VERSION ""

NS_ :

BS_:

BU_: CLU_MM H_U_MM HS_M CGW

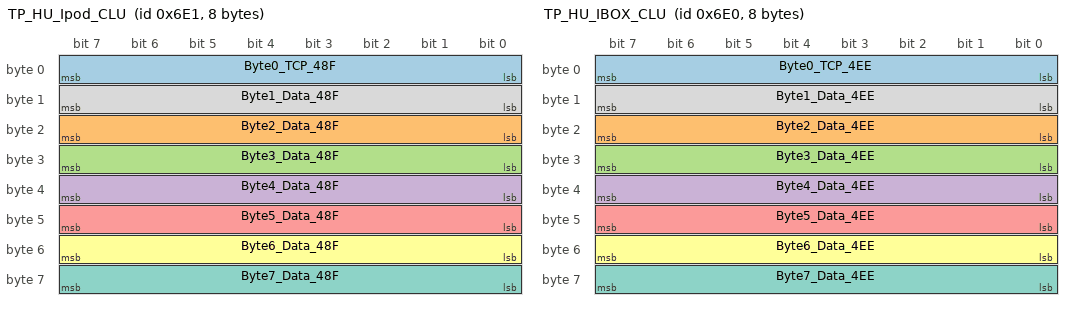
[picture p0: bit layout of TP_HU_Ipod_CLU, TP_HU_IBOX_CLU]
BO_ 1761 TP_HU_Ipod_CLU: 8 H_U_MM
 SG_ Byte0_TCP_48F : 0|8@1+ (1,0) [0|0] ""  CLU_MM
 SG_ Byte2_Data_48F : 16|8@1+ (1,0) [0|0] ""  CLU_MM
 SG_ Byte3_Data_48F : 24|8@1+ (1,0) [0|0] ""  CLU_MM
 SG_ Byte4_Data_48F : 32|8@1+ (1,0) [0|0] ""  CLU_MM
 SG_ Byte5_Data_48F : 40|8@1+ (1,0) [0|0] ""  CLU_MM
 SG_ Byte6_Data_48F : 48|8@1+ (1,0) [0|0] ""  CLU_MM
 SG_ Byte7_Data_48F : 56|8@1+ (1,0) [0|0] ""  CLU_MM
 SG_ Byte1_Data_48F : 8|8@1+ (1,0) [0|0] ""  CLU_MM

BO_ 1760 TP_HU_IBOX_CLU: 8 H_U_MM
 SG_ Byte0_TCP_4EE : 0|8@1+ (1,0) [0|0] ""  CLU_MM
 SG_ Byte2_Data_4EE : 16|8@1+ (1,0) [0|0] ""  CLU_MM
 SG_ Byte3_Data_4EE : 24|8@1+ (1,0) [0|0] ""  CLU_MM
 SG_ Byte4_Data_4EE : 32|8@1+ (1,0) [0|0] ""  CLU_MM
 SG_ Byte5_Data_4EE : 40|8@1+ (1,0) [0|0] ""  CLU_MM
 SG_ Byte6_Data_4EE : 48|8@1+ (1,0) [0|0] ""  CLU_MM
 SG_ Byte7_Data_4EE : 56|8@1+ (1,0) [0|0] ""  CLU_MM
 SG_ Byte1_Data_4EE : 8|8@1+ (1,0) [0|0] ""  CLU_MM

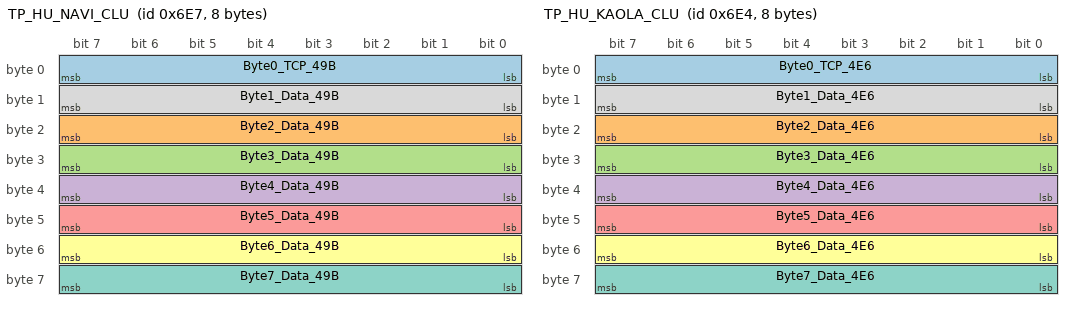
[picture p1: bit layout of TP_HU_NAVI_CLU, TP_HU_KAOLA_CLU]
BO_ 1767 TP_HU_NAVI_CLU: 8 H_U_MM
 SG_ Byte0_TCP_49B : 0|8@1+ (1,0) [0|0] ""  CLU_MM
 SG_ Byte2_Data_49B : 16|8@1+ (1,0) [0|0] ""  CLU_MM
 SG_ Byte3_Data_49B : 24|8@1+ (1,0) [0|0] ""  CLU_MM
 SG_ Byte4_Data_49B : 32|8@1+ (1,0) [0|0] ""  CLU_MM
 SG_ Byte5_Data_49B : 40|8@1+ (1,0) [0|0] ""  CLU_MM
 SG_ Byte6_Data_49B : 48|8@1+ (1,0) [0|0] ""  CLU_MM
 SG_ Byte7_Data_49B : 56|8@1+ (1,0) [0|0] ""  CLU_MM
 SG_ Byte1_Data_49B : 8|8@1+ (1,0) [0|0] ""  CLU_MM

BO_ 1764 TP_HU_KAOLA_CLU: 8 H_U_MM
 SG_ Byte0_TCP_4E6 : 0|8@1+ (1,0) [0|0] ""  CLU_MM
 SG_ Byte2_Data_4E6 : 16|8@1+ (1,0) [0|0] ""  CLU_MM
 SG_ Byte3_Data_4E6 : 24|8@1+ (1,0) [0|0] ""  CLU_MM
 SG_ Byte4_Data_4E6 : 32|8@1+ (1,0) [0|0] ""  CLU_MM
 SG_ Byte5_Data_4E6 : 40|8@1+ (1,0) [0|0] ""  CLU_MM
 SG_ Byte6_Data_4E6 : 48|8@1+ (1,0) [0|0] ""  CLU_MM
 SG_ Byte7_Data_4E6 : 56|8@1+ (1,0) [0|0] ""  CLU_MM
 SG_ Byte1_Data_4E6 : 8|8@1+ (1,0) [0|0] ""  CLU_MM

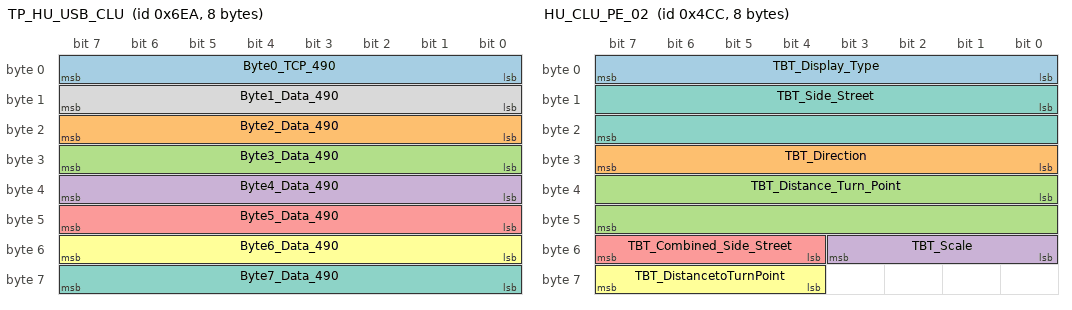
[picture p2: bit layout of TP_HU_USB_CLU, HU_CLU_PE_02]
BO_ 1770 TP_HU_USB_CLU: 8 H_U_MM
 SG_ Byte0_TCP_490 : 0|8@1+ (1,0) [0|0] ""  CLU_MM
 SG_ Byte2_Data_490 : 16|8@1+ (1,0) [0|0] ""  CLU_MM
 SG_ Byte3_Data_490 : 24|8@1+ (1,0) [0|0] ""  CLU_MM
 SG_ Byte4_Data_490 : 32|8@1+ (1,0) [0|0] ""  CLU_MM
 SG_ Byte5_Data_490 : 40|8@1+ (1,0) [0|0] ""  CLU_MM
 SG_ Byte6_Data_490 : 48|8@1+ (1,0) [0|0] ""  CLU_MM
 SG_ Byte7_Data_490 : 56|8@1+ (1,0) [0|0] ""  CLU_MM
 SG_ Byte1_Data_490 : 8|8@1+ (1,0) [0|0] ""  CLU_MM

BO_ 1228 HU_CLU_PE_02: 8 H_U_MM
 SG_ TBT_Display_Type : 0|8@1+ (1,0) [0|0] ""  CLU_MM
 SG_ TBT_Direction : 24|8@1+ (7.5,0) [0|352.5] "Degree"  CLU_MM
 SG_ TBT_Distance_Turn_Point : 32|16@1+ (1,0) [0|0] "m"  CLU_MM
 SG_ TBT_Scale : 48|4@1+ (1,0) [0|0] ""  CLU_MM
 SG_ TBT_Combined_Side_Street : 52|4@1+ (1,0) [0|0] ""  CLU_MM
 SG_ TBT_DistancetoTurnPoint : 60|4@1+ (1,0) [0|0] "times"  CLU_MM
 SG_ TBT_Side_Street : 8|16@1+ (1,0) [0|0] ""  CLU_MM

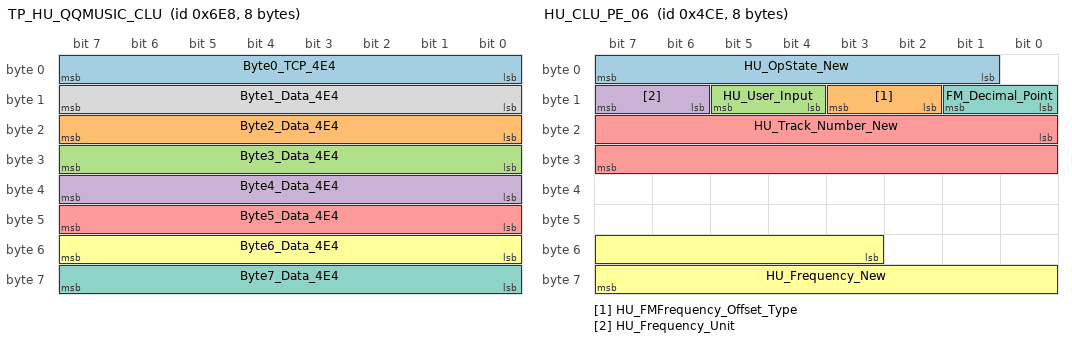
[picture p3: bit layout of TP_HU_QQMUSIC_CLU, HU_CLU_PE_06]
BO_ 1768 TP_HU_QQMUSIC_CLU: 8 H_U_MM
 SG_ Byte0_TCP_4E4 : 0|8@1+ (1,0) [0|0] ""  CLU_MM
 SG_ Byte2_Data_4E4 : 16|8@1+ (1,0) [0|0] ""  CLU_MM
 SG_ Byte3_Data_4E4 : 24|8@1+ (1,0) [0|0] ""  CLU_MM
 SG_ Byte4_Data_4E4 : 32|8@1+ (1,0) [0|0] ""  CLU_MM
 SG_ Byte5_Data_4E4 : 40|8@1+ (1,0) [0|0] ""  CLU_MM
 SG_ Byte6_Data_4E4 : 48|8@1+ (1,0) [0|0] ""  CLU_MM
 SG_ Byte7_Data_4E4 : 56|8@1+ (1,0) [0|0] ""  CLU_MM
 SG_ Byte1_Data_4E4 : 8|8@1+ (1,0) [0|0] ""  CLU_MM

BO_ 1230 HU_CLU_PE_06: 8 H_U_MM
 SG_ HU_OpState_New : 1|7@1+ (1,0) [0|0] ""  CLU_MM
 SG_ HU_FMFrequency_Offset_Type : 10|2@1+ (1,0) [0|0] ""  CLU_MM
 SG_ HU_User_Input : 12|2@1+ (1,0) [0|0] ""  CLU_MM
 SG_ HU_Frequency_Unit : 14|2@1+ (1,0) [0|0] ""  CLU_MM
 SG_ HU_Track_Number_New : 16|16@1+ (1,0) [0|0] ""  CLU_MM
 SG_ HU_Frequency_New : 51|13@1+ (1,0) [0|0] ""  CLU_MM,CGW
 SG_ FM_Decimal_Point : 8|2@1+ (1,0) [0|0] ""  CLU_MM

BO_ 1239 HU_Car_PE_01: 8 H_U_MM
 SG_ HU_VehiclePwr : 4|4@1+ (1,0) [0|0] ""  CLU_MM

BO_ 1246 HU_NAVI_V2_POS_PE: 8 H_U_MM
 SG_ POS_V2_Offset : 0|13@1+ (1,0) [0|0] "m"  CLU_MM,CGW
 SG_ POS_V2_CyclicCounter : 19|2@1+ (1,0) [0|0] ""  CLU_MM,CGW
 SG_ POS_V2_RangeAvgSpeed : 21|9@1+ (1,0) [0|0] "km/h"  CLU_MM,CGW

BO_ 1240 HU_GW_PE_01: 8 H_U_MM
 SG_ CF_AVN_ProfileIDRValue : 40|4@1+ (1,0) [0|0] ""  CLU_MM,CGW
 SG_ HU_AliveStatus : 6|2@1+ (1,0) [0|0] ""  CLU_MM,CGW

BO_ 810 HU_BLE_PE_00: 8 H_U_MM
 SG_ C_BLEOption : 0|2@1+ (1,0) [0|0] ""  CLU_MM,CGW
 SG_ C_BLE_ProfileIDRValue : 12|4@1+ (1,0) [0|0] ""  CLU_MM,CGW
 SG_ C_BLEIDOut : 16|2@1+ (1,0) [0|0] ""  CLU_MM,CGW
 SG_ C_BLEKeyreminder : 22|3@1+ (1,0) [0|0] ""  CLU_MM,CGW

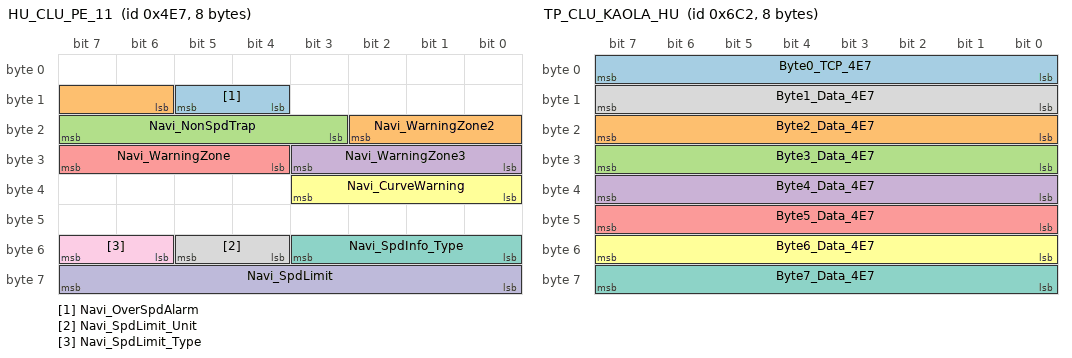
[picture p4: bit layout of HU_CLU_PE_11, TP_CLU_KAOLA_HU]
BO_ 1255 HU_CLU_PE_11: 8 H_U_MM
 SG_ Navi_OverSpdAlarm : 12|2@1+ (1,0) [0|0] ""  CLU_MM
 SG_ Navi_WarningZone2 : 14|5@1+ (1,0) [0|0] ""  CLU_MM
 SG_ Navi_NonSpdTrap : 19|5@1+ (1,0) [0|0] ""  CLU_MM
 SG_ Navi_WarningZone3 : 24|4@1+ (1,0) [0|0] ""  CLU_MM
 SG_ Navi_WarningZone : 28|4@1+ (1,0) [0|0] ""  CLU_MM
 SG_ Navi_CurveWarning : 32|4@1+ (1,0) [0|0] ""  CLU_MM
 SG_ Navi_SpdInfo_Type : 48|4@1+ (1,0) [0|0] ""  CLU_MM
 SG_ Navi_SpdLimit_Unit : 52|2@1+ (1,0) [0|0] ""  CLU_MM
 SG_ Navi_SpdLimit_Type : 54|2@1+ (1,0) [0|0] ""  CLU_MM
 SG_ Navi_SpdLimit : 56|8@1+ (1,0) [1|254] ""  CLU_MM

BO_ 1730 TP_CLU_KAOLA_HU: 8 CLU_MM
 SG_ Byte0_TCP_4E7 : 0|8@1+ (1,0) [0|0] ""  H_U_MM
 SG_ Byte2_Data_4E7 : 16|8@1+ (1,0) [0|0] ""  H_U_MM
 SG_ Byte3_Data_4E7 : 24|8@1+ (1,0) [0|0] ""  H_U_MM
 SG_ Byte4_Data_4E7 : 32|8@1+ (1,0) [0|0] ""  H_U_MM
 SG_ Byte5_Data_4E7 : 40|8@1+ (1,0) [0|0] ""  H_U_MM
 SG_ Byte6_Data_4E7 : 48|8@1+ (1,0) [0|0] ""  H_U_MM
 SG_ Byte7_Data_4E7 : 56|8@1+ (1,0) [0|0] ""  H_U_MM
 SG_ Byte1_Data_4E7 : 8|8@1+ (1,0) [0|0] ""  H_U_MM

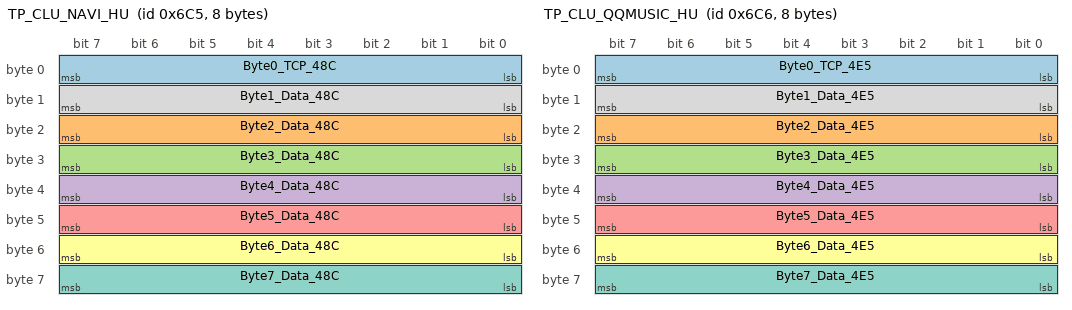
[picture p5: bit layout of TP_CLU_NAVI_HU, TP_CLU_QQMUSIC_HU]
BO_ 1733 TP_CLU_NAVI_HU: 8 CLU_MM
 SG_ Byte0_TCP_48C : 0|8@1+ (1,0) [0|0] ""  H_U_MM
 SG_ Byte2_Data_48C : 16|8@1+ (1,0) [0|0] ""  H_U_MM
 SG_ Byte3_Data_48C : 24|8@1+ (1,0) [0|0] ""  H_U_MM
 SG_ Byte4_Data_48C : 32|8@1+ (1,0) [0|0] ""  H_U_MM
 SG_ Byte5_Data_48C : 40|8@1+ (1,0) [0|0] ""  H_U_MM
 SG_ Byte6_Data_48C : 48|8@1+ (1,0) [0|0] ""  H_U_MM
 SG_ Byte7_Data_48C : 56|8@1+ (1,0) [0|0] ""  H_U_MM
 SG_ Byte1_Data_48C : 8|8@1+ (1,0) [0|0] ""  H_U_MM

BO_ 1734 TP_CLU_QQMUSIC_HU: 8 CLU_MM
 SG_ Byte0_TCP_4E5 : 0|8@1+ (1,0) [0|0] ""  H_U_MM
 SG_ Byte2_Data_4E5 : 16|8@1+ (1,0) [0|0] ""  H_U_MM
 SG_ Byte3_Data_4E5 : 24|8@1+ (1,0) [0|0] ""  H_U_MM
 SG_ Byte4_Data_4E5 : 32|8@1+ (1,0) [0|0] ""  H_U_MM
 SG_ Byte5_Data_4E5 : 40|8@1+ (1,0) [0|0] ""  H_U_MM
 SG_ Byte6_Data_4E5 : 48|8@1+ (1,0) [0|0] ""  H_U_MM
 SG_ Byte7_Data_4E5 : 56|8@1+ (1,0) [0|0] ""  H_U_MM
 SG_ Byte1_Data_4E5 : 8|8@1+ (1,0) [0|0] ""  H_U_MM

BO_ 1600 HU_CLU_PE_07: 8 H_U_MM
 SG_ NV_Display_TG : 24|2@1+ (1,0) [0|0] ""  CLU_MM
 SG_ TBT_BarGraph100Level : 56|8@1+ (1,0) [0|100] "%"  CLU_MM

BO_ 1601 HU_CLU_PE_10: 8 H_U_MM
 SG_ Navi_WarnDist_OverDec : 0|16@1+ (1,0) [0|0] ""  CLU_MM
 SG_ Navi_WarnDist_Scale : 16|4@1+ (1,0) [0|0] ""  CLU_MM
 SG_ Navi_WarnDist_UnderDec : 20|4@1+ (1,0) [0|0] ""  CLU_MM

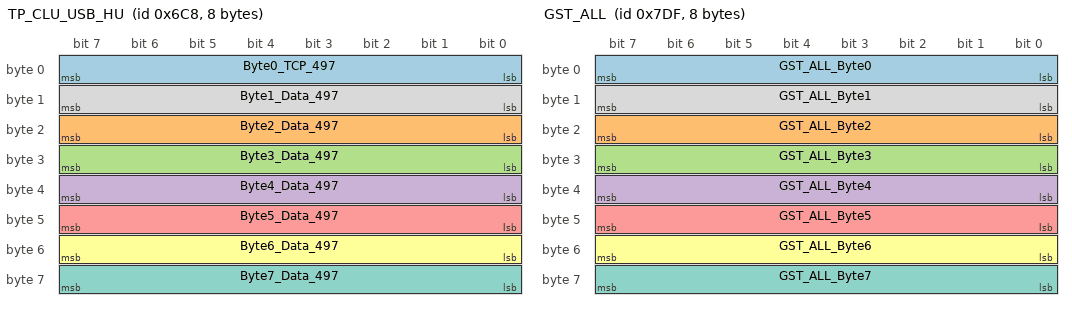
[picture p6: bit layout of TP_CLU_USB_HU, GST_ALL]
BO_ 1736 TP_CLU_USB_HU: 8 CLU_MM
 SG_ Byte0_TCP_497 : 0|8@1+ (1,0) [0|0] ""  H_U_MM
 SG_ Byte2_Data_497 : 16|8@1+ (1,0) [0|0] ""  H_U_MM
 SG_ Byte3_Data_497 : 24|8@1+ (1,0) [0|0] ""  H_U_MM
 SG_ Byte4_Data_497 : 32|8@1+ (1,0) [0|0] ""  H_U_MM
 SG_ Byte5_Data_497 : 40|8@1+ (1,0) [0|0] ""  H_U_MM
 SG_ Byte6_Data_497 : 48|8@1+ (1,0) [0|0] ""  H_U_MM
 SG_ Byte7_Data_497 : 56|8@1+ (1,0) [0|0] ""  H_U_MM
 SG_ Byte1_Data_497 : 8|8@1+ (1,0) [0|0] ""  H_U_MM

BO_ 2015 GST_ALL: 8 CGW
 SG_ GST_ALL_Byte0 : 0|8@1+ (1,0) [0|0] ""  H_U_MM,CLU_MM,HS_M
 SG_ GST_ALL_Byte2 : 16|8@1+ (1,0) [0|0] ""  H_U_MM,CLU_MM,HS_M
 SG_ GST_ALL_Byte3 : 24|8@1+ (1,0) [0|0] ""  H_U_MM,CLU_MM,HS_M
 SG_ GST_ALL_Byte4 : 32|8@1+ (1,0) [0|0] ""  H_U_MM,CLU_MM,HS_M
 SG_ GST_ALL_Byte5 : 40|8@1+ (1,0) [0|0] ""  H_U_MM,CLU_MM,HS_M
 SG_ GST_ALL_Byte6 : 48|8@1+ (1,0) [0|0] ""  H_U_MM,CLU_MM,HS_M
 SG_ GST_ALL_Byte7 : 56|8@1+ (1,0) [0|0] ""  H_U_MM,CLU_MM,HS_M
 SG_ GST_ALL_Byte1 : 8|8@1+ (1,0) [0|0] ""  H_U_MM,CLU_MM,HS_M

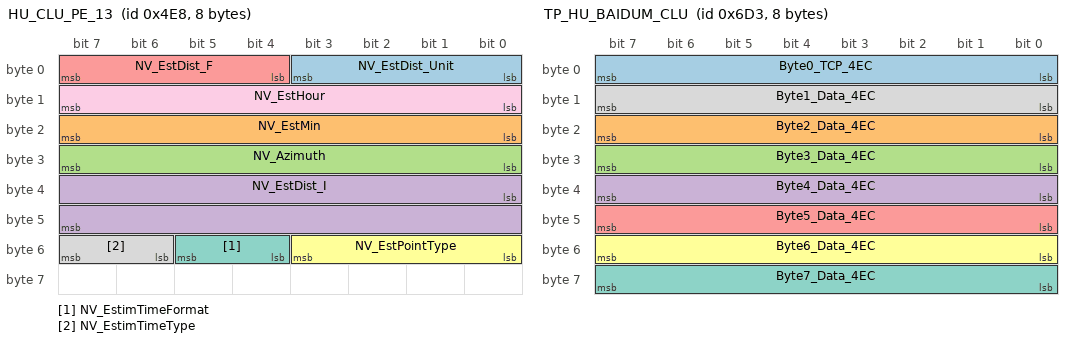
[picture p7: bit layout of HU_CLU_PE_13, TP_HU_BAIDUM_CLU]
BO_ 1256 HU_CLU_PE_13: 8 H_U_MM
 SG_ NV_EstDist_Unit : 0|4@1+ (1,0) [0|0] ""  CLU_MM
 SG_ NV_EstMin : 16|8@1+ (1,0) [0|0] ""  CLU_MM
 SG_ NV_Azimuth : 24|8@1+ (7.5,0) [0|352.5] "Degree"  CLU_MM
 SG_ NV_EstDist_I : 32|16@1+ (1,0) [0|0] ""  CLU_MM
 SG_ NV_EstDist_F : 4|4@1+ (1,0) [0|0] ""  CLU_MM
 SG_ NV_EstPointType : 48|4@1+ (1,0) [0|0] ""  CLU_MM
 SG_ NV_EstimTimeFormat : 52|2@1+ (1,0) [0|0] ""  CLU_MM
 SG_ NV_EstimTimeType : 54|2@1+ (1,0) [0|0] ""  CLU_MM
 SG_ NV_EstHour : 8|8@1+ (1,0) [0|0] ""  CLU_MM

BO_ 1747 TP_HU_BAIDUM_CLU: 8 H_U_MM
 SG_ Byte0_TCP_4EC : 0|8@1+ (1,0) [0|0] ""  CLU_MM
 SG_ Byte2_Data_4EC : 16|8@1+ (1,0) [0|0] ""  CLU_MM
 SG_ Byte3_Data_4EC : 24|8@1+ (1,0) [0|0] ""  CLU_MM
 SG_ Byte4_Data_4EC : 32|8@1+ (1,0) [0|0] ""  CLU_MM
 SG_ Byte5_Data_4EC : 40|8@1+ (1,0) [0|0] ""  CLU_MM
 SG_ Byte6_Data_4EC : 48|8@1+ (1,0) [0|0] ""  CLU_MM
 SG_ Byte7_Data_4EC : 56|8@1+ (1,0) [0|0] ""  CLU_MM
 SG_ Byte1_Data_4EC : 8|8@1+ (1,0) [0|0] ""  CLU_MM

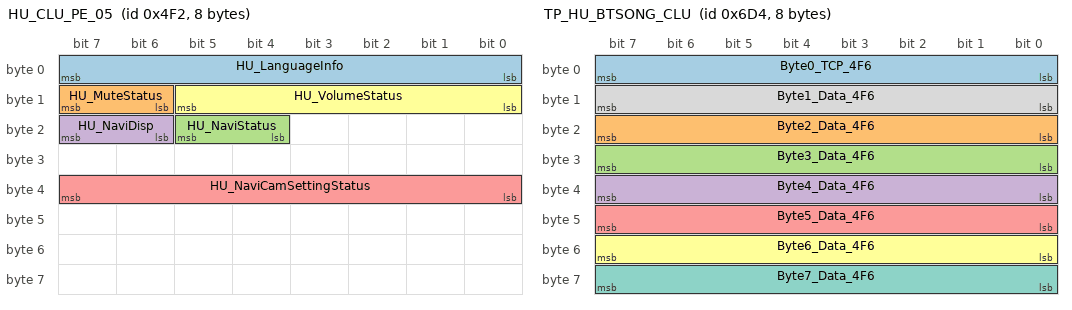
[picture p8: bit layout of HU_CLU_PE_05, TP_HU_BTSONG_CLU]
BO_ 1266 HU_CLU_PE_05: 8 H_U_MM
 SG_ HU_LanguageInfo : 0|8@1+ (1,0) [0|0] ""  CLU_MM
 SG_ HU_MuteStatus : 14|2@1+ (1,0) [0|0] ""  CLU_MM
 SG_ HU_NaviStatus : 20|2@1+ (1,0) [0|0] ""  CLU_MM,CGW
 SG_ HU_NaviDisp : 22|2@1+ (1,0) [0|0] ""  CLU_MM
 SG_ HU_NaviCamSettingStatus : 32|8@1+ (1,0) [0|0] ""  CLU_MM,CGW
 SG_ HU_VolumeStatus : 8|6@1+ (1,0) [0|0] ""  CLU_MM

BO_ 1748 TP_HU_BTSONG_CLU: 8 H_U_MM
 SG_ Byte0_TCP_4F6 : 0|8@1+ (1,0) [0|0] ""  CLU_MM
 SG_ Byte2_Data_4F6 : 16|8@1+ (1,0) [0|0] ""  CLU_MM
 SG_ Byte3_Data_4F6 : 24|8@1+ (1,0) [0|0] ""  CLU_MM
 SG_ Byte4_Data_4F6 : 32|8@1+ (1,0) [0|0] ""  CLU_MM
 SG_ Byte5_Data_4F6 : 40|8@1+ (1,0) [0|0] ""  CLU_MM
 SG_ Byte6_Data_4F6 : 48|8@1+ (1,0) [0|0] ""  CLU_MM
 SG_ Byte7_Data_4F6 : 56|8@1+ (1,0) [0|0] ""  CLU_MM
 SG_ Byte1_Data_4F6 : 8|8@1+ (1,0) [0|0] ""  CLU_MM

BO_ 1267 HU_DATC_PE_00: 8 H_U_MM
 SG_ HU_PhoneActivity : 36|2@1+ (1,0) [0|0] ""  CLU_MM,CGW
 SG_ HU_VRActivity : 38|2@1+ (1,0) [0|0] ""  CLU_MM,CGW

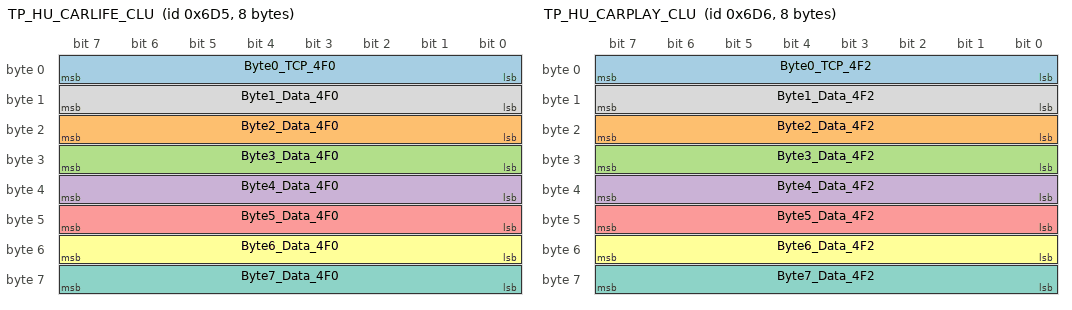
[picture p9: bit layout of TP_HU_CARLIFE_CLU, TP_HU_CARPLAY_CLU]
BO_ 1749 TP_HU_CARLIFE_CLU: 8 H_U_MM
 SG_ Byte0_TCP_4F0 : 0|8@1+ (1,0) [0|0] ""  CLU_MM
 SG_ Byte2_Data_4F0 : 16|8@1+ (1,0) [0|0] ""  CLU_MM
 SG_ Byte3_Data_4F0 : 24|8@1+ (1,0) [0|0] ""  CLU_MM
 SG_ Byte4_Data_4F0 : 32|8@1+ (1,0) [0|0] ""  CLU_MM
 SG_ Byte5_Data_4F0 : 40|8@1+ (1,0) [0|0] ""  CLU_MM
 SG_ Byte6_Data_4F0 : 48|8@1+ (1,0) [0|0] ""  CLU_MM
 SG_ Byte7_Data_4F0 : 56|8@1+ (1,0) [0|0] ""  CLU_MM
 SG_ Byte1_Data_4F0 : 8|8@1+ (1,0) [0|0] ""  CLU_MM

BO_ 1750 TP_HU_CARPLAY_CLU: 8 H_U_MM
 SG_ Byte0_TCP_4F2 : 0|8@1+ (1,0) [0|0] ""  CLU_MM
 SG_ Byte2_Data_4F2 : 16|8@1+ (1,0) [0|0] ""  CLU_MM
 SG_ Byte3_Data_4F2 : 24|8@1+ (1,0) [0|0] ""  CLU_MM
 SG_ Byte4_Data_4F2 : 32|8@1+ (1,0) [0|0] ""  CLU_MM
 SG_ Byte5_Data_4F2 : 40|8@1+ (1,0) [0|0] ""  CLU_MM
 SG_ Byte6_Data_4F2 : 48|8@1+ (1,0) [0|0] ""  CLU_MM
 SG_ Byte7_Data_4F2 : 56|8@1+ (1,0) [0|0] ""  CLU_MM
 SG_ Byte1_Data_4F2 : 8|8@1+ (1,0) [0|0] ""  CLU_MM

BO_ 1278 HU_MON_PE_01: 8 H_U_MM
 SG_ HU_Type : 0|8@1+ (1,0) [0|0] ""  CLU_MM,CGW
 SG_ HU_DistributeInfo : 24|8@1+ (1,0) [0|0] ""  CLU_MM,CGW
 SG_ HU_OptionInfo : 32|16@1+ (1,0) [0|0] ""  CLU_MM
 SG_ HU_AdasSupport : 61|3@1+ (1,0) [0|0] ""  CLU_MM,CGW

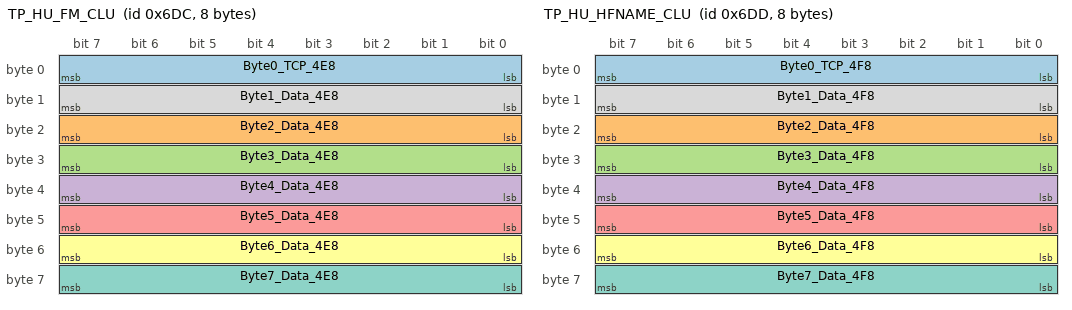
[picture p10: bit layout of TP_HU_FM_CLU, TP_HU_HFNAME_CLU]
BO_ 1756 TP_HU_FM_CLU: 8 H_U_MM
 SG_ Byte0_TCP_4E8 : 0|8@1+ (1,0) [0|0] ""  CLU_MM
 SG_ Byte2_Data_4E8 : 16|8@1+ (1,0) [0|0] ""  CLU_MM
 SG_ Byte3_Data_4E8 : 24|8@1+ (1,0) [0|0] ""  CLU_MM
 SG_ Byte4_Data_4E8 : 32|8@1+ (1,0) [0|0] ""  CLU_MM
 SG_ Byte5_Data_4E8 : 40|8@1+ (1,0) [0|0] ""  CLU_MM
 SG_ Byte6_Data_4E8 : 48|8@1+ (1,0) [0|0] ""  CLU_MM
 SG_ Byte7_Data_4E8 : 56|8@1+ (1,0) [0|0] ""  CLU_MM
 SG_ Byte1_Data_4E8 : 8|8@1+ (1,0) [0|0] ""  CLU_MM

BO_ 1757 TP_HU_HFNAME_CLU: 8 H_U_MM
 SG_ Byte0_TCP_4F8 : 0|8@1+ (1,0) [0|0] ""  CLU_MM
 SG_ Byte2_Data_4F8 : 16|8@1+ (1,0) [0|0] ""  CLU_MM
 SG_ Byte3_Data_4F8 : 24|8@1+ (1,0) [0|0] ""  CLU_MM
 SG_ Byte4_Data_4F8 : 32|8@1+ (1,0) [0|0] ""  CLU_MM
 SG_ Byte5_Data_4F8 : 40|8@1+ (1,0) [0|0] ""  CLU_MM
 SG_ Byte6_Data_4F8 : 48|8@1+ (1,0) [0|0] ""  CLU_MM
 SG_ Byte7_Data_4F8 : 56|8@1+ (1,0) [0|0] ""  CLU_MM
 SG_ Byte1_Data_4F8 : 8|8@1+ (1,0) [0|0] ""  CLU_MM

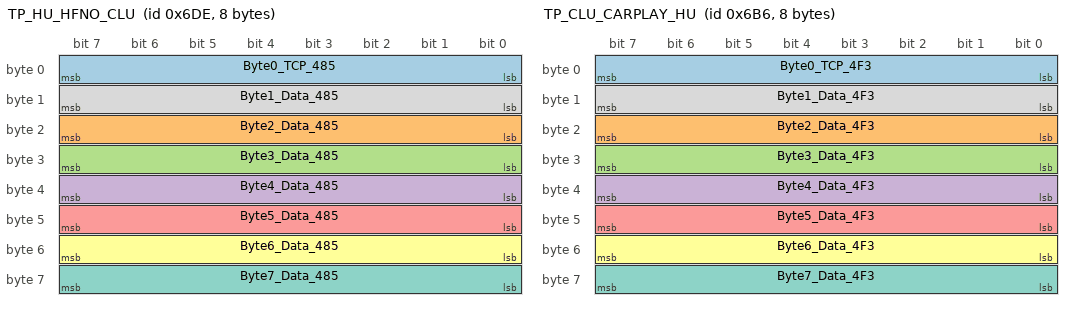
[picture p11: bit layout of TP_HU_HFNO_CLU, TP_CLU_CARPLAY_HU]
BO_ 1758 TP_HU_HFNO_CLU: 8 H_U_MM
 SG_ Byte0_TCP_485 : 0|8@1+ (1,0) [0|0] ""  CLU_MM
 SG_ Byte2_Data_485 : 16|8@1+ (1,0) [0|0] ""  CLU_MM
 SG_ Byte3_Data_485 : 24|8@1+ (1,0) [0|0] ""  CLU_MM
 SG_ Byte4_Data_485 : 32|8@1+ (1,0) [0|0] ""  CLU_MM
 SG_ Byte5_Data_485 : 40|8@1+ (1,0) [0|0] ""  CLU_MM
 SG_ Byte6_Data_485 : 48|8@1+ (1,0) [0|0] ""  CLU_MM
 SG_ Byte7_Data_485 : 56|8@1+ (1,0) [0|0] ""  CLU_MM
 SG_ Byte1_Data_485 : 8|8@1+ (1,0) [0|0] ""  CLU_MM

BO_ 1718 TP_CLU_CARPLAY_HU: 8 CLU_MM
 SG_ Byte0_TCP_4F3 : 0|8@1+ (1,0) [0|0] ""  H_U_MM
 SG_ Byte2_Data_4F3 : 16|8@1+ (1,0) [0|0] ""  H_U_MM
 SG_ Byte3_Data_4F3 : 24|8@1+ (1,0) [0|0] ""  H_U_MM
 SG_ Byte4_Data_4F3 : 32|8@1+ (1,0) [0|0] ""  H_U_MM
 SG_ Byte5_Data_4F3 : 40|8@1+ (1,0) [0|0] ""  H_U_MM
 SG_ Byte6_Data_4F3 : 48|8@1+ (1,0) [0|0] ""  H_U_MM
 SG_ Byte7_Data_4F3 : 56|8@1+ (1,0) [0|0] ""  H_U_MM
 SG_ Byte1_Data_4F3 : 8|8@1+ (1,0) [0|0] ""  H_U_MM

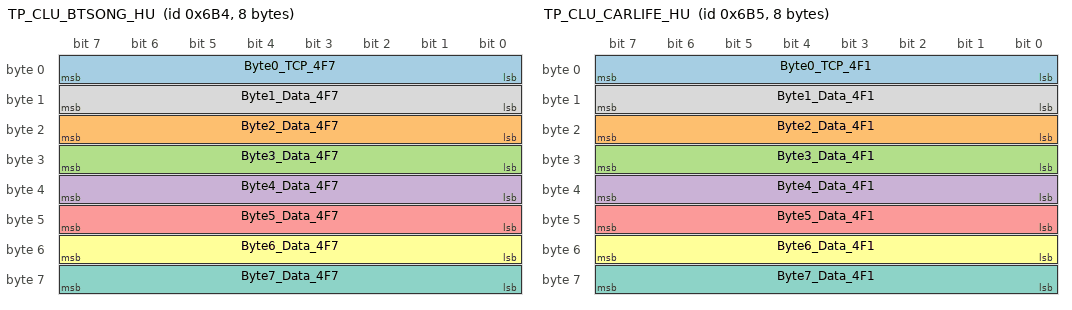
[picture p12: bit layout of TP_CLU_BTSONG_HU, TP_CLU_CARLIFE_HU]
BO_ 1716 TP_CLU_BTSONG_HU: 8 CLU_MM
 SG_ Byte0_TCP_4F7 : 0|8@1+ (1,0) [0|0] ""  H_U_MM
 SG_ Byte2_Data_4F7 : 16|8@1+ (1,0) [0|0] ""  H_U_MM
 SG_ Byte3_Data_4F7 : 24|8@1+ (1,0) [0|0] ""  H_U_MM
 SG_ Byte4_Data_4F7 : 32|8@1+ (1,0) [0|0] ""  H_U_MM
 SG_ Byte5_Data_4F7 : 40|8@1+ (1,0) [0|0] ""  H_U_MM
 SG_ Byte6_Data_4F7 : 48|8@1+ (1,0) [0|0] ""  H_U_MM
 SG_ Byte7_Data_4F7 : 56|8@1+ (1,0) [0|0] ""  H_U_MM
 SG_ Byte1_Data_4F7 : 8|8@1+ (1,0) [0|0] ""  H_U_MM

BO_ 1717 TP_CLU_CARLIFE_HU: 8 CLU_MM
 SG_ Byte0_TCP_4F1 : 0|8@1+ (1,0) [0|0] ""  H_U_MM
 SG_ Byte2_Data_4F1 : 16|8@1+ (1,0) [0|0] ""  H_U_MM
 SG_ Byte3_Data_4F1 : 24|8@1+ (1,0) [0|0] ""  H_U_MM
 SG_ Byte4_Data_4F1 : 32|8@1+ (1,0) [0|0] ""  H_U_MM
 SG_ Byte5_Data_4F1 : 40|8@1+ (1,0) [0|0] ""  H_U_MM
 SG_ Byte6_Data_4F1 : 48|8@1+ (1,0) [0|0] ""  H_U_MM
 SG_ Byte7_Data_4F1 : 56|8@1+ (1,0) [0|0] ""  H_U_MM
 SG_ Byte1_Data_4F1 : 8|8@1+ (1,0) [0|0] ""  H_U_MM

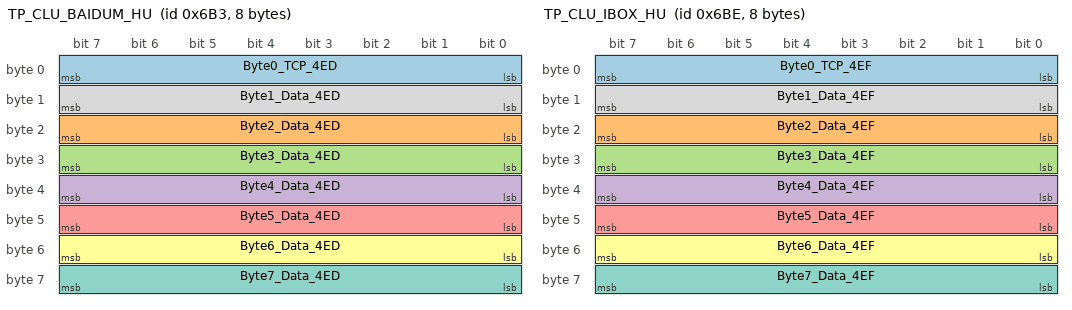
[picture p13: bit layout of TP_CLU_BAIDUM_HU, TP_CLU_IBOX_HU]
BO_ 1715 TP_CLU_BAIDUM_HU: 8 CLU_MM
 SG_ Byte0_TCP_4ED : 0|8@1+ (1,0) [0|0] ""  H_U_MM
 SG_ Byte2_Data_4ED : 16|8@1+ (1,0) [0|0] ""  H_U_MM
 SG_ Byte3_Data_4ED : 24|8@1+ (1,0) [0|0] ""  H_U_MM
 SG_ Byte4_Data_4ED : 32|8@1+ (1,0) [0|0] ""  H_U_MM
 SG_ Byte5_Data_4ED : 40|8@1+ (1,0) [0|0] ""  H_U_MM
 SG_ Byte6_Data_4ED : 48|8@1+ (1,0) [0|0] ""  H_U_MM
 SG_ Byte7_Data_4ED : 56|8@1+ (1,0) [0|0] ""  H_U_MM
 SG_ Byte1_Data_4ED : 8|8@1+ (1,0) [0|0] ""  H_U_MM

BO_ 1726 TP_CLU_IBOX_HU: 8 CLU_MM
 SG_ Byte0_TCP_4EF : 0|8@1+ (1,0) [0|0] ""  H_U_MM
 SG_ Byte2_Data_4EF : 16|8@1+ (1,0) [0|0] ""  H_U_MM
 SG_ Byte3_Data_4EF : 24|8@1+ (1,0) [0|0] ""  H_U_MM
 SG_ Byte4_Data_4EF : 32|8@1+ (1,0) [0|0] ""  H_U_MM
 SG_ Byte5_Data_4EF : 40|8@1+ (1,0) [0|0] ""  H_U_MM
 SG_ Byte6_Data_4EF : 48|8@1+ (1,0) [0|0] ""  H_U_MM
 SG_ Byte7_Data_4EF : 56|8@1+ (1,0) [0|0] ""  H_U_MM
 SG_ Byte1_Data_4EF : 8|8@1+ (1,0) [0|0] ""  H_U_MM

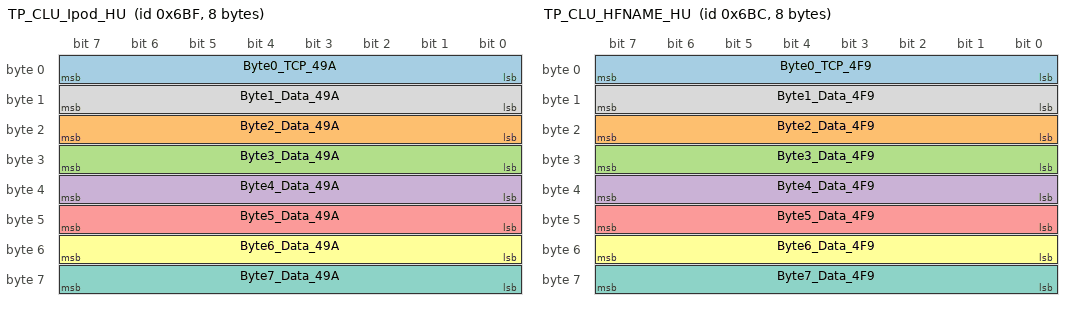
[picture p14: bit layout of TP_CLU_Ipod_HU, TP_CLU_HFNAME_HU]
BO_ 1727 TP_CLU_Ipod_HU: 8 CLU_MM
 SG_ Byte0_TCP_49A : 0|8@1+ (1,0) [0|0] ""  H_U_MM
 SG_ Byte2_Data_49A : 16|8@1+ (1,0) [0|0] ""  H_U_MM
 SG_ Byte3_Data_49A : 24|8@1+ (1,0) [0|0] ""  H_U_MM
 SG_ Byte4_Data_49A : 32|8@1+ (1,0) [0|0] ""  H_U_MM
 SG_ Byte5_Data_49A : 40|8@1+ (1,0) [0|0] ""  H_U_MM
 SG_ Byte6_Data_49A : 48|8@1+ (1,0) [0|0] ""  H_U_MM
 SG_ Byte7_Data_49A : 56|8@1+ (1,0) [0|0] ""  H_U_MM
 SG_ Byte1_Data_49A : 8|8@1+ (1,0) [0|0] ""  H_U_MM

BO_ 1724 TP_CLU_HFNAME_HU: 8 CLU_MM
 SG_ Byte0_TCP_4F9 : 0|8@1+ (1,0) [0|0] ""  H_U_MM
 SG_ Byte2_Data_4F9 : 16|8@1+ (1,0) [0|0] ""  H_U_MM
 SG_ Byte3_Data_4F9 : 24|8@1+ (1,0) [0|0] ""  H_U_MM
 SG_ Byte4_Data_4F9 : 32|8@1+ (1,0) [0|0] ""  H_U_MM
 SG_ Byte5_Data_4F9 : 40|8@1+ (1,0) [0|0] ""  H_U_MM
 SG_ Byte6_Data_4F9 : 48|8@1+ (1,0) [0|0] ""  H_U_MM
 SG_ Byte7_Data_4F9 : 56|8@1+ (1,0) [0|0] ""  H_U_MM
 SG_ Byte1_Data_4F9 : 8|8@1+ (1,0) [0|0] ""  H_U_MM

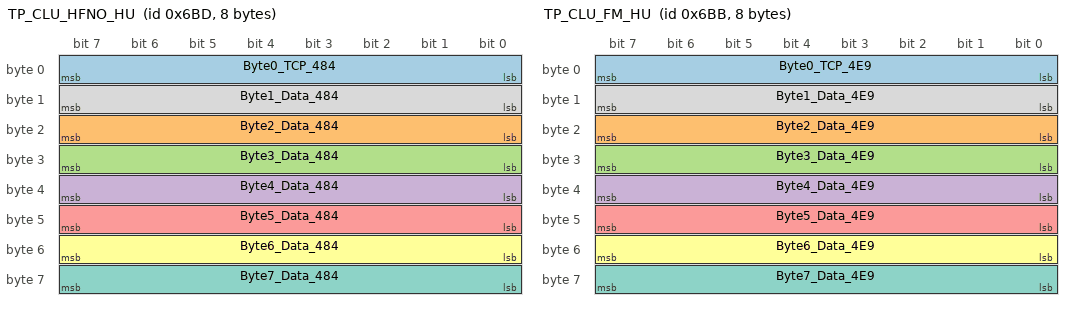
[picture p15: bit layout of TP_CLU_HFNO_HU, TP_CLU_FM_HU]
BO_ 1725 TP_CLU_HFNO_HU: 8 CLU_MM
 SG_ Byte0_TCP_484 : 0|8@1+ (1,0) [0|0] ""  H_U_MM
 SG_ Byte2_Data_484 : 16|8@1+ (1,0) [0|0] ""  H_U_MM
 SG_ Byte3_Data_484 : 24|8@1+ (1,0) [0|0] ""  H_U_MM
 SG_ Byte4_Data_484 : 32|8@1+ (1,0) [0|0] ""  H_U_MM
 SG_ Byte5_Data_484 : 40|8@1+ (1,0) [0|0] ""  H_U_MM
 SG_ Byte6_Data_484 : 48|8@1+ (1,0) [0|0] ""  H_U_MM
 SG_ Byte7_Data_484 : 56|8@1+ (1,0) [0|0] ""  H_U_MM
 SG_ Byte1_Data_484 : 8|8@1+ (1,0) [0|0] ""  H_U_MM

BO_ 1723 TP_CLU_FM_HU: 8 CLU_MM
 SG_ Byte0_TCP_4E9 : 0|8@1+ (1,0) [0|0] ""  H_U_MM
 SG_ Byte2_Data_4E9 : 16|8@1+ (1,0) [0|0] ""  H_U_MM
 SG_ Byte3_Data_4E9 : 24|8@1+ (1,0) [0|0] ""  H_U_MM
 SG_ Byte4_Data_4E9 : 32|8@1+ (1,0) [0|0] ""  H_U_MM
 SG_ Byte5_Data_4E9 : 40|8@1+ (1,0) [0|0] ""  H_U_MM
 SG_ Byte6_Data_4E9 : 48|8@1+ (1,0) [0|0] ""  H_U_MM
 SG_ Byte7_Data_4E9 : 56|8@1+ (1,0) [0|0] ""  H_U_MM
 SG_ Byte1_Data_4E9 : 8|8@1+ (1,0) [0|0] ""  H_U_MM

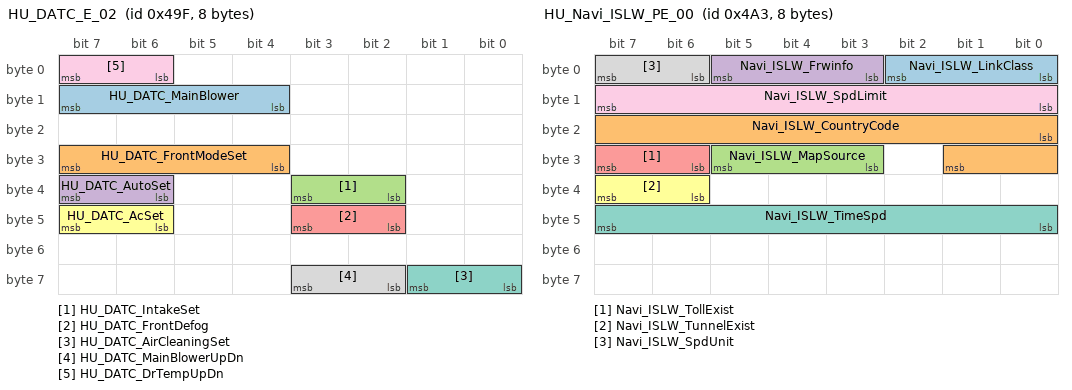
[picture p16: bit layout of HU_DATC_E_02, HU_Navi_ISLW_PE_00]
BO_ 1183 HU_DATC_E_02: 8 H_U_MM
 SG_ HU_DATC_MainBlower : 12|4@1+ (1,0) [0|0] ""  CLU_MM,CGW
 SG_ HU_DATC_FrontModeSet : 28|4@1+ (1,0) [0|0] ""  CLU_MM,CGW
 SG_ HU_DATC_IntakeSet : 34|2@1+ (1,0) [0|0] ""  CLU_MM,CGW
 SG_ HU_DATC_AutoSet : 38|2@1+ (1,0) [0|0] ""  CLU_MM,CGW
 SG_ HU_DATC_FrontDefog : 42|2@1+ (1,0) [0|0] ""  CLU_MM,CGW
 SG_ HU_DATC_AcSet : 46|2@1+ (1,0) [0|0] ""  CLU_MM,CGW
 SG_ HU_DATC_AirCleaningSet : 56|2@1+ (1,0) [0|0] ""  CLU_MM,CGW
 SG_ HU_DATC_MainBlowerUpDn : 58|2@1+ (1,0) [0|0] ""  CLU_MM,CGW
 SG_ HU_DATC_DrTempUpDn : 6|2@1+ (1,0) [0|0] ""  CLU_MM,CGW

BO_ 1187 HU_Navi_ISLW_PE_00: 8 H_U_MM
 SG_ Navi_ISLW_LinkClass : 0|3@1+ (1,0) [0|0] ""  CLU_MM,CGW
 SG_ Navi_ISLW_CountryCode : 16|10@1+ (1,0) [0|0] ""  CLU_MM,CGW
 SG_ Navi_ISLW_MapSource : 27|3@1+ (1,0) [0|0] ""  CLU_MM,CGW
 SG_ Navi_ISLW_Frwinfo : 3|3@1+ (1,0) [0|0] ""  CLU_MM,CGW
 SG_ Navi_ISLW_TollExist : 30|2@1+ (1,0) [0|0] ""  CLU_MM,CGW
 SG_ Navi_ISLW_TunnelExist : 38|2@1+ (1,0) [0|0] ""  CLU_MM,CGW
 SG_ Navi_ISLW_TimeSpd : 40|8@1+ (1,0) [0|0] ""  CLU_MM,CGW
 SG_ Navi_ISLW_SpdUnit : 6|2@1+ (1,0) [0|0] ""  CLU_MM,CGW
 SG_ Navi_ISLW_SpdLimit : 8|8@1+ (1,0) [0|0] ""  CLU_MM,CGW

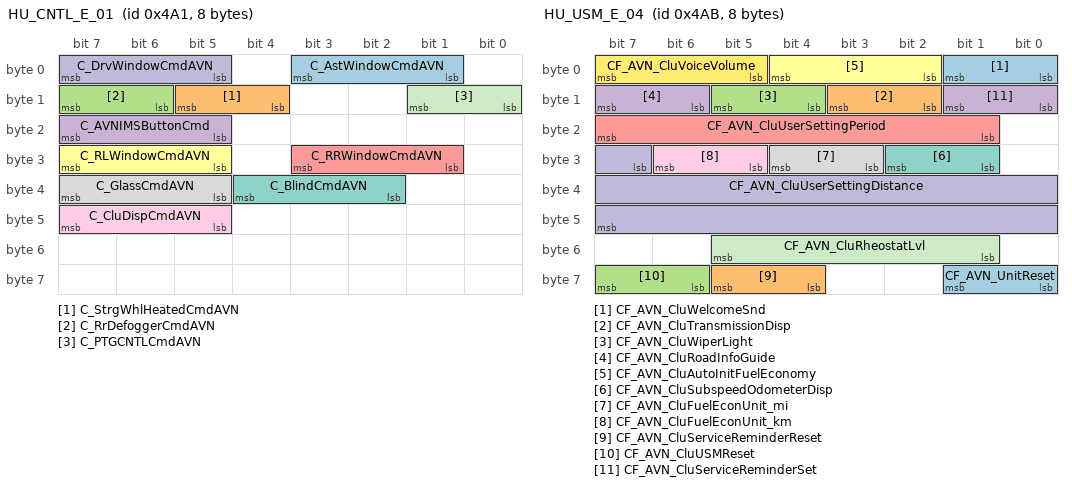
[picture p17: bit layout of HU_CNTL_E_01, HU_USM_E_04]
BO_ 1185 HU_CNTL_E_01: 8 H_U_MM
 SG_ C_AstWindowCmdAVN : 1|3@1+ (1,0) [0|0] ""  CLU_MM
 SG_ C_StrgWhlHeatedCmdAVN : 12|2@1+ (1,0) [0|0] ""  CLU_MM
 SG_ C_RrDefoggerCmdAVN : 14|2@1+ (1,0) [0|0] ""  CLU_MM
 SG_ C_AVNIMSButtonCmd : 21|3@1+ (1,0) [0|0] ""  CLU_MM
 SG_ C_RRWindowCmdAVN : 25|3@1+ (1,0) [0|0] ""  CLU_MM
 SG_ C_RLWindowCmdAVN : 29|3@1+ (1,0) [0|0] ""  CLU_MM
 SG_ C_BlindCmdAVN : 34|3@1+ (1,0) [0|0] ""  CLU_MM,CGW
 SG_ C_GlassCmdAVN : 37|3@1+ (1,0) [0|0] ""  CLU_MM,CGW
 SG_ C_CluDispCmdAVN : 45|3@1+ (1,0) [0|0] ""  CLU_MM
 SG_ C_DrvWindowCmdAVN : 5|3@1+ (1,0) [0|0] ""  CLU_MM,CGW
 SG_ C_PTGCNTLCmdAVN : 8|2@1+ (1,0) [0|0] ""  CLU_MM

BO_ 1184 HU_DATC_E_03: 8 H_U_MM
 SG_ HU_DATC_DrTempSetC : 0|8@1+ (0.5,14) [15|32] "℃"  CLU_MM,CGW
 SG_ HU_DATC_DrTempSetF : 8|8@1+ (1,56) [58|90] "℉"  CLU_MM,CGW

BO_ 1195 HU_USM_E_04: 8 H_U_MM
 SG_ CF_AVN_CluWelcomeSnd : 0|2@1+ (1,0) [0|0] ""  CLU_MM
 SG_ CF_AVN_CluTransmissionDisp : 10|2@1+ (1,0) [0|0] ""  CLU_MM
 SG_ CF_AVN_CluWiperLight : 12|2@1+ (1,0) [0|0] ""  CLU_MM
 SG_ CF_AVN_CluRoadInfoGuide : 14|2@1+ (1,0) [0|0] ""  CLU_MM
 SG_ CF_AVN_CluUserSettingPeriod : 17|7@1+ (1,0) [0|0] ""  CLU_MM
 SG_ CF_AVN_CluAutoInitFuelEconomy : 2|3@1+ (1,0) [0|0] ""  CLU_MM
 SG_ CF_AVN_CluSubspeedOdometerDisp : 25|2@1+ (1,0) [0|0] ""  CLU_MM
 SG_ CF_AVN_CluFuelEconUnit_mi : 27|2@1+ (1,0) [0|0] ""  CLU_MM
 SG_ CF_AVN_CluFuelEconUnit_km : 29|2@1+ (1,0) [0|0] ""  CLU_MM
 SG_ CF_AVN_CluUserSettingDistance : 31|17@1+ (1,0) [0|0] ""  CLU_MM
 SG_ CF_AVN_CluRheostatLvl : 49|5@1+ (1,0) [0|0] ""  CLU_MM
 SG_ CF_AVN_CluVoiceVolume : 5|3@1+ (1,0) [0|0] ""  CLU_MM
 SG_ CF_AVN_UnitReset : 56|2@1+ (1,0) [0|0] ""  CLU_MM,CGW
 SG_ CF_AVN_CluServiceReminderReset : 60|2@1+ (1,0) [0|0] ""  CLU_MM
 SG_ CF_AVN_CluUSMReset : 62|2@1+ (1,0) [0|0] ""  CLU_MM,CGW
 SG_ CF_AVN_CluServiceReminderSet : 8|2@1+ (1,0) [0|0] ""  CLU_MM

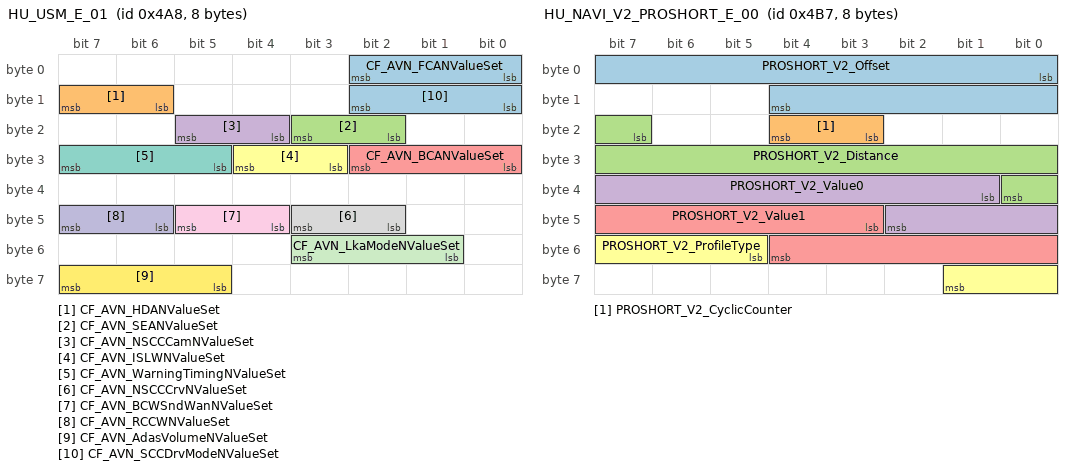
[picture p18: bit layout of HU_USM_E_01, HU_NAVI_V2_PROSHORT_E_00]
BO_ 1192 HU_USM_E_01: 8 H_U_MM
 SG_ CF_AVN_FCANValueSet : 0|3@1+ (1,0) [0|0] ""  CLU_MM
 SG_ CF_AVN_HDANValueSet : 14|2@1+ (1,0) [0|0] ""  CLU_MM
 SG_ CF_AVN_SEANValueSet : 18|2@1+ (1,0) [0|0] ""  CLU_MM
 SG_ CF_AVN_NSCCCamNValueSet : 20|2@1+ (1,0) [0|0] ""  CLU_MM
 SG_ CF_AVN_BCANValueSet : 24|3@1+ (1,0) [0|0] ""  CLU_MM
 SG_ CF_AVN_ISLWNValueSet : 27|2@1+ (1,0) [0|0] ""  CLU_MM
 SG_ CF_AVN_WarningTimingNValueSet : 29|3@1+ (1,0) [0|0] ""  CLU_MM
 SG_ CF_AVN_NSCCCrvNValueSet : 42|2@1+ (1,0) [0|0] ""  CLU_MM
 SG_ CF_AVN_BCWSndWanNValueSet : 44|2@1+ (1,0) [0|0] ""  CLU_MM
 SG_ CF_AVN_RCCWNValueSet : 46|2@1+ (1,0) [0|0] ""  CLU_MM
 SG_ CF_AVN_LkaModeNValueSet : 49|3@1+ (1,0) [0|0] ""  CLU_MM
 SG_ CF_AVN_AdasVolumeNValueSet : 61|3@1+ (1,0) [0|0] ""  CLU_MM
 SG_ CF_AVN_SCCDrvModeNValueSet : 8|3@1+ (1,0) [0|0] ""  CLU_MM

BO_ 1197 HU_USM_E_06: 8 H_U_MM
 SG_ CF_AVN_HBANValueSet : 40|2@1+ (1,0) [0|0] ""  CLU_MM
 SG_ CF_AVN_DAWModeNValueSet_NEW : 54|2@1+ (1,0) [0|0] ""  CLU_MM

BO_ 1207 HU_NAVI_V2_PROSHORT_E_00: 8 H_U_MM
 SG_ PROSHORT_V2_Offset : 0|13@1+ (1,0) [0|0] "m"  CLU_MM,CGW
 SG_ PROSHORT_V2_CyclicCounter : 19|2@1+ (1,0) [0|0] ""  CLU_MM,CGW
 SG_ PROSHORT_V2_Distance : 23|10@1+ (1,0) [0|0] "m"  CLU_MM,CGW
 SG_ PROSHORT_V2_Value0 : 33|10@1+ (1,0) [0|0] ""  CLU_MM,CGW
 SG_ PROSHORT_V2_Value1 : 43|10@1+ (1,0) [0|0] ""  CLU_MM,CGW
 SG_ PROSHORT_V2_ProfileType : 53|5@1+ (1,0) [0|0] ""  CLU_MM,CGW

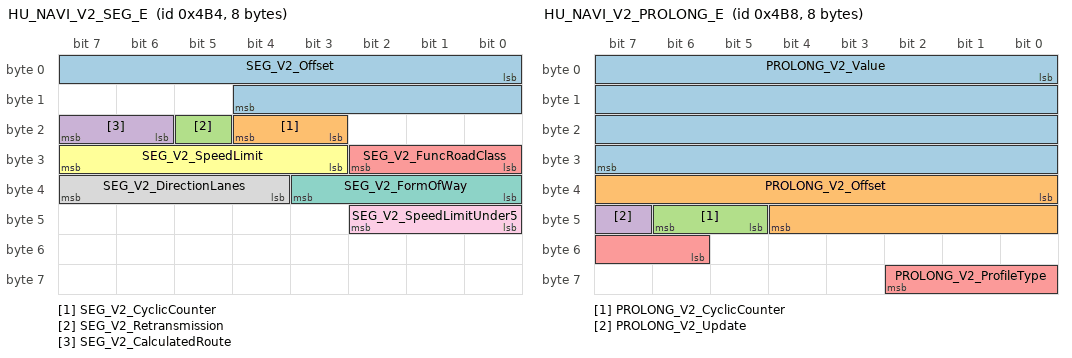
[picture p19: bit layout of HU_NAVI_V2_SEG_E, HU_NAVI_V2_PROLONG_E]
BO_ 1204 HU_NAVI_V2_SEG_E: 8 H_U_MM
 SG_ SEG_V2_Offset : 0|13@1+ (1,0) [0|0] "m"  CLU_MM,CGW
 SG_ SEG_V2_CyclicCounter : 19|2@1+ (1,0) [0|0] ""  CLU_MM,CGW
 SG_ SEG_V2_Retransmission : 21|1@1+ (1,0) [0|0] ""  CLU_MM,CGW
 SG_ SEG_V2_CalculatedRoute : 22|2@1+ (1,0) [0|0] ""  CLU_MM,CGW
 SG_ SEG_V2_FuncRoadClass : 24|3@1+ (1,0) [0|0] ""  CLU_MM,CGW
 SG_ SEG_V2_SpeedLimit : 27|5@1+ (1,0) [0|0] ""  CLU_MM,CGW
 SG_ SEG_V2_FormOfWay : 32|4@1+ (1,0) [0|0] ""  CLU_MM,CGW
 SG_ SEG_V2_DirectionLanes : 36|4@1+ (1,0) [0|0] ""  CLU_MM,CGW
 SG_ SEG_V2_SpeedLimitUnder5 : 40|3@1+ (1,0) [0|0] ""  CLU_MM,CGW

BO_ 1208 HU_NAVI_V2_PROLONG_E: 8 H_U_MM
 SG_ PROLONG_V2_Value : 0|32@1+ (1,0) [0|0] ""  CLU_MM,CGW
 SG_ PROLONG_V2_Offset : 32|13@1+ (1,0) [0|0] "m"  CLU_MM,CGW
 SG_ PROLONG_V2_CyclicCounter : 45|2@1+ (1,0) [0|0] ""  CLU_MM,CGW
 SG_ PROLONG_V2_Update : 47|1@1+ (1,0) [0|0] ""  CLU_MM,CGW
 SG_ PROLONG_V2_ProfileType : 54|5@1+ (1,0) [0|0] ""  CLU_MM,CGW

BO_ 1377 NM_CLU_MM: 8 CLU_MM
 SG_ Destination_CLU_MM : 0|8@1+ (1,0) [0|0] ""  H_U_MM,HS_M,CGW
 SG_ NMSleepFlag_CLU_MM : 12|2@1+ (1,0) [0|0] ""  H_U_MM,HS_M,CGW
 SG_ NMCommandCode_CLU_MM : 8|3@1+ (1,0) [0|0] ""  H_U_MM,HS_M,CGW

BO_ 1379 NM_H_U_MM: 8 H_U_MM
 SG_ Destination_H_U_MM : 0|8@1+ (1,0) [0|0] ""  CLU_MM,HS_M,CGW
 SG_ NMSleepFlag_H_U_MM : 12|2@1+ (1,0) [0|0] ""  CLU_MM,HS_M,CGW
 SG_ NMCommandCode_H_U_MM : 8|3@1+ (1,0) [0|0] ""  CLU_MM,HS_M,CGW

BO_ 1302 NM_CGW: 8 CGW
 SG_ Destination_CGW : 0|8@1+ (1,0) [0|0] ""  CLU_MM,H_U_MM,HS_M
 SG_ NMSleepFlag_CGW : 12|2@1+ (1,0) [0|0] ""  CLU_MM,H_U_MM,HS_M
 SG_ NMCommandCode_CGW : 8|3@1+ (1,0) [0|0] ""  CLU_MM,H_U_MM,HS_M

CM_ BO_ 2015 "[EW] On Event and On Write";
CM_ BO_ 810 "[PE] Periodic and On Event";
CM_ SG_ 810 C_BLEOption "BLE Option Info(NFC, FP, BLE, etc)";
CM_ SG_ 810 C_BLE_ProfileIDRValue "This signal Indicate the Current detected Profile ID by BLE";
CM_ SG_ 810 C_BLEIDOut "BLE ID out warning display signal on cluster";
CM_ SG_ 810 C_BLEKeyreminder "BLE position info for cluster warning info display";
CM_ BO_ 1228 "[PE] Periodic and On Event";
CM_ SG_ 1228 TBT_Display_Type "Information for NAVI TBT Display type";
CM_ SG_ 1228 TBT_Direction "Information for direction defined at TBT_Display_Type
- 48 directions (7.5 deg. Interval)
- Vehicles following HUD/Cluster Interface Spec (ES-96560-22) use only 16 directions (22.5 deg. Interval)";
CM_ SG_ 1228 TBT_Distance_Turn_Point "Remaining distance to turn point (over Decimal Point)";
CM_ SG_ 1228 TBT_Scale "Information for Scale unit (m, km, mile, feet)";
CM_ SG_ 1228 TBT_Combined_Side_Street "Information for direction of combined side street (in front of turn point)
(Using according to display type definition)";
CM_ SG_ 1228 TBT_DistancetoTurnPoint "Information for remaining distance from turn point (under Decimal Point)";
CM_ SG_ 1228 TBT_Side_Street "Information for whole directions of street
(Using according to display type definition)
15 directions (except backward) are assigned to each 15 bits";
CM_ BO_ 1266 "[PE] Periodic and On Event";
CM_ SG_ 1266 HU_LanguageInfo "Information for System Language (for Display Font)";
CM_ SG_ 1266 HU_MuteStatus "Information for System Mute Display";
CM_ SG_ 1266 HU_NaviStatus "Information for Navigation Status (Booting, Normal Operation, No SD card)
-AVN NAVI Transmission Signal";
CM_ SG_ 1266 HU_NaviDisp "Information for Navi Display status on Front Monitor";
CM_ SG_ 1266 HU_NaviCamSettingStatus "Information for Navi Camera alert setting status

+ Bit-coded field (On 1, Off 0)
   - bit 0 : Fixed Camera
   - bit 1 : Signal/Speed Violation Camera
   - bit 2 : Movable Camera
   - bit 3 : User Registration Fixed Camera
   - bit 4 : User Registration Signal/Speed Violation Camera
   - bit 5~6 : Reserved
-AVN NAVI Transmission Signal";
CM_ SG_ 1266 HU_VolumeStatus "Information for AVN Volume";
CM_ BO_ 1230 "[PE] Periodic and On Event";
CM_ SG_ 1230 HU_OpState_New "Information for AV Operation mode";
CM_ SG_ 1230 HU_FMFrequency_Offset_Type "Information for FM frequency offset type";
CM_ SG_ 1230 HU_User_Input "User Input (Seek Up/Dn, Mode Change)
# Singnal Trigger Condition
1. DiscCD/MP3CD/VCD
 - Track Up/Dn (by SoftKey)
 - Track Up/Dn (by HardKey)
 - Song Change (by List)
 - Song Cjamge (by Tune Enter)
2. DVD (No TP)
 - Track Up/Dn (by SoftKey)
 - Track Up/Dn (by HardKey)
 - Song Change (by List)
 - Song Cjamge (by Tune Enter)
3. DMB/DAB
 - Track Up/Dn (by HardKey)
 - Song Change (by List)
 - Song Cjamge (by Tune Enter)
4. FM/AM/SXM
 - Track Up/Dn (by HardKey)
 - Song Change (by List)
5. ITM(FM/DAB)
 - Track Up/Dn (by HardKey)
 - Song Change (by List)
 - Song Cjamge (by Tune Enter)
6. USB Music/Video/My Music/JukeBox/iPod/Pandora
 - Track Up/Dn (by SoftKey)
 - Track Up/Dn (by HardKey)
 - Song Change (by List)
 - Song Cjamge (by Tune Enter)
7. Bluetooth Audio
 - Track Up/Dn (by SoftKey)
 - Track Up/Dn (by HardKey)
8. CarPlay/Android Auto
 - Track Up/Dn (by HardKey)";
CM_ SG_ 1230 HU_Frequency_Unit "Information for Frequency unit display";
CM_ SG_ 1230 HU_Track_Number_New "Information for Number of Track / Chapter / Playlist";
CM_ SG_ 1230 HU_Frequency_New "Information for Radio Frequency";
CM_ SG_ 1230 FM_Decimal_Point "Information for Frequency decimal point";
CM_ BO_ 1600 "[PE] Periodic and On Event";
CM_ SG_ 1600 NV_Display_TG "Information for Toll Gate Display";
CM_ SG_ 1600 TBT_BarGraph100Level "Information for Bar Graph Level (0 ~ 100%, 10% interval), 

if your system develop after 2012-09-10, you must not use TBT_Bar_Level(@0x115)";
CM_ BO_ 1601 "[PE] Periodic and On Event";
CM_ SG_ 1601 Navi_WarnDist_OverDec "Remaining distance to warning information (over decimal point)";
CM_ SG_ 1601 Navi_WarnDist_Scale "Scale unit of warning distance";
CM_ SG_ 1601 Navi_WarnDist_UnderDec "Remaining distance to warning information (under decimal point)";
CM_ BO_ 1255 "[PE] Periodic and On Event";
CM_ SG_ 1255 Navi_OverSpdAlarm "Command for Alarm of Over speed";
CM_ SG_ 1255 Navi_WarningZone2 "Inform warning zones";
CM_ SG_ 1255 Navi_NonSpdTrap "Inform Non Speed-Traps";
CM_ SG_ 1255 Navi_WarningZone3 "Inform warning zones";
CM_ SG_ 1255 Navi_WarningZone "Inform warning zones";
CM_ SG_ 1255 Navi_CurveWarning "Information for Warning a curve";
CM_ SG_ 1255 Navi_SpdInfo_Type "Information for Type of Warning related with Speed";
CM_ SG_ 1255 Navi_SpdLimit_Unit "Informatin for Unit of Speed Limit Warning";
CM_ SG_ 1255 Navi_SpdLimit_Type "Information for Type of Speed Limit Warning";
CM_ SG_ 1255 Navi_SpdLimit "Information for Speed of Speed Limit Warning";
CM_ BO_ 1256 "[PE] Periodic and On Event";
CM_ SG_ 1256 NV_EstDist_Unit "Information for distance unit
Unit for NV_EstDist_F & Nv_EstDist_F";
CM_ SG_ 1256 NV_EstMin "Information for Estimate Time of Arrival / Necessary Time (Minutes)";
CM_ SG_ 1256 NV_Azimuth "Information for north azimuth angle
- 48 directions (7.5 deg. Interval)";
CM_ SG_ 1256 NV_EstDist_I "Information for distance to destination or stops (Over decimal point)";
CM_ SG_ 1256 NV_EstDist_F "Information for distance to destination or stops (Under decimal point)";
CM_ SG_ 1256 NV_EstPointType "Informatio for Destination / Waypoint Type";
CM_ SG_ 1256 NV_EstimTimeFormat "Information for Time Format of Estimated Arrival Time (12H/24H)";
CM_ SG_ 1256 NV_EstimTimeType "Information for Estimated time type
1. ETA(Estimated Time to Arrive)
2. RTA(Remaining Time to Arrive) - (Necessary Time)";
CM_ SG_ 1256 NV_EstHour "Information for Estimate Time of Arrival / Necessary Time (Hour)";
CM_ BO_ 1185 "[EC] On Event and On Change";
CM_ SG_ 1185 C_AstWindowCmdAVN "This signal indicates AST Window Open/Close Command";
CM_ SG_ 1185 C_StrgWhlHeatedCmdAVN "This signal indicates Steering Wheel Heated Button Command";
CM_ SG_ 1185 C_RrDefoggerCmdAVN "This signal indicates Rear Defogger Button Command";
CM_ SG_ 1185 C_AVNIMSButtonCmd "This signal indicates IMS button Command";
CM_ SG_ 1185 C_RRWindowCmdAVN "This signal indicates RR Window Open/Close Command";
CM_ SG_ 1185 C_RLWindowCmdAVN "This signal indicates RL Window Open/Close Command";
CM_ SG_ 1185 C_BlindCmdAVN "This signal indicates Sunroof Blind Open/Close Command";
CM_ SG_ 1185 C_GlassCmdAVN "This signal indicates Sunroof Glass Open/Close Command";
CM_ SG_ 1185 C_CluDispCmdAVN "This signal indicates cluster display changing Command";
CM_ SG_ 1185 C_DrvWindowCmdAVN "This signal indicates DRV Window Open/Close Command";
CM_ SG_ 1185 C_PTGCNTLCmdAVN "This signal indicates PowerTailgate Open/Close  Command";
CM_ BO_ 1239 "[PE] Periodic and On Event";
CM_ SG_ 1239 HU_VehiclePwr "Information for the H/U power status for ADM(Accessary Delay Mode)";
CM_ BO_ 1183 "[EC] On Event and On Change";
CM_ SG_ 1183 HU_DATC_MainBlower "Main Blower control";
CM_ SG_ 1183 HU_DATC_FrontModeSet "DATC Mode control";
CM_ SG_ 1183 HU_DATC_IntakeSet "DATC Intake control";
CM_ SG_ 1183 HU_DATC_AutoSet "DATC Auto control";
CM_ SG_ 1183 HU_DATC_FrontDefog "Front window Defog";
CM_ SG_ 1183 HU_DATC_AcSet "DATC A/C control";
CM_ SG_ 1183 HU_DATC_AirCleaningSet "Air Cleaning System set";
CM_ SG_ 1183 HU_DATC_MainBlowerUpDn "Main Blower Up/Down control";
CM_ SG_ 1183 HU_DATC_DrTempUpDn "Temperature control of Driver side";
CM_ BO_ 1184 "[EC] On Event and On Change";
CM_ SG_ 1184 HU_DATC_DrTempSetC "In single type DATC, set temperature of front side directly(Centigrade).
In dual type DATC, set temperature of front left side directly(Centigrade).";
CM_ SG_ 1184 HU_DATC_DrTempSetF "In single type DATC, set temperature of front side directly (Fahrenheit).
In dual type DATC, set temperature of front left side directly (Fahrenheit).";
CM_ BO_ 1267 "[PE] Periodic and On Event";
CM_ SG_ 1267 HU_PhoneActivity "Information for Acitivity of Phone Call (For All area)";
CM_ SG_ 1267 HU_VRActivity "Information for Acitivity of VR (For All area)";
CM_ BO_ 1240 "[PE] Periodic and On Event";
CM_ SG_ 1240 CF_AVN_ProfileIDRValue "This signal is User ID value in H/Unit.";
CM_ SG_ 1240 HU_AliveStatus "Information of the status of Head Unit
0x00 : Headunit is booting so, Headunit cant display any state
0x01 : Headunit is normal state, Headunit could display according to MM CAN  command.
0x02 : Headunit is doing their internal process, so Headunit cant communicate with other node.
For CLU/SCC/eCall
-AVN System transmission signal";
CM_ BO_ 1278 "[PE] Periodic and On Event";
CM_ SG_ 1278 HU_Type "Information for H/U Platform type
- Integrated AVN 1.0 use different value depends on development company (Mobis:0x68/LG:0x70)
- Integrated AVN 1.0 Mobis is developed based on Display Audio
- Integrated AVN 1.0 LG is developed based on Compact AVN

Information for China OPIO Platform
- 0xFC: China OPIO w/o CLU interface (most of phase1)
- 0xFD: China OPIO w/CLU interface (parts of phase1, phase2)

Information for Audio Platform Type
- 0x43 : Audio 4.0 Value";
CM_ SG_ 1278 HU_DistributeInfo "Region :Europe/North America/
Vehicle Type : RHD/LHD
Positionning information";
CM_ SG_ 1278 HU_OptionInfo "Information of H/U functions";
CM_ SG_ 1278 HU_AdasSupport "Information about ADAS support
-Classify between General Map and Precise Map Transmission Function
-AVN System Transmission Signal";
CM_ BO_ 1246 "[PE] Periodic and On Event";
CM_ SG_ 1246 POS_V2_Offset "Information for Position moving distance during Position Age.
-Transmitting Map Matching Moving Distance(m) of Vehicles for 200ms by this signal";
CM_ SG_ 1246 POS_V2_CyclicCounter "Information for Cyclic counter of this message type: Reconstructor can use this value to detect missing messages.";
CM_ SG_ 1246 POS_V2_RangeAvgSpeed "Information for Range camera average speed
(km/h)
This is used when entering the range camera area.";
CM_ BO_ 1208 "[EC] On Event and On Change";
CM_ SG_ 1208 PROLONG_V2_Value "Information for Profile Long value at Offset";
CM_ SG_ 1208 PROLONG_V2_Offset "Information for Offset of position of the first profile spot from currnet position";
CM_ SG_ 1208 PROLONG_V2_CyclicCounter "Information for Cyclic counter of this message type and profile type: Reconstructor can use this value to detect missing messages
-Applying particularly according to PROLONG_ProfileType
 Ex) ProfileType(CyclicCounter): 0x1(0)  0x1(1)  0x10(0)  0x1(2)  0x10(1) …";
CM_ SG_ 1208 PROLONG_V2_Update "Updated information of already transmitted Profile Long
-If Overspeed Check Camera Information is updated by Wireless Network of TPEG, set 'True' about Updated Field of Profile Long Message and transmitt it. Refer to '5.7.8' in specification for detail";
CM_ SG_ 1208 PROLONG_V2_ProfileType "Information for Profile Long Type(0~31)
-Refer to 'Table 19' in specification for detail";
CM_ BO_ 1207 "[EC] On Event and On Change";
CM_ SG_ 1207 PROSHORT_V2_Offset "Information for Offset of position of the first profile spot from currnet position
-This Offset should be calculated using below Factors(according to Profile Type)
-Profile Type 1(Curvature): 1m
-Profile Type 4(Slope): 1m(PROSHORT_Accuracy=0x0), 3m(PROSHORT_Accuracy=0x2)
-Profile Type 16(Safety Driving Section): 1m(Section0,1,2,3,5)
-Refer to Specification(ES96523-31) for details";
CM_ SG_ 1207 PROSHORT_V2_CyclicCounter "Information for Cyclic counter of this message type and profile type: Reconstructor can use this value to detect missing messages.
-According to Profile Type, transmitt different Cyclic Counter Values
-In case of Slope, transmitt Cyclic Counter Values according to the Slope Transmitting Specification
 (Refer to 5.4 Slope Information Transmitting Scenario in Specification: It is about Information for Average Slope(Maximum 3) Transmitting by Event in forward unit distance(2km/20km) containing Current Location)
-In case of 'PROSHORT_CyclicCounter', transmitt particularly according to the 'PROSHORT_ProfileType'
 Ex) ProfileType(CyclicCounter): 0x1(0)  0x1(1)  0x10(0)  0x1(2)  0x10(1) ...";
CM_ SG_ 1207 PROSHORT_V2_Distance "Information for Distance from first profile spot to the second one
-This distance should be calculated using below Factors(according to Profile Type)
-Profile Type 1(Curvature): 2
-Profile Type 4(Slope): 2(PROSHORT_Accuracy=0x0), 20(PROSHORT_Accuracy=0x2)
-Profile Type 16(Safety Driving Section): 20(Section0,1), 2(Section2,3), 5(Section5)";
CM_ SG_ 1207 PROSHORT_V2_Value0 "Information for Profile Short value at Offset";
CM_ SG_ 1207 PROSHORT_V2_Value1 "Information for Profile Short value at Offset+Distance1";
CM_ SG_ 1207 PROSHORT_V2_ProfileType "Information for Profile Short Type: Slope(Linear) is used for Slope
-In case of Section Speed, transmitt Average Value of Speed Limit of Links in Section.
-Link without Speed Limit is excluded for Average Speed Calculation
-Unlimited Lane in Europe reflects 140kph for Average Speed Calculation";
CM_ BO_ 1204 "[EC] On Event and On Change";
CM_ SG_ 1204 SEG_V2_Offset "Information for Offset of this Segment from current position";
CM_ SG_ 1204 SEG_V2_CyclicCounter "Information for Cyclic counter of this message type: Reconstructor can use this value to detect missing messages";
CM_ SG_ 1204 SEG_V2_Retransmission "Information for Retransmission Flag: If true, this message was sent already at least once before.";
CM_ SG_ 1204 SEG_V2_CalculatedRoute "Information for Calculated Route: MPP/On Route/Off Route(Recalculating Route)
-MPP: Predicted Route(Not the Link from Searched Route). Used if users don’t set Destination. Used with Current Link Information.
-On Route: Link from Searched Route. Used with Current Link Information.
-Off Route: Used when trying to enter the Rest Area. 'SEG_CalculatedRoute', 'SEG_FormOfWay' and 'SEG_FunctionalRoadClass' are used together. But if it is impossible to decide values of 'SEG_FormOfWay' and 'SEG_FunctionalRoadClass', transmitt Unknown Value. If additional Information happens in forward unit distance, retransmitt it by Event.";
CM_ SG_ 1204 SEG_V2_FuncRoadClass "Information for Functional Road Class indicates relative importance of the road in the routing network and lower values indicate higher priority";
CM_ SG_ 1204 SEG_V2_SpeedLimit "Information for Current Link Speed Limit expressed as km/h or mph according to META_SpeedUnit";
CM_ SG_ 1204 SEG_V2_FormOfWay "Information for Link Class Value of Segment";
CM_ SG_ 1204 SEG_V2_DirectionLanes "Information for the Number of lanes in driving direction";
CM_ SG_ 1204 SEG_V2_SpeedLimitUnder5 "Current Link Speed Limit of less than 5 kph or mph according to META_SpeedUnit";
CM_ BO_ 1187 "[PE] Periodic and On Event";
CM_ SG_ 1187 Navi_ISLW_LinkClass "Link Class for SLIF(Speed Limit Information Function)";
CM_ SG_ 1187 Navi_ISLW_CountryCode "Country Code for SLIF(Speed Limit Information Function)";
CM_ SG_ 1187 Navi_ISLW_MapSource "Map source signal for SLIF(Speed Limit Information Function) with TOMTOM service in EU

(NT.TT.ETC)
Define priority of SLIF Information";
CM_ SG_ 1187 Navi_ISLW_Frwinfo "Freeway information for SLIF(Speed Limit Information Function)";
CM_ SG_ 1187 Navi_ISLW_TollExist "Toll exist information to LDWS Camera";
CM_ SG_ 1187 Navi_ISLW_TunnelExist "Tunnel existance information for LDWS Camera";
CM_ SG_ 1187 Navi_ISLW_TimeSpd "Time restriced speed limit information on the road for LDWS Camera";
CM_ SG_ 1187 Navi_ISLW_SpdUnit "Unit of Speed Limit for SLIF(Speed Limit Information Function) from NAVI to Camera";
CM_ SG_ 1187 Navi_ISLW_SpdLimit "Speed of Speed Limit for SLIF(Speed Limit Information Function) from NAVI to Camera

Unit (regardless of Navi_SLIF_SpdUnit)
-UK : mph
-other : kph";
CM_ BO_ 1192 "[EC] On Event and On Change";
CM_ SG_ 1192 CF_AVN_FCANValueSet "This signal is used for a request to set the value of USM Menus. This signal requests to change status of AEB.";
CM_ SG_ 1192 CF_AVN_HDANValueSet "USM request for HDA On/Off";
CM_ SG_ 1192 CF_AVN_SEANValueSet "Request to set Safe Exit Assist";
CM_ SG_ 1192 CF_AVN_NSCCCamNValueSet "This signal is used for a request to set the value of USM Menus. This signal requests to change status of SCC interlocked with Navi Camera function.

When this signal change, the message is sent 3 times.";
CM_ SG_ 1192 CF_AVN_BCANValueSet "Reqeust to set BCA system state";
CM_ SG_ 1192 CF_AVN_ISLWNValueSet "This signal is used for a request to set the value of USM Menus. This signal requests to set ISLW status.
When this signal change, the message is sent 3 times.";
CM_ SG_ 1192 CF_AVN_WarningTimingNValueSet "Reqeust to set Warning Timing state";
CM_ SG_ 1192 CF_AVN_NSCCCrvNValueSet "This signal is used for a request to set the value of USM Menus. This signal requests to change status of SCC interlocked with Navi Curve function. When this signal change, the message is sent 3 times.";
CM_ SG_ 1192 CF_AVN_BCWSndWanNValueSet "Request to set BCW Sound Warning System state";
CM_ SG_ 1192 CF_AVN_RCCWNValueSet "Reqeust to set RCCW system state";
CM_ SG_ 1192 CF_AVN_LkaModeNValueSet "This signal is used for a request to set the value of USM Menus. This signal requests to set LKA control mode.
When this signal change, the message is sent 3 times.";
CM_ SG_ 1192 CF_AVN_AdasVolumeNValueSet "Request to set ADAS warning volume level";
CM_ SG_ 1192 CF_AVN_SCCDrvModeNValueSet "This signal is used for a request to set the value of USM Menus. This signal requests to change SCC driving mode.
When this signal change, the message is sent 3 times.";
CM_ BO_ 1195 "[EC] On Event and On Change";
CM_ SG_ 1195 CF_AVN_CluWelcomeSnd "Request to set CLU welcome soun";
CM_ SG_ 1195 CF_AVN_CluTransmissionDisp "Request to set CLU transmission display";
CM_ SG_ 1195 CF_AVN_CluWiperLight "Request to set CLU wiper & light mode";
CM_ SG_ 1195 CF_AVN_CluRoadInfoGuide "Request to set CLU road info guidance";
CM_ SG_ 1195 CF_AVN_CluUserSettingPeriod "Request to set CLU sservice period set by user";
CM_ SG_ 1195 CF_AVN_CluAutoInitFuelEconomy "Request to set CLU auto initailizing fuel economy";
CM_ SG_ 1195 CF_AVN_CluSubspeedOdometerDisp "Request to set CLU Subscale Odometer";
CM_ SG_ 1195 CF_AVN_CluFuelEconUnit_mi "Cluster setting status for cluster Fuel Economy Unit (mile)";
CM_ SG_ 1195 CF_AVN_CluFuelEconUnit_km "Cluster setting status for cluster Fuel Economy unit (km)";
CM_ SG_ 1195 CF_AVN_CluUserSettingDistance "Request to set CLU service distance set by user";
CM_ SG_ 1195 CF_AVN_CluRheostatLvl "Request to set CLU rheostat level";
CM_ SG_ 1195 CF_AVN_CluVoiceVolume "Request to set CLU Volume level";
CM_ SG_ 1195 CF_AVN_UnitReset "Request to reset Unit setting";
CM_ SG_ 1195 CF_AVN_CluServiceReminderReset "Request to reset CLU service reminder";
CM_ SG_ 1195 CF_AVN_CluUSMReset "Request to reset all USM service";
CM_ SG_ 1195 CF_AVN_CluServiceReminderSet "Request to set CLU service notification";
CM_ BO_ 1197 "[EC] On Event and On Change";
CM_ SG_ 1197 CF_AVN_HBANValueSet "USM Request for High Beam Assist";
CM_ SG_ 1197 CF_AVN_DAWModeNValueSet_NEW "USM request for Attention Warning";
CM_ BO_ 1715 "[EW] On Event and On Write";
CM_ SG_ 1715 Byte0_TCP_4ED "Contents releted with Baidu Music";
CM_ SG_ 1715 Byte2_Data_4ED "Contents releted with Baidu Music";
CM_ SG_ 1715 Byte3_Data_4ED "Contents releted with Baidu Music";
CM_ SG_ 1715 Byte4_Data_4ED "Contents releted with Baidu Music";
CM_ SG_ 1715 Byte5_Data_4ED "Contents releted with Baidu Music";
CM_ SG_ 1715 Byte6_Data_4ED "Contents releted with Baidu Music";
CM_ SG_ 1715 Byte7_Data_4ED "Contents releted with Baidu Music";
CM_ SG_ 1715 Byte1_Data_4ED "Contents releted with Baidu Music";
CM_ BO_ 1716 "[EW] On Event and On Write";
CM_ BO_ 1717 "[EW] On Event and On Write";
CM_ BO_ 1718 "[EW] On Event and On Write";
CM_ BO_ 1723 "[EW] On Event and On Write";
CM_ SG_ 1723 Byte0_TCP_4E9 "TP from CLU to HU (FM Station Name)";
CM_ SG_ 1723 Byte2_Data_4E9 "TP from CLU to HU (FM Station Name)";
CM_ SG_ 1723 Byte3_Data_4E9 "TP from CLU to HU (FM Station Name)";
CM_ SG_ 1723 Byte4_Data_4E9 "TP from CLU to HU (FM Station Name)";
CM_ SG_ 1723 Byte5_Data_4E9 "TP from CLU to HU (FM Station Name)";
CM_ SG_ 1723 Byte6_Data_4E9 "TP from CLU to HU (FM Station Name)";
CM_ SG_ 1723 Byte7_Data_4E9 "TP from CLU to HU (FM Station Name)";
CM_ SG_ 1723 Byte1_Data_4E9 "TP from CLU to HU (FM Station Name)";
CM_ BO_ 1724 "[EW] On Event and On Write";
CM_ BO_ 1725 "[EW] On Event and On Write";
CM_ BO_ 1726 "[EW] On Event and On Write";
CM_ SG_ 1726 Byte0_TCP_4EF "Flow Control message for TP_HU_IBOX_CLU";
CM_ SG_ 1726 Byte2_Data_4EF "Flow Control message for TP_HU_IBOX_CLU";
CM_ SG_ 1726 Byte3_Data_4EF "Flow Control message for TP_HU_IBOX_CLU";
CM_ SG_ 1726 Byte4_Data_4EF "Flow Control message for TP_HU_IBOX_CLU";
CM_ SG_ 1726 Byte5_Data_4EF "Flow Control message for TP_HU_IBOX_CLU";
CM_ SG_ 1726 Byte6_Data_4EF "Flow Control message for TP_HU_IBOX_CLU";
CM_ SG_ 1726 Byte7_Data_4EF "Flow Control message for TP_HU_IBOX_CLU";
CM_ SG_ 1726 Byte1_Data_4EF "Flow Control message for TP_HU_IBOX_CLU";
CM_ BO_ 1727 "[EW] On Event and On Write";
CM_ BO_ 1730 "[EW] On Event and On Write";
CM_ SG_ 1730 Byte0_TCP_4E7 "Contents related with Kaola FM";
CM_ SG_ 1730 Byte2_Data_4E7 "Contents related with Kaola FM";
CM_ SG_ 1730 Byte3_Data_4E7 "Contents related with Kaola FM";
CM_ SG_ 1730 Byte4_Data_4E7 "Contents related with Kaola FM";
CM_ SG_ 1730 Byte5_Data_4E7 "Contents related with Kaola FM";
CM_ SG_ 1730 Byte6_Data_4E7 "Contents related with Kaola FM";
CM_ SG_ 1730 Byte7_Data_4E7 "Contents related with Kaola FM";
CM_ SG_ 1730 Byte1_Data_4E7 "Contents related with Kaola FM";
CM_ BO_ 1733 "[EW] On Event and On Write";
CM_ BO_ 1734 "[EW] On Event and On Write";
CM_ SG_ 1734 Byte0_TCP_4E5 "Contents related with QQ Music";
CM_ SG_ 1734 Byte2_Data_4E5 "Contents related with QQ Music";
CM_ SG_ 1734 Byte3_Data_4E5 "Contents related with QQ Music";
CM_ SG_ 1734 Byte4_Data_4E5 "Contents related with QQ Music";
CM_ SG_ 1734 Byte5_Data_4E5 "Contents related with QQ Music";
CM_ SG_ 1734 Byte6_Data_4E5 "Contents related with QQ Music";
CM_ SG_ 1734 Byte7_Data_4E5 "Contents related with QQ Music";
CM_ SG_ 1734 Byte1_Data_4E5 "Contents related with QQ Music";
CM_ BO_ 1736 "[EW] On Event and On Write";
CM_ BO_ 1747 "[EW] On Event and On Write";
CM_ SG_ 1747 Byte0_TCP_4EC "Contents releted with Baidu Music";
CM_ SG_ 1747 Byte2_Data_4EC "Contents releted with Baidu Music";
CM_ SG_ 1747 Byte3_Data_4EC "Contents releted with Baidu Music";
CM_ SG_ 1747 Byte4_Data_4EC "Contents releted with Baidu Music";
CM_ SG_ 1747 Byte5_Data_4EC "Contents releted with Baidu Music";
CM_ SG_ 1747 Byte6_Data_4EC "Contents releted with Baidu Music";
CM_ SG_ 1747 Byte7_Data_4EC "Contents releted with Baidu Music";
CM_ SG_ 1747 Byte1_Data_4EC "Contents releted with Baidu Music";
CM_ BO_ 1748 "[EW] On Event and On Write";
CM_ BO_ 1749 "[EW] On Event and On Write";
CM_ BO_ 1750 "[EW] On Event and On Write";
CM_ BO_ 1756 "[EW] On Event and On Write";
CM_ SG_ 1756 Byte0_TCP_4E8 "TP from HU to CLU (FM Station Name)";
CM_ SG_ 1756 Byte2_Data_4E8 "TP from HU to CLU (FM Station Name)";
CM_ SG_ 1756 Byte3_Data_4E8 "TP from HU to CLU (FM Station Name)";
CM_ SG_ 1756 Byte4_Data_4E8 "TP from HU to CLU (FM Station Name)";
CM_ SG_ 1756 Byte5_Data_4E8 "TP from HU to CLU (FM Station Name)";
CM_ SG_ 1756 Byte6_Data_4E8 "TP from HU to CLU (FM Station Name)";
CM_ SG_ 1756 Byte7_Data_4E8 "TP from HU to CLU (FM Station Name)";
CM_ SG_ 1756 Byte1_Data_4E8 "TP from HU to CLU (FM Station Name)";
CM_ BO_ 1757 "[EW] On Event and On Write";
CM_ BO_ 1758 "[EW] On Event and On Write";
CM_ BO_ 1760 "[EW] On Event and On Write";
CM_ SG_ 1760 Byte0_TCP_4EE "Song Name, Artist, File Name, Play Time of iBox player";
CM_ SG_ 1760 Byte2_Data_4EE "Song Name, Artist, File Name, Play Time of iBox player";
CM_ SG_ 1760 Byte3_Data_4EE "Song Name, Artist, File Name, Play Time of iBox player";
CM_ SG_ 1760 Byte4_Data_4EE "Song Name, Artist, File Name, Play Time of iBox player";
CM_ SG_ 1760 Byte5_Data_4EE "Song Name, Artist, File Name, Play Time of iBox player";
CM_ SG_ 1760 Byte6_Data_4EE "Song Name, Artist, File Name, Play Time of iBox player";
CM_ SG_ 1760 Byte7_Data_4EE "Song Name, Artist, File Name, Play Time of iBox player";
CM_ SG_ 1760 Byte1_Data_4EE "Song Name, Artist, File Name, Play Time of iBox player";
CM_ BO_ 1761 "[EW] On Event and On Write";
CM_ BO_ 1764 "[EW] On Event and On Write";
CM_ SG_ 1764 Byte0_TCP_4E6 "Contents related with Kaola FM";
CM_ SG_ 1764 Byte2_Data_4E6 "Contents related with Kaola FM";
CM_ SG_ 1764 Byte3_Data_4E6 "Contents related with Kaola FM";
CM_ SG_ 1764 Byte4_Data_4E6 "Contents related with Kaola FM";
CM_ SG_ 1764 Byte5_Data_4E6 "Contents related with Kaola FM";
CM_ SG_ 1764 Byte6_Data_4E6 "Contents related with Kaola FM";
CM_ SG_ 1764 Byte7_Data_4E6 "Contents related with Kaola FM";
CM_ SG_ 1764 Byte1_Data_4E6 "Contents related with Kaola FM";
CM_ BO_ 1767 "[EW] On Event and On Write";
CM_ BO_ 1768 "[EW] On Event and On Write";
CM_ SG_ 1768 Byte0_TCP_4E4 "Contents related with QQ Music";
CM_ SG_ 1768 Byte2_Data_4E4 "Contents related with QQ Music";
CM_ SG_ 1768 Byte3_Data_4E4 "Contents related with QQ Music";
CM_ SG_ 1768 Byte4_Data_4E4 "Contents related with QQ Music";
CM_ SG_ 1768 Byte5_Data_4E4 "Contents related with QQ Music";
CM_ SG_ 1768 Byte6_Data_4E4 "Contents related with QQ Music";
CM_ SG_ 1768 Byte7_Data_4E4 "Contents related with QQ Music";
CM_ SG_ 1768 Byte1_Data_4E4 "Contents related with QQ Music";
CM_ BO_ 1770 "[EW] On Event and On Write";
CM_ BO_ 1377 "NM Message";
CM_ BO_ 1379 "NM Message";
CM_ BO_ 1302 "NM Message";
BA_DEF_ BO_ "TpMessage" ENUM "No","Yes" ;
BA_DEF_ SG_ "UsrSigIDS" ENUM "Yes","No" ;
BA_DEF_ BO_ "UsrMsgIDSforwardDeviation" INT 0 100 ;
BA_DEF_ BO_ "UsrMsgIDSbackwardDeviation" INT 50 1000 ;
BA_DEF_ "BusType" STRING ;
BA_DEF_ "DBName" STRING ;
BA_DEF_ "Baudrate" INT 50000 1000000 ;
BA_DEF_ "GenEnvVarEndingDsp" STRING ;
BA_DEF_ "GenEnvVarEndingSnd" STRING ;
BA_DEF_ "GenEnvVarPrefix" STRING ;
BA_DEF_ "GenNWMApBusSleep" STRING ;
BA_DEF_ "GenNWMApCanNormal" STRING ;
BA_DEF_ "GenNWMApCanOff" STRING ;
BA_DEF_ "GenNWMApCanOn" STRING ;
BA_DEF_ "GenNWMApCanSleep" STRING ;
BA_DEF_ "GenNWMApCanWakeUp" STRING ;
BA_DEF_ "GenNWMGotoMode_Awake" STRING ;
BA_DEF_ "GenNWMGotoMode_BusSleep" STRING ;
BA_DEF_ "GenNWMSleepTime" INT 1375 1650 ;
BA_DEF_ "GenNWMTalkNM" STRING ;
BA_DEF_ "Manufacturer" STRING ;
BA_DEF_ "NmBaseAddress" HEX 0 2047 ;
BA_DEF_ "NmMessageCount" INT 0 128 ;
BA_DEF_ "NmType" STRING ;
BA_DEF_ "SamplePointMax" INT 50 85 ;
BA_DEF_ "SamplePointMin" INT 55 85 ;
BA_DEF_ "SyncJumpWidthMax" INT 1 8 ;
BA_DEF_ "SyncJumpWidthMin" INT 1 4 ;
BA_DEF_ "VersionDay" INT 1 31 ;
BA_DEF_ "VersionMonth" INT 1 12 ;
BA_DEF_ "VersionWeek" INT 1 53 ;
BA_DEF_ "VersionYear" INT 0 9999 ;
BA_DEF_ BU_ "NmStationAddress" HEX 0 127 ;
BA_DEF_ BU_ "NmNode" ENUM "No","Yes" ;
BA_DEF_ BU_ "GenNodSleepTime" INT 1375 1650 ;
BA_DEF_ BU_ "ILUsed" ENUM "No","Yes" ;
BA_DEF_ BU_ "NmCAN" INT 1 2 ;
BA_DEF_ BU_ "NodeLayerModules" STRING ;
BA_DEF_ BU_ "NWM_Knoten" ENUM "No","Yes" ;
BA_DEF_ BO_ "GenMsgCycleTime" INT 0 2000 ;
BA_DEF_ BO_ "GenMsgStartDelayTime" INT 0 2000 ;
BA_DEF_ BO_ "GenMsgSendType" ENUM "Cyclic","NoMsgSendType" ;
BA_DEF_ BO_ "GenMsgCycleTimeFast" INT 0 500 ;
BA_DEF_ BO_ "GenMsgDelayTime" INT 0 20 ;
BA_DEF_ BO_ "GenMsgILSupport" ENUM "No","Yes" ;
BA_DEF_ BO_ "GenMsgNrOfRepetition" INT 0 3 ;
BA_DEF_ BO_ "NmMessage" ENUM "No","Yes" ;
BA_DEF_ BO_ "NWM-Botschaft" ENUM "No","Yes" ;
BA_DEF_ BO_ "VFrameFormat" ENUM "StandardCAN","ExtendedCAN","reserved","reserved","reserved","reserved","reserved","reserved","reserved","reserved","reserved","reserved","reserved","reserved","StandardCAN_FD","ExtendedCAN_FD" ;
BA_DEF_ SG_ "UserSigValidity" ENUM "B+","ACC","IG","IG1","IG2","IG3","IG1 or IG2","IG1 or IG3","Undef" ;
BA_DEF_ SG_ "GenSigTimeoutTime" INT 0 7000 ;
BA_DEF_ SG_ "UsrSigTimeoutValue" STRING ;
BA_DEF_ SG_ "UsrSigPurpose" ENUM "Undef","FN","DIAG","DEV","NM" ;
BA_DEF_ SG_ "GenSigStartValue" INT 0 1215752192 ;
BA_DEF_ SG_ "NetworkRequest" ENUM "Yes","No" ;
BA_DEF_ SG_ "NetworkRequestHoldingTime" INT 0 65535 ;
BA_DEF_ SG_ "Description" STRING ;
BA_DEF_ SG_ "Version" STRING ;
BA_DEF_ SG_ "GenSigEnvVarType" ENUM "Int","Float","Undef" ;
BA_DEF_ SG_ "GenSigSendType" ENUM "Cyclic","OnWrite","OnWriteWithRepetition","OnChange","OnChangeWithRepetition","IfActive","IfActiveWithRepetition","NoSigSendType","OnChangeAndIfActive","OnChangeAndIfActiveWithRepetition" ;
BA_DEF_ SG_ "GwSigLatencyTime" INT 0 65536 ;
BA_DEF_ SG_ "GwSigMissingSourceType" ENUM "Undef","OldValue","DefaultValue","InitialValue" ;
BA_DEF_ SG_ "NWM-WakeupAllowed" ENUM "<n.a.>" ;
BA_DEF_ SG_ "RoutingFactor" INT 1 1215752192 ;
BA_DEF_DEF_ "TpMessage" "No" ;
BA_DEF_DEF_ "UsrSigIDS" "No" ;
BA_DEF_DEF_ "UsrMsgIDSforwardDeviation" 10 ;
BA_DEF_DEF_ "UsrMsgIDSbackwardDeviation" 100 ;
BA_DEF_DEF_ "BusType" "CAN" ;
BA_DEF_DEF_ "DBName" "" ;
BA_DEF_DEF_ "Baudrate" 500000 ;
BA_DEF_DEF_ "GenEnvVarEndingDsp" "Dsp_" ;
BA_DEF_DEF_ "GenEnvVarEndingSnd" "_" ;
BA_DEF_DEF_ "GenEnvVarPrefix" "Env" ;
BA_DEF_DEF_ "GenNWMApBusSleep" "AppNmCanBusSleep()" ;
BA_DEF_DEF_ "GenNWMApCanNormal" "AppNmCanNormal()" ;
BA_DEF_DEF_ "GenNWMApCanOff" "ApplCanOffline()" ;
BA_DEF_DEF_ "GenNWMApCanOn" "ApplCanOnline()" ;
BA_DEF_DEF_ "GenNWMApCanSleep" "ApplNmCanSleep()" ;
BA_DEF_DEF_ "GenNWMApCanWakeUp" "ApplCanWakeUp()" ;
BA_DEF_DEF_ "GenNWMGotoMode_Awake" "GotoMode_Awake()" ;
BA_DEF_DEF_ "GenNWMGotoMode_BusSleep" "GotoMode_BusSleep()" ;
BA_DEF_DEF_ "GenNWMSleepTime" 1500 ;
BA_DEF_DEF_ "GenNWMTalkNM" "TalkNM()" ;
BA_DEF_DEF_ "Manufacturer" "HMC" ;
BA_DEF_DEF_ "NmBaseAddress" 1280 ;
BA_DEF_DEF_ "NmMessageCount" 128 ;
BA_DEF_DEF_ "NmType" "Vector" ;
BA_DEF_DEF_ "SamplePointMax" 80 ;
BA_DEF_DEF_ "SamplePointMin" 80 ;
BA_DEF_DEF_ "SyncJumpWidthMax" 3 ;
BA_DEF_DEF_ "SyncJumpWidthMin" 2 ;
BA_DEF_DEF_ "VersionDay" 1 ;
BA_DEF_DEF_ "VersionMonth" 1 ;
BA_DEF_DEF_ "VersionWeek" 1 ;
BA_DEF_DEF_ "VersionYear" 0 ;
BA_DEF_DEF_ "NmStationAddress" 0 ;
BA_DEF_DEF_ "NmNode" "Yes" ;
BA_DEF_DEF_ "GenNodSleepTime" 1500 ;
BA_DEF_DEF_ "ILUsed" "Yes" ;
BA_DEF_DEF_ "NmCAN" 1 ;
BA_DEF_DEF_ "NodeLayerModules" "oseknm01.dll,CANoeILNLVector.dll" ;
BA_DEF_DEF_ "NWM_Knoten" "Yes" ;
BA_DEF_DEF_ "GenMsgCycleTime" 200 ;
BA_DEF_DEF_ "GenMsgStartDelayTime" 0 ;
BA_DEF_DEF_ "GenMsgSendType" "NoMsgSendType" ;
BA_DEF_DEF_ "GenMsgCycleTimeFast" 40 ;
BA_DEF_DEF_ "GenMsgDelayTime" 20 ;
BA_DEF_DEF_ "GenMsgILSupport" "Yes" ;
BA_DEF_DEF_ "GenMsgNrOfRepetition" 3 ;
BA_DEF_DEF_ "NmMessage" "No" ;
BA_DEF_DEF_ "NWM-Botschaft" "No" ;
BA_DEF_DEF_ "VFrameFormat" "StandardCAN" ;
BA_DEF_DEF_ "UserSigValidity" "IG" ;
BA_DEF_DEF_ "GenSigTimeoutTime" 500 ;
BA_DEF_DEF_ "UsrSigTimeoutValue" "Undef" ;
BA_DEF_DEF_ "UsrSigPurpose" "FN" ;
BA_DEF_DEF_ "GenSigStartValue" 0 ;
BA_DEF_DEF_ "NetworkRequest" "No" ;
BA_DEF_DEF_ "NetworkRequestHoldingTime" 0 ;
BA_DEF_DEF_ "Description" "" ;
BA_DEF_DEF_ "Version" "" ;
BA_DEF_DEF_ "GenSigEnvVarType" "Undef" ;
BA_DEF_DEF_ "GenSigSendType" "NoSigSendType" ;
BA_DEF_DEF_ "GwSigLatencyTime" 40 ;
BA_DEF_DEF_ "GwSigMissingSourceType" "Undef" ;
BA_DEF_DEF_ "NWM-WakeupAllowed" "<n.a.>" ;
BA_DEF_DEF_ "RoutingFactor" 1 ;
BA_ "DBName" "CAN";
BA_ "VersionDay" 19;
BA_ "VersionMonth" 6;
BA_ "VersionYear" 2019;
BA_ "VersionWeek" 25;
BA_ "NmStationAddress" BU_ CGW 22;
BA_ "GenMsgCycleTime" BO_ 2015 0;
BA_ "GenMsgILSupport" BO_ 2015 0;
BA_ "TpMessage" BO_ 2015 1;
BA_ "GenMsgDelayTime" BO_ 2015 0;
BA_ "NmStationAddress" BU_ H_U_MM 99;
BA_ "NmStationAddress" BU_ CLU_MM 97;
BA_ "NmNode" BU_ HS_M 0;
BA_ "UsrSigPurpose" SG_ 2015 GST_ALL_Byte0 2;
BA_ "GenSigSendType" SG_ 2015 GST_ALL_Byte0 2;
BA_ "UserSigValidity" SG_ 2015 GST_ALL_Byte0 0;
BA_ "GenSigTimeoutTime" SG_ 2015 GST_ALL_Byte0 0;
BA_ "NetworkRequest" SG_ 2015 GST_ALL_Byte0 0;
BA_ "NetworkRequestHoldingTime" SG_ 2015 GST_ALL_Byte0 5000;
BA_ "Version" SG_ 2015 GST_ALL_Byte0 "19.02.08";
BA_ "UsrSigPurpose" SG_ 2015 GST_ALL_Byte2 2;
BA_ "GenSigSendType" SG_ 2015 GST_ALL_Byte2 2;
BA_ "UserSigValidity" SG_ 2015 GST_ALL_Byte2 0;
BA_ "GenSigTimeoutTime" SG_ 2015 GST_ALL_Byte2 0;
BA_ "NetworkRequest" SG_ 2015 GST_ALL_Byte2 0;
BA_ "NetworkRequestHoldingTime" SG_ 2015 GST_ALL_Byte2 5000;
BA_ "Version" SG_ 2015 GST_ALL_Byte2 "19.02.08";
BA_ "UsrSigPurpose" SG_ 2015 GST_ALL_Byte3 2;
BA_ "GenSigSendType" SG_ 2015 GST_ALL_Byte3 2;
BA_ "UserSigValidity" SG_ 2015 GST_ALL_Byte3 0;
BA_ "GenSigTimeoutTime" SG_ 2015 GST_ALL_Byte3 0;
BA_ "NetworkRequest" SG_ 2015 GST_ALL_Byte3 0;
BA_ "NetworkRequestHoldingTime" SG_ 2015 GST_ALL_Byte3 5000;
BA_ "Version" SG_ 2015 GST_ALL_Byte3 "19.02.08";
BA_ "UsrSigPurpose" SG_ 2015 GST_ALL_Byte4 2;
BA_ "GenSigSendType" SG_ 2015 GST_ALL_Byte4 2;
BA_ "UserSigValidity" SG_ 2015 GST_ALL_Byte4 0;
BA_ "GenSigTimeoutTime" SG_ 2015 GST_ALL_Byte4 0;
BA_ "NetworkRequest" SG_ 2015 GST_ALL_Byte4 0;
BA_ "NetworkRequestHoldingTime" SG_ 2015 GST_ALL_Byte4 5000;
BA_ "Version" SG_ 2015 GST_ALL_Byte4 "19.02.08";
BA_ "UsrSigPurpose" SG_ 2015 GST_ALL_Byte5 2;
BA_ "GenSigSendType" SG_ 2015 GST_ALL_Byte5 2;
BA_ "UserSigValidity" SG_ 2015 GST_ALL_Byte5 0;
BA_ "GenSigTimeoutTime" SG_ 2015 GST_ALL_Byte5 0;
BA_ "NetworkRequest" SG_ 2015 GST_ALL_Byte5 0;
BA_ "NetworkRequestHoldingTime" SG_ 2015 GST_ALL_Byte5 5000;
BA_ "Version" SG_ 2015 GST_ALL_Byte5 "19.02.08";
BA_ "UsrSigPurpose" SG_ 2015 GST_ALL_Byte6 2;
BA_ "GenSigSendType" SG_ 2015 GST_ALL_Byte6 2;
BA_ "UserSigValidity" SG_ 2015 GST_ALL_Byte6 0;
BA_ "GenSigTimeoutTime" SG_ 2015 GST_ALL_Byte6 0;
BA_ "NetworkRequest" SG_ 2015 GST_ALL_Byte6 0;
BA_ "NetworkRequestHoldingTime" SG_ 2015 GST_ALL_Byte6 5000;
BA_ "Version" SG_ 2015 GST_ALL_Byte6 "19.02.08";
BA_ "UsrSigPurpose" SG_ 2015 GST_ALL_Byte7 2;
BA_ "GenSigSendType" SG_ 2015 GST_ALL_Byte7 2;
BA_ "UserSigValidity" SG_ 2015 GST_ALL_Byte7 0;
BA_ "GenSigTimeoutTime" SG_ 2015 GST_ALL_Byte7 0;
BA_ "NetworkRequest" SG_ 2015 GST_ALL_Byte7 0;
BA_ "NetworkRequestHoldingTime" SG_ 2015 GST_ALL_Byte7 5000;
BA_ "Version" SG_ 2015 GST_ALL_Byte7 "19.02.08";
BA_ "UsrSigPurpose" SG_ 2015 GST_ALL_Byte1 2;
BA_ "GenSigSendType" SG_ 2015 GST_ALL_Byte1 2;
BA_ "UserSigValidity" SG_ 2015 GST_ALL_Byte1 0;
BA_ "GenSigTimeoutTime" SG_ 2015 GST_ALL_Byte1 0;
BA_ "NetworkRequest" SG_ 2015 GST_ALL_Byte1 0;
BA_ "NetworkRequestHoldingTime" SG_ 2015 GST_ALL_Byte1 5000;
BA_ "Version" SG_ 2015 GST_ALL_Byte1 "19.02.08";
BA_ "GenMsgSendType" BO_ 810 0;
BA_ "GenMsgStartDelayTime" BO_ 810 110;
BA_ "Description" SG_ 810 C_BLEOption "18.08.09_";
BA_ "GenSigSendType" SG_ 810 C_BLEOption 4;
BA_ "UserSigValidity" SG_ 810 C_BLEOption 0;
BA_ "GenSigTimeoutTime" SG_ 810 C_BLEOption 1500;
BA_ "Version" SG_ 810 C_BLEOption "19.02.06";
BA_ "Description" SG_ 810 C_BLE_ProfileIDRValue "18.08.09_";
BA_ "GenSigSendType" SG_ 810 C_BLE_ProfileIDRValue 4;
BA_ "UserSigValidity" SG_ 810 C_BLE_ProfileIDRValue 0;
BA_ "GenSigTimeoutTime" SG_ 810 C_BLE_ProfileIDRValue 1500;
BA_ "Version" SG_ 810 C_BLE_ProfileIDRValue "18.10.02";
BA_ "Description" SG_ 810 C_BLEIDOut "BLE ID out warning display signal on cluster";
BA_ "GenSigSendType" SG_ 810 C_BLEIDOut 4;
BA_ "UserSigValidity" SG_ 810 C_BLEIDOut 1;
BA_ "GenSigTimeoutTime" SG_ 810 C_BLEIDOut 1500;
BA_ "Version" SG_ 810 C_BLEIDOut "19.02.06";
BA_ "Description" SG_ 810 C_BLEKeyreminder "18.09.01_";
BA_ "GenSigSendType" SG_ 810 C_BLEKeyreminder 4;
BA_ "UserSigValidity" SG_ 810 C_BLEKeyreminder 0;
BA_ "GenSigTimeoutTime" SG_ 810 C_BLEKeyreminder 1500;
BA_ "Version" SG_ 810 C_BLEKeyreminder "19.02.06";
BA_ "GenMsgSendType" BO_ 1228 0;
BA_ "Description" SG_ 1228 TBT_Display_Type "17.12.06_Signal value table description abbreviation reference
C : Center
R : Right
M : Middle
L : Left
WP : Way Point";
BA_ "GenSigSendType" SG_ 1228 TBT_Display_Type 4;
BA_ "GenSigStartValue" SG_ 1228 TBT_Display_Type 255;
BA_ "UserSigValidity" SG_ 1228 TBT_Display_Type 1;
BA_ "GenSigTimeoutTime" SG_ 1228 TBT_Display_Type 1500;
BA_ "NetworkRequest" SG_ 1228 TBT_Display_Type 0;
BA_ "Version" SG_ 1228 TBT_Display_Type "18.06.03";
BA_ "UsrSigIDS" SG_ 1228 TBT_Direction 0;
BA_ "Description" SG_ 1228 TBT_Direction "16.03.03_";
BA_ "GenSigSendType" SG_ 1228 TBT_Direction 4;
BA_ "GenSigStartValue" SG_ 1228 TBT_Direction 255;
BA_ "UserSigValidity" SG_ 1228 TBT_Direction 1;
BA_ "GenSigTimeoutTime" SG_ 1228 TBT_Direction 1500;
BA_ "NetworkRequest" SG_ 1228 TBT_Direction 0;
BA_ "Version" SG_ 1228 TBT_Direction "18.06.03";
BA_ "Description" SG_ 1228 TBT_Distance_Turn_Point "16.03.03_";
BA_ "GenSigSendType" SG_ 1228 TBT_Distance_Turn_Point 4;
BA_ "GenSigStartValue" SG_ 1228 TBT_Distance_Turn_Point 65535;
BA_ "UserSigValidity" SG_ 1228 TBT_Distance_Turn_Point 1;
BA_ "GenSigTimeoutTime" SG_ 1228 TBT_Distance_Turn_Point 1500;
BA_ "NetworkRequest" SG_ 1228 TBT_Distance_Turn_Point 0;
BA_ "Version" SG_ 1228 TBT_Distance_Turn_Point "18.06.03";
BA_ "Description" SG_ 1228 TBT_Scale "16.03.03_";
BA_ "GenSigSendType" SG_ 1228 TBT_Scale 4;
BA_ "GenSigStartValue" SG_ 1228 TBT_Scale 15;
BA_ "UserSigValidity" SG_ 1228 TBT_Scale 1;
BA_ "GenSigTimeoutTime" SG_ 1228 TBT_Scale 1500;
BA_ "NetworkRequest" SG_ 1228 TBT_Scale 0;
BA_ "Version" SG_ 1228 TBT_Scale "18.06.03";
BA_ "Description" SG_ 1228 TBT_Combined_Side_Street "16.03.03_";
BA_ "GenSigSendType" SG_ 1228 TBT_Combined_Side_Street 4;
BA_ "GenSigStartValue" SG_ 1228 TBT_Combined_Side_Street 15;
BA_ "UserSigValidity" SG_ 1228 TBT_Combined_Side_Street 1;
BA_ "GenSigTimeoutTime" SG_ 1228 TBT_Combined_Side_Street 1500;
BA_ "NetworkRequest" SG_ 1228 TBT_Combined_Side_Street 0;
BA_ "Version" SG_ 1228 TBT_Combined_Side_Street "18.06.03";
BA_ "Description" SG_ 1228 TBT_DistancetoTurnPoint "16.03.03_";
BA_ "GenSigSendType" SG_ 1228 TBT_DistancetoTurnPoint 4;
BA_ "GenSigStartValue" SG_ 1228 TBT_DistancetoTurnPoint 15;
BA_ "UserSigValidity" SG_ 1228 TBT_DistancetoTurnPoint 1;
BA_ "GenSigTimeoutTime" SG_ 1228 TBT_DistancetoTurnPoint 1500;
BA_ "NetworkRequest" SG_ 1228 TBT_DistancetoTurnPoint 0;
BA_ "Version" SG_ 1228 TBT_DistancetoTurnPoint "18.06.03";
BA_ "Description" SG_ 1228 TBT_Side_Street "16.03.03_";
BA_ "GenSigSendType" SG_ 1228 TBT_Side_Street 4;
BA_ "GenSigStartValue" SG_ 1228 TBT_Side_Street 65535;
BA_ "UserSigValidity" SG_ 1228 TBT_Side_Street 1;
BA_ "GenSigTimeoutTime" SG_ 1228 TBT_Side_Street 1500;
BA_ "NetworkRequest" SG_ 1228 TBT_Side_Street 0;
BA_ "Version" SG_ 1228 TBT_Side_Street "18.06.03";
BA_ "GenMsgSendType" BO_ 1266 0;
BA_ "GenMsgCycleTime" BO_ 1266 1000;
BA_ "Description" SG_ 1266 HU_LanguageInfo "18.08.09_Hungarian (0x1C) 수정 (For AE)";
BA_ "GenSigSendType" SG_ 1266 HU_LanguageInfo 4;
BA_ "GenSigStartValue" SG_ 1266 HU_LanguageInfo 255;
BA_ "UserSigValidity" SG_ 1266 HU_LanguageInfo 1;
BA_ "GenSigTimeoutTime" SG_ 1266 HU_LanguageInfo 5000;
BA_ "NetworkRequest" SG_ 1266 HU_LanguageInfo 0;
BA_ "Version" SG_ 1266 HU_LanguageInfo "18.09.02";
BA_ "Description" SG_ 1266 HU_MuteStatus "16.03.03_";
BA_ "GenSigSendType" SG_ 1266 HU_MuteStatus 4;
BA_ "GenSigStartValue" SG_ 1266 HU_MuteStatus 3;
BA_ "UserSigValidity" SG_ 1266 HU_MuteStatus 1;
BA_ "GenSigTimeoutTime" SG_ 1266 HU_MuteStatus 5000;
BA_ "NetworkRequest" SG_ 1266 HU_MuteStatus 0;
BA_ "Version" SG_ 1266 HU_MuteStatus "18.04.02";
BA_ "Description" SG_ 1266 HU_NaviStatus "18.11.00_";
BA_ "GenSigSendType" SG_ 1266 HU_NaviStatus 4;
BA_ "UserSigValidity" SG_ 1266 HU_NaviStatus 1;
BA_ "GenSigTimeoutTime" SG_ 1266 HU_NaviStatus 5000;
BA_ "NetworkRequest" SG_ 1266 HU_NaviStatus 0;
BA_ "Version" SG_ 1266 HU_NaviStatus "18.11.01";
BA_ "Description" SG_ 1266 HU_NaviDisp "16.03.03_";
BA_ "GenSigSendType" SG_ 1266 HU_NaviDisp 4;
BA_ "GenSigStartValue" SG_ 1266 HU_NaviDisp 3;
BA_ "UserSigValidity" SG_ 1266 HU_NaviDisp 1;
BA_ "GenSigTimeoutTime" SG_ 1266 HU_NaviDisp 5000;
BA_ "NetworkRequest" SG_ 1266 HU_NaviDisp 0;
BA_ "Version" SG_ 1266 HU_NaviDisp "18.04.02";
BA_ "Description" SG_ 1266 HU_NaviCamSettingStatus "18.08.09_";
BA_ "GenSigSendType" SG_ 1266 HU_NaviCamSettingStatus 4;
BA_ "GenSigStartValue" SG_ 1266 HU_NaviCamSettingStatus 255;
BA_ "UserSigValidity" SG_ 1266 HU_NaviCamSettingStatus 1;
BA_ "GenSigTimeoutTime" SG_ 1266 HU_NaviCamSettingStatus 5000;
BA_ "NetworkRequest" SG_ 1266 HU_NaviCamSettingStatus 0;
BA_ "Version" SG_ 1266 HU_NaviCamSettingStatus "18.09.02";
BA_ "Description" SG_ 1266 HU_VolumeStatus "16.03.03_";
BA_ "GenSigSendType" SG_ 1266 HU_VolumeStatus 4;
BA_ "GenSigStartValue" SG_ 1266 HU_VolumeStatus 63;
BA_ "UserSigValidity" SG_ 1266 HU_VolumeStatus 1;
BA_ "GenSigTimeoutTime" SG_ 1266 HU_VolumeStatus 5000;
BA_ "NetworkRequest" SG_ 1266 HU_VolumeStatus 0;
BA_ "Version" SG_ 1266 HU_VolumeStatus "18.04.02";
BA_ "GenMsgSendType" BO_ 1230 0;
BA_ "Description" SG_ 1230 HU_OpState_New "18.08.09_";
BA_ "GenSigSendType" SG_ 1230 HU_OpState_New 4;
BA_ "GenSigStartValue" SG_ 1230 HU_OpState_New 127;
BA_ "UserSigValidity" SG_ 1230 HU_OpState_New 1;
BA_ "GenSigTimeoutTime" SG_ 1230 HU_OpState_New 1500;
BA_ "NetworkRequest" SG_ 1230 HU_OpState_New 0;
BA_ "Version" SG_ 1230 HU_OpState_New "18.09.02";
BA_ "Description" SG_ 1230 HU_FMFrequency_Offset_Type "17.02.05_Case 1) Offset Type==1(8750) : 'HU_Frequency_New' signal offset value is 8750

Case 2) Offset Type==2(6000) : 'HU_Frequency_New' signal offset value is 6000
 - In case FM frequency minimum value is less than 8750, offset type 2 is applied. (Brazil, Japan, etc...)";
BA_ "GenSigSendType" SG_ 1230 HU_FMFrequency_Offset_Type 4;
BA_ "UserSigValidity" SG_ 1230 HU_FMFrequency_Offset_Type 1;
BA_ "GenSigTimeoutTime" SG_ 1230 HU_FMFrequency_Offset_Type 1500;
BA_ "Version" SG_ 1230 HU_FMFrequency_Offset_Type "18.04.02";
BA_ "Description" SG_ 1230 HU_User_Input "16.03.03_";
BA_ "GenSigSendType" SG_ 1230 HU_User_Input 4;
BA_ "UserSigValidity" SG_ 1230 HU_User_Input 1;
BA_ "GenSigTimeoutTime" SG_ 1230 HU_User_Input 1500;
BA_ "Version" SG_ 1230 HU_User_Input "18.04.02";
BA_ "Description" SG_ 1230 HU_Frequency_Unit "16.03.03_";
BA_ "GenSigSendType" SG_ 1230 HU_Frequency_Unit 4;
BA_ "GenSigStartValue" SG_ 1230 HU_Frequency_Unit 3;
BA_ "UserSigValidity" SG_ 1230 HU_Frequency_Unit 1;
BA_ "GenSigTimeoutTime" SG_ 1230 HU_Frequency_Unit 1500;
BA_ "Version" SG_ 1230 HU_Frequency_Unit "18.04.02";
BA_ "Description" SG_ 1230 HU_Track_Number_New "16.03.03_";
BA_ "GenSigSendType" SG_ 1230 HU_Track_Number_New 4;
BA_ "GenSigStartValue" SG_ 1230 HU_Track_Number_New 65535;
BA_ "UserSigValidity" SG_ 1230 HU_Track_Number_New 1;
BA_ "GenSigTimeoutTime" SG_ 1230 HU_Track_Number_New 1500;
BA_ "NetworkRequest" SG_ 1230 HU_Track_Number_New 0;
BA_ "Version" SG_ 1230 HU_Track_Number_New "18.04.02";
BA_ "Description" SG_ 1230 HU_Frequency_New "18.08.09_AM : Frequency = Signal value (ignore Decimal_Point value)
FM : Frequency = (Signal value (in decimal) + Offset Type) / 100
Case 1) 'HU_FMFrequency_Offset_Type'==8750 (Hex==0x0)
            : 'HU_Frequency_New' signal offset value is 8750
Case 2) 'HU_FMFrequency_Offset_Type'==6000 (Hex==0x1)
            : 'HU_Frequency_New' signal offset value is 6000";
BA_ "GenSigSendType" SG_ 1230 HU_Frequency_New 4;
BA_ "GenSigStartValue" SG_ 1230 HU_Frequency_New 8191;
BA_ "UserSigValidity" SG_ 1230 HU_Frequency_New 1;
BA_ "GenSigTimeoutTime" SG_ 1230 HU_Frequency_New 1500;
BA_ "NetworkRequest" SG_ 1230 HU_Frequency_New 0;
BA_ "Version" SG_ 1230 HU_Frequency_New "18.09.02";
BA_ "Description" SG_ 1230 FM_Decimal_Point "16.03.03_";
BA_ "GenSigSendType" SG_ 1230 FM_Decimal_Point 4;
BA_ "GenSigStartValue" SG_ 1230 FM_Decimal_Point 3;
BA_ "UserSigValidity" SG_ 1230 FM_Decimal_Point 1;
BA_ "GenSigTimeoutTime" SG_ 1230 FM_Decimal_Point 1500;
BA_ "NetworkRequest" SG_ 1230 FM_Decimal_Point 0;
BA_ "Version" SG_ 1230 FM_Decimal_Point "18.04.02";
BA_ "GenMsgSendType" BO_ 1600 0;
BA_ "Description" SG_ 1600 NV_Display_TG "16.03.03_";
BA_ "GenSigSendType" SG_ 1600 NV_Display_TG 4;
BA_ "GenSigStartValue" SG_ 1600 NV_Display_TG 3;
BA_ "UserSigValidity" SG_ 1600 NV_Display_TG 1;
BA_ "GenSigTimeoutTime" SG_ 1600 NV_Display_TG 1500;
BA_ "NetworkRequest" SG_ 1600 NV_Display_TG 0;
BA_ "Version" SG_ 1600 NV_Display_TG "18.12.06";
BA_ "UsrSigIDS" SG_ 1600 TBT_BarGraph100Level 0;
BA_ "Description" SG_ 1600 TBT_BarGraph100Level "16.03.03_";
BA_ "GenSigSendType" SG_ 1600 TBT_BarGraph100Level 4;
BA_ "GenSigStartValue" SG_ 1600 TBT_BarGraph100Level 255;
BA_ "UserSigValidity" SG_ 1600 TBT_BarGraph100Level 3;
BA_ "GenSigTimeoutTime" SG_ 1600 TBT_BarGraph100Level 1500;
BA_ "Version" SG_ 1600 TBT_BarGraph100Level "18.12.06";
BA_ "GenMsgSendType" BO_ 1601 0;
BA_ "Description" SG_ 1601 Navi_WarnDist_OverDec "16.07.03_";
BA_ "GenSigSendType" SG_ 1601 Navi_WarnDist_OverDec 4;
BA_ "GenSigStartValue" SG_ 1601 Navi_WarnDist_OverDec 65535;
BA_ "UserSigValidity" SG_ 1601 Navi_WarnDist_OverDec 1;
BA_ "GenSigTimeoutTime" SG_ 1601 Navi_WarnDist_OverDec 1500;
BA_ "Version" SG_ 1601 Navi_WarnDist_OverDec "18.12.06";
BA_ "Description" SG_ 1601 Navi_WarnDist_Scale "16.07.02_";
BA_ "GenSigSendType" SG_ 1601 Navi_WarnDist_Scale 4;
BA_ "GenSigStartValue" SG_ 1601 Navi_WarnDist_Scale 15;
BA_ "UserSigValidity" SG_ 1601 Navi_WarnDist_Scale 1;
BA_ "GenSigTimeoutTime" SG_ 1601 Navi_WarnDist_Scale 1500;
BA_ "Version" SG_ 1601 Navi_WarnDist_Scale "18.12.06";
BA_ "Description" SG_ 1601 Navi_WarnDist_UnderDec "16.07.03_";
BA_ "GenSigSendType" SG_ 1601 Navi_WarnDist_UnderDec 4;
BA_ "GenSigStartValue" SG_ 1601 Navi_WarnDist_UnderDec 15;
BA_ "UserSigValidity" SG_ 1601 Navi_WarnDist_UnderDec 1;
BA_ "GenSigTimeoutTime" SG_ 1601 Navi_WarnDist_UnderDec 1500;
BA_ "Version" SG_ 1601 Navi_WarnDist_UnderDec "18.12.06";
BA_ "GenMsgSendType" BO_ 1255 0;
BA_ "Description" SG_ 1255 Navi_OverSpdAlarm "18.08.09_";
BA_ "GenSigSendType" SG_ 1255 Navi_OverSpdAlarm 4;
BA_ "GenSigStartValue" SG_ 1255 Navi_OverSpdAlarm 3;
BA_ "UserSigValidity" SG_ 1255 Navi_OverSpdAlarm 1;
BA_ "GenSigTimeoutTime" SG_ 1255 Navi_OverSpdAlarm 1500;
BA_ "NetworkRequest" SG_ 1255 Navi_OverSpdAlarm 0;
BA_ "Version" SG_ 1255 Navi_OverSpdAlarm "18.09.02";
BA_ "Description" SG_ 1255 Navi_WarningZone2 "17.12.06_";
BA_ "GenSigSendType" SG_ 1255 Navi_WarningZone2 4;
BA_ "GenSigStartValue" SG_ 1255 Navi_WarningZone2 31;
BA_ "UserSigValidity" SG_ 1255 Navi_WarningZone2 1;
BA_ "GenSigTimeoutTime" SG_ 1255 Navi_WarningZone2 1500;
BA_ "Version" SG_ 1255 Navi_WarningZone2 "18.06.03";
BA_ "Description" SG_ 1255 Navi_NonSpdTrap "16.03.03_";
BA_ "GenSigSendType" SG_ 1255 Navi_NonSpdTrap 4;
BA_ "GenSigStartValue" SG_ 1255 Navi_NonSpdTrap 31;
BA_ "UserSigValidity" SG_ 1255 Navi_NonSpdTrap 1;
BA_ "GenSigTimeoutTime" SG_ 1255 Navi_NonSpdTrap 1500;
BA_ "Version" SG_ 1255 Navi_NonSpdTrap "18.06.03";
BA_ "Description" SG_ 1255 Navi_WarningZone3 "17.12.06_";
BA_ "GenSigSendType" SG_ 1255 Navi_WarningZone3 4;
BA_ "GenSigStartValue" SG_ 1255 Navi_WarningZone3 15;
BA_ "UserSigValidity" SG_ 1255 Navi_WarningZone3 1;
BA_ "GenSigTimeoutTime" SG_ 1255 Navi_WarningZone3 1500;
BA_ "Version" SG_ 1255 Navi_WarningZone3 "18.06.03";
BA_ "Description" SG_ 1255 Navi_WarningZone "16.03.03_";
BA_ "GenSigSendType" SG_ 1255 Navi_WarningZone 4;
BA_ "GenSigStartValue" SG_ 1255 Navi_WarningZone 15;
BA_ "UserSigValidity" SG_ 1255 Navi_WarningZone 1;
BA_ "GenSigTimeoutTime" SG_ 1255 Navi_WarningZone 1500;
BA_ "Version" SG_ 1255 Navi_WarningZone "18.06.03";
BA_ "Description" SG_ 1255 Navi_CurveWarning "17.12.06_";
BA_ "GenSigSendType" SG_ 1255 Navi_CurveWarning 4;
BA_ "GenSigStartValue" SG_ 1255 Navi_CurveWarning 15;
BA_ "UserSigValidity" SG_ 1255 Navi_CurveWarning 1;
BA_ "GenSigTimeoutTime" SG_ 1255 Navi_CurveWarning 1500;
BA_ "NetworkRequest" SG_ 1255 Navi_CurveWarning 0;
BA_ "Version" SG_ 1255 Navi_CurveWarning "18.06.03";
BA_ "Description" SG_ 1255 Navi_SpdInfo_Type "17.03.05_권장 : 고급형 2.0, 표준형 4.5(DH)의 수출향과 향후 플랫폼은 Navi_FixedSpdTrap, Navi_MobileSpdTrap, Navi)SpdRedlightTrap 신호 대신 이 신호 사용.";
BA_ "GenSigSendType" SG_ 1255 Navi_SpdInfo_Type 4;
BA_ "GenSigStartValue" SG_ 1255 Navi_SpdInfo_Type 15;
BA_ "UserSigValidity" SG_ 1255 Navi_SpdInfo_Type 1;
BA_ "GenSigTimeoutTime" SG_ 1255 Navi_SpdInfo_Type 1500;
BA_ "Version" SG_ 1255 Navi_SpdInfo_Type "18.06.03";
BA_ "Description" SG_ 1255 Navi_SpdLimit_Unit "16.03.03_";
BA_ "GenSigSendType" SG_ 1255 Navi_SpdLimit_Unit 4;
BA_ "GenSigStartValue" SG_ 1255 Navi_SpdLimit_Unit 3;
BA_ "UserSigValidity" SG_ 1255 Navi_SpdLimit_Unit 1;
BA_ "GenSigTimeoutTime" SG_ 1255 Navi_SpdLimit_Unit 1500;
BA_ "NetworkRequest" SG_ 1255 Navi_SpdLimit_Unit 0;
BA_ "Version" SG_ 1255 Navi_SpdLimit_Unit "18.06.03";
BA_ "Description" SG_ 1255 Navi_SpdLimit_Type "16.03.03_";
BA_ "GenSigSendType" SG_ 1255 Navi_SpdLimit_Type 4;
BA_ "GenSigStartValue" SG_ 1255 Navi_SpdLimit_Type 3;
BA_ "UserSigValidity" SG_ 1255 Navi_SpdLimit_Type 1;
BA_ "GenSigTimeoutTime" SG_ 1255 Navi_SpdLimit_Type 1500;
BA_ "NetworkRequest" SG_ 1255 Navi_SpdLimit_Type 0;
BA_ "Version" SG_ 1255 Navi_SpdLimit_Type "18.06.03";
BA_ "UsrSigIDS" SG_ 1255 Navi_SpdLimit 0;
BA_ "Description" SG_ 1255 Navi_SpdLimit "16.03.03_";
BA_ "GenSigSendType" SG_ 1255 Navi_SpdLimit 4;
BA_ "GenSigStartValue" SG_ 1255 Navi_SpdLimit 255;
BA_ "UserSigValidity" SG_ 1255 Navi_SpdLimit 1;
BA_ "GenSigTimeoutTime" SG_ 1255 Navi_SpdLimit 1500;
BA_ "NetworkRequest" SG_ 1255 Navi_SpdLimit 0;
BA_ "Version" SG_ 1255 Navi_SpdLimit "18.06.03";
BA_ "GenMsgSendType" BO_ 1256 0;
BA_ "Description" SG_ 1256 NV_EstDist_Unit "18.08.09_";
BA_ "GenSigSendType" SG_ 1256 NV_EstDist_Unit 4;
BA_ "GenSigStartValue" SG_ 1256 NV_EstDist_Unit 15;
BA_ "UserSigValidity" SG_ 1256 NV_EstDist_Unit 1;
BA_ "GenSigTimeoutTime" SG_ 1256 NV_EstDist_Unit 1500;
BA_ "Version" SG_ 1256 NV_EstDist_Unit "18.09.02";
BA_ "Description" SG_ 1256 NV_EstMin "18.08.09_";
BA_ "GenSigSendType" SG_ 1256 NV_EstMin 4;
BA_ "GenSigStartValue" SG_ 1256 NV_EstMin 255;
BA_ "UserSigValidity" SG_ 1256 NV_EstMin 1;
BA_ "GenSigTimeoutTime" SG_ 1256 NV_EstMin 1500;
BA_ "Version" SG_ 1256 NV_EstMin "18.09.02";
BA_ "UsrSigIDS" SG_ 1256 NV_Azimuth 0;
BA_ "Description" SG_ 1256 NV_Azimuth "18.08.09_";
BA_ "GenSigSendType" SG_ 1256 NV_Azimuth 4;
BA_ "GenSigStartValue" SG_ 1256 NV_Azimuth 255;
BA_ "UserSigValidity" SG_ 1256 NV_Azimuth 1;
BA_ "GenSigTimeoutTime" SG_ 1256 NV_Azimuth 1500;
BA_ "Version" SG_ 1256 NV_Azimuth "18.09.02";
BA_ "Description" SG_ 1256 NV_EstDist_I "18.08.09_";
BA_ "GenSigSendType" SG_ 1256 NV_EstDist_I 4;
BA_ "GenSigStartValue" SG_ 1256 NV_EstDist_I 65535;
BA_ "UserSigValidity" SG_ 1256 NV_EstDist_I 1;
BA_ "GenSigTimeoutTime" SG_ 1256 NV_EstDist_I 1500;
BA_ "Version" SG_ 1256 NV_EstDist_I "18.09.02";
BA_ "Description" SG_ 1256 NV_EstDist_F "18.08.09_";
BA_ "GenSigSendType" SG_ 1256 NV_EstDist_F 4;
BA_ "GenSigStartValue" SG_ 1256 NV_EstDist_F 15;
BA_ "UserSigValidity" SG_ 1256 NV_EstDist_F 1;
BA_ "GenSigTimeoutTime" SG_ 1256 NV_EstDist_F 1500;
BA_ "Version" SG_ 1256 NV_EstDist_F "18.09.02";
BA_ "Description" SG_ 1256 NV_EstPointType "18.08.09_";
BA_ "GenSigSendType" SG_ 1256 NV_EstPointType 4;
BA_ "GenSigStartValue" SG_ 1256 NV_EstPointType 15;
BA_ "UserSigValidity" SG_ 1256 NV_EstPointType 1;
BA_ "GenSigTimeoutTime" SG_ 1256 NV_EstPointType 1500;
BA_ "Version" SG_ 1256 NV_EstPointType "18.09.02";
BA_ "Description" SG_ 1256 NV_EstimTimeFormat "18.08.09_";
BA_ "GenSigSendType" SG_ 1256 NV_EstimTimeFormat 4;
BA_ "GenSigStartValue" SG_ 1256 NV_EstimTimeFormat 3;
BA_ "UserSigValidity" SG_ 1256 NV_EstimTimeFormat 1;
BA_ "GenSigTimeoutTime" SG_ 1256 NV_EstimTimeFormat 1500;
BA_ "Version" SG_ 1256 NV_EstimTimeFormat "18.09.02";
BA_ "Description" SG_ 1256 NV_EstimTimeType "18.08.09_";
BA_ "GenSigSendType" SG_ 1256 NV_EstimTimeType 4;
BA_ "GenSigStartValue" SG_ 1256 NV_EstimTimeType 3;
BA_ "UserSigValidity" SG_ 1256 NV_EstimTimeType 1;
BA_ "GenSigTimeoutTime" SG_ 1256 NV_EstimTimeType 1500;
BA_ "Version" SG_ 1256 NV_EstimTimeType "18.09.02";
BA_ "Description" SG_ 1256 NV_EstHour "18.08.09_";
BA_ "GenSigSendType" SG_ 1256 NV_EstHour 4;
BA_ "GenSigStartValue" SG_ 1256 NV_EstHour 255;
BA_ "UserSigValidity" SG_ 1256 NV_EstHour 1;
BA_ "GenSigTimeoutTime" SG_ 1256 NV_EstHour 1500;
BA_ "Version" SG_ 1256 NV_EstHour "18.09.02";
BA_ "GenMsgCycleTime" BO_ 1185 0;
BA_ "GenMsgDelayTime" BO_ 1185 0;
BA_ "Description" SG_ 1185 C_AstWindowCmdAVN "18.08.16_";
BA_ "GenSigSendType" SG_ 1185 C_AstWindowCmdAVN 4;
BA_ "GenSigStartValue" SG_ 1185 C_AstWindowCmdAVN 7;
BA_ "UserSigValidity" SG_ 1185 C_AstWindowCmdAVN 0;
BA_ "GenSigTimeoutTime" SG_ 1185 C_AstWindowCmdAVN 0;
BA_ "Version" SG_ 1185 C_AstWindowCmdAVN "18.09.02";
BA_ "Description" SG_ 1185 C_StrgWhlHeatedCmdAVN "18.08.09_";
BA_ "GenSigSendType" SG_ 1185 C_StrgWhlHeatedCmdAVN 4;
BA_ "GenSigStartValue" SG_ 1185 C_StrgWhlHeatedCmdAVN 3;
BA_ "UserSigValidity" SG_ 1185 C_StrgWhlHeatedCmdAVN 4;
BA_ "GenSigTimeoutTime" SG_ 1185 C_StrgWhlHeatedCmdAVN 0;
BA_ "Version" SG_ 1185 C_StrgWhlHeatedCmdAVN "18.09.02";
BA_ "Description" SG_ 1185 C_RrDefoggerCmdAVN "18.08.09_";
BA_ "GenSigSendType" SG_ 1185 C_RrDefoggerCmdAVN 4;
BA_ "GenSigStartValue" SG_ 1185 C_RrDefoggerCmdAVN 3;
BA_ "UserSigValidity" SG_ 1185 C_RrDefoggerCmdAVN 3;
BA_ "GenSigTimeoutTime" SG_ 1185 C_RrDefoggerCmdAVN 0;
BA_ "Version" SG_ 1185 C_RrDefoggerCmdAVN "18.09.02";
BA_ "Description" SG_ 1185 C_AVNIMSButtonCmd "18.08.16_";
BA_ "GenSigSendType" SG_ 1185 C_AVNIMSButtonCmd 4;
BA_ "GenSigStartValue" SG_ 1185 C_AVNIMSButtonCmd 7;
BA_ "UserSigValidity" SG_ 1185 C_AVNIMSButtonCmd 0;
BA_ "GenSigTimeoutTime" SG_ 1185 C_AVNIMSButtonCmd 0;
BA_ "Version" SG_ 1185 C_AVNIMSButtonCmd "18.09.02";
BA_ "Description" SG_ 1185 C_RRWindowCmdAVN "18.08.16_";
BA_ "GenSigSendType" SG_ 1185 C_RRWindowCmdAVN 4;
BA_ "GenSigStartValue" SG_ 1185 C_RRWindowCmdAVN 7;
BA_ "UserSigValidity" SG_ 1185 C_RRWindowCmdAVN 0;
BA_ "GenSigTimeoutTime" SG_ 1185 C_RRWindowCmdAVN 0;
BA_ "Version" SG_ 1185 C_RRWindowCmdAVN "18.09.02";
BA_ "Description" SG_ 1185 C_RLWindowCmdAVN "18.08.16_";
BA_ "GenSigSendType" SG_ 1185 C_RLWindowCmdAVN 4;
BA_ "GenSigStartValue" SG_ 1185 C_RLWindowCmdAVN 7;
BA_ "UserSigValidity" SG_ 1185 C_RLWindowCmdAVN 0;
BA_ "GenSigTimeoutTime" SG_ 1185 C_RLWindowCmdAVN 0;
BA_ "Version" SG_ 1185 C_RLWindowCmdAVN "18.09.02";
BA_ "Description" SG_ 1185 C_BlindCmdAVN "18.08.09_";
BA_ "GenSigSendType" SG_ 1185 C_BlindCmdAVN 4;
BA_ "GenSigStartValue" SG_ 1185 C_BlindCmdAVN 7;
BA_ "UserSigValidity" SG_ 1185 C_BlindCmdAVN 1;
BA_ "GenSigTimeoutTime" SG_ 1185 C_BlindCmdAVN 0;
BA_ "Version" SG_ 1185 C_BlindCmdAVN "18.09.02";
BA_ "Description" SG_ 1185 C_GlassCmdAVN "18.08.09_";
BA_ "GenSigSendType" SG_ 1185 C_GlassCmdAVN 4;
BA_ "GenSigStartValue" SG_ 1185 C_GlassCmdAVN 7;
BA_ "UserSigValidity" SG_ 1185 C_GlassCmdAVN 1;
BA_ "GenSigTimeoutTime" SG_ 1185 C_GlassCmdAVN 0;
BA_ "Version" SG_ 1185 C_GlassCmdAVN "18.09.02";
BA_ "Description" SG_ 1185 C_CluDispCmdAVN "18.06.00_";
BA_ "GenSigSendType" SG_ 1185 C_CluDispCmdAVN 4;
BA_ "GenSigStartValue" SG_ 1185 C_CluDispCmdAVN 7;
BA_ "UserSigValidity" SG_ 1185 C_CluDispCmdAVN 3;
BA_ "GenSigTimeoutTime" SG_ 1185 C_CluDispCmdAVN 0;
BA_ "Version" SG_ 1185 C_CluDispCmdAVN "18.06.04";
BA_ "Description" SG_ 1185 C_DrvWindowCmdAVN "18.08.16_";
BA_ "GenSigSendType" SG_ 1185 C_DrvWindowCmdAVN 4;
BA_ "GenSigStartValue" SG_ 1185 C_DrvWindowCmdAVN 7;
BA_ "UserSigValidity" SG_ 1185 C_DrvWindowCmdAVN 0;
BA_ "GenSigTimeoutTime" SG_ 1185 C_DrvWindowCmdAVN 0;
BA_ "Version" SG_ 1185 C_DrvWindowCmdAVN "18.09.02";
BA_ "Description" SG_ 1185 C_PTGCNTLCmdAVN "18.08.09_";
BA_ "GenSigSendType" SG_ 1185 C_PTGCNTLCmdAVN 4;
BA_ "GenSigStartValue" SG_ 1185 C_PTGCNTLCmdAVN 3;
BA_ "UserSigValidity" SG_ 1185 C_PTGCNTLCmdAVN 3;
BA_ "GenSigTimeoutTime" SG_ 1185 C_PTGCNTLCmdAVN 0;
BA_ "Version" SG_ 1185 C_PTGCNTLCmdAVN "18.09.02";
BA_ "GenMsgSendType" BO_ 1239 0;
BA_ "Description" SG_ 1239 HU_VehiclePwr "18.03.01_[Default Value]
0x0
[KBD Wake-up Condition]
Door Open/Door Unlock/Welcome On (Pre-booting from Vehicle interrupt)";
BA_ "GenSigSendType" SG_ 1239 HU_VehiclePwr 4;
BA_ "UserSigValidity" SG_ 1239 HU_VehiclePwr 0;
BA_ "GenSigTimeoutTime" SG_ 1239 HU_VehiclePwr 1500;
BA_ "NetworkRequest" SG_ 1239 HU_VehiclePwr 0;
BA_ "NetworkRequestHoldingTime" SG_ 1239 HU_VehiclePwr 5000;
BA_ "Version" SG_ 1239 HU_VehiclePwr "19.02.08";
BA_ "GenMsgCycleTime" BO_ 1183 0;
BA_ "GenMsgDelayTime" BO_ 1183 0;
BA_ "Description" SG_ 1183 HU_DATC_MainBlower "18.08.09_";
BA_ "GenSigSendType" SG_ 1183 HU_DATC_MainBlower 4;
BA_ "GenSigStartValue" SG_ 1183 HU_DATC_MainBlower 15;
BA_ "UserSigValidity" SG_ 1183 HU_DATC_MainBlower 3;
BA_ "GenSigTimeoutTime" SG_ 1183 HU_DATC_MainBlower 0;
BA_ "Version" SG_ 1183 HU_DATC_MainBlower "18.09.02";
BA_ "Description" SG_ 1183 HU_DATC_FrontModeSet "19.01.00_";
BA_ "GenSigSendType" SG_ 1183 HU_DATC_FrontModeSet 4;
BA_ "GenSigStartValue" SG_ 1183 HU_DATC_FrontModeSet 15;
BA_ "UserSigValidity" SG_ 1183 HU_DATC_FrontModeSet 3;
BA_ "GenSigTimeoutTime" SG_ 1183 HU_DATC_FrontModeSet 0;
BA_ "Version" SG_ 1183 HU_DATC_FrontModeSet "19.01.02";
BA_ "Description" SG_ 1183 HU_DATC_IntakeSet "18.08.09_";
BA_ "GenSigSendType" SG_ 1183 HU_DATC_IntakeSet 4;
BA_ "GenSigStartValue" SG_ 1183 HU_DATC_IntakeSet 3;
BA_ "UserSigValidity" SG_ 1183 HU_DATC_IntakeSet 3;
BA_ "GenSigTimeoutTime" SG_ 1183 HU_DATC_IntakeSet 0;
BA_ "Version" SG_ 1183 HU_DATC_IntakeSet "18.09.02";
BA_ "Description" SG_ 1183 HU_DATC_AutoSet "18.08.09_";
BA_ "GenSigSendType" SG_ 1183 HU_DATC_AutoSet 4;
BA_ "GenSigStartValue" SG_ 1183 HU_DATC_AutoSet 3;
BA_ "UserSigValidity" SG_ 1183 HU_DATC_AutoSet 3;
BA_ "GenSigTimeoutTime" SG_ 1183 HU_DATC_AutoSet 0;
BA_ "Version" SG_ 1183 HU_DATC_AutoSet "18.09.02";
BA_ "Description" SG_ 1183 HU_DATC_FrontDefog "18.08.09_";
BA_ "GenSigSendType" SG_ 1183 HU_DATC_FrontDefog 4;
BA_ "GenSigStartValue" SG_ 1183 HU_DATC_FrontDefog 3;
BA_ "UserSigValidity" SG_ 1183 HU_DATC_FrontDefog 3;
BA_ "GenSigTimeoutTime" SG_ 1183 HU_DATC_FrontDefog 0;
BA_ "Version" SG_ 1183 HU_DATC_FrontDefog "18.09.02";
BA_ "Description" SG_ 1183 HU_DATC_AcSet "18.08.09_";
BA_ "GenSigSendType" SG_ 1183 HU_DATC_AcSet 4;
BA_ "GenSigStartValue" SG_ 1183 HU_DATC_AcSet 3;
BA_ "UserSigValidity" SG_ 1183 HU_DATC_AcSet 3;
BA_ "GenSigTimeoutTime" SG_ 1183 HU_DATC_AcSet 0;
BA_ "Version" SG_ 1183 HU_DATC_AcSet "18.09.02";
BA_ "Description" SG_ 1183 HU_DATC_AirCleaningSet "18.08.09_";
BA_ "GenSigSendType" SG_ 1183 HU_DATC_AirCleaningSet 4;
BA_ "GenSigStartValue" SG_ 1183 HU_DATC_AirCleaningSet 3;
BA_ "UserSigValidity" SG_ 1183 HU_DATC_AirCleaningSet 3;
BA_ "GenSigTimeoutTime" SG_ 1183 HU_DATC_AirCleaningSet 0;
BA_ "Version" SG_ 1183 HU_DATC_AirCleaningSet "18.09.02";
BA_ "Description" SG_ 1183 HU_DATC_MainBlowerUpDn "18.08.09_";
BA_ "GenSigSendType" SG_ 1183 HU_DATC_MainBlowerUpDn 4;
BA_ "GenSigStartValue" SG_ 1183 HU_DATC_MainBlowerUpDn 3;
BA_ "UserSigValidity" SG_ 1183 HU_DATC_MainBlowerUpDn 3;
BA_ "GenSigTimeoutTime" SG_ 1183 HU_DATC_MainBlowerUpDn 0;
BA_ "Version" SG_ 1183 HU_DATC_MainBlowerUpDn "18.09.02";
BA_ "Description" SG_ 1183 HU_DATC_DrTempUpDn "18.08.09_";
BA_ "GenSigSendType" SG_ 1183 HU_DATC_DrTempUpDn 4;
BA_ "GenSigStartValue" SG_ 1183 HU_DATC_DrTempUpDn 3;
BA_ "UserSigValidity" SG_ 1183 HU_DATC_DrTempUpDn 3;
BA_ "GenSigTimeoutTime" SG_ 1183 HU_DATC_DrTempUpDn 0;
BA_ "Version" SG_ 1183 HU_DATC_DrTempUpDn "18.09.02";
BA_ "GenMsgCycleTime" BO_ 1184 0;
BA_ "GenMsgDelayTime" BO_ 1184 0;
BA_ "UsrSigIDS" SG_ 1184 HU_DATC_DrTempSetC 0;
BA_ "Description" SG_ 1184 HU_DATC_DrTempSetC "18.08.09_";
BA_ "GenSigSendType" SG_ 1184 HU_DATC_DrTempSetC 4;
BA_ "GenSigStartValue" SG_ 1184 HU_DATC_DrTempSetC 255;
BA_ "UserSigValidity" SG_ 1184 HU_DATC_DrTempSetC 3;
BA_ "GenSigTimeoutTime" SG_ 1184 HU_DATC_DrTempSetC 0;
BA_ "Version" SG_ 1184 HU_DATC_DrTempSetC "18.09.02";
BA_ "UsrSigIDS" SG_ 1184 HU_DATC_DrTempSetF 0;
BA_ "Description" SG_ 1184 HU_DATC_DrTempSetF "18.08.09_";
BA_ "GenSigSendType" SG_ 1184 HU_DATC_DrTempSetF 4;
BA_ "GenSigStartValue" SG_ 1184 HU_DATC_DrTempSetF 255;
BA_ "UserSigValidity" SG_ 1184 HU_DATC_DrTempSetF 3;
BA_ "GenSigTimeoutTime" SG_ 1184 HU_DATC_DrTempSetF 0;
BA_ "Version" SG_ 1184 HU_DATC_DrTempSetF "18.09.02";
BA_ "GenMsgSendType" BO_ 1267 0;
BA_ "GenMsgCycleTime" BO_ 1267 1000;
BA_ "Description" SG_ 1267 HU_PhoneActivity "18.08.09_";
BA_ "GenSigSendType" SG_ 1267 HU_PhoneActivity 4;
BA_ "GenSigStartValue" SG_ 1267 HU_PhoneActivity 3;
BA_ "UserSigValidity" SG_ 1267 HU_PhoneActivity 1;
BA_ "GenSigTimeoutTime" SG_ 1267 HU_PhoneActivity 5000;
BA_ "NetworkRequest" SG_ 1267 HU_PhoneActivity 0;
BA_ "Version" SG_ 1267 HU_PhoneActivity "19.02.08";
BA_ "Description" SG_ 1267 HU_VRActivity "18.08.09_";
BA_ "GenSigSendType" SG_ 1267 HU_VRActivity 4;
BA_ "GenSigStartValue" SG_ 1267 HU_VRActivity 3;
BA_ "UserSigValidity" SG_ 1267 HU_VRActivity 1;
BA_ "GenSigTimeoutTime" SG_ 1267 HU_VRActivity 5000;
BA_ "NetworkRequest" SG_ 1267 HU_VRActivity 0;
BA_ "Version" SG_ 1267 HU_VRActivity "19.02.08";
BA_ "GenMsgSendType" BO_ 1240 0;
BA_ "Description" SG_ 1240 CF_AVN_ProfileIDRValue "18.08.22_This signal is only used in User Profile applied H/Unit";
BA_ "GenSigSendType" SG_ 1240 CF_AVN_ProfileIDRValue 4;
BA_ "GenSigStartValue" SG_ 1240 CF_AVN_ProfileIDRValue 15;
BA_ "UserSigValidity" SG_ 1240 CF_AVN_ProfileIDRValue 0;
BA_ "GenSigTimeoutTime" SG_ 1240 CF_AVN_ProfileIDRValue 1500;
BA_ "Version" SG_ 1240 CF_AVN_ProfileIDRValue "18.09.04";
BA_ "Description" SG_ 1240 HU_AliveStatus "18.08.22_";
BA_ "GenSigSendType" SG_ 1240 HU_AliveStatus 4;
BA_ "GenSigStartValue" SG_ 1240 HU_AliveStatus 3;
BA_ "UserSigValidity" SG_ 1240 HU_AliveStatus 0;
BA_ "GenSigTimeoutTime" SG_ 1240 HU_AliveStatus 1500;
BA_ "NetworkRequest" SG_ 1240 HU_AliveStatus 0;
BA_ "Version" SG_ 1240 HU_AliveStatus "19.02.08";
BA_ "GenMsgSendType" BO_ 1278 0;
BA_ "GenMsgCycleTime" BO_ 1278 2000;
BA_ "Description" SG_ 1278 HU_Type "18.08.09_";
BA_ "GenSigSendType" SG_ 1278 HU_Type 4;
BA_ "GenSigStartValue" SG_ 1278 HU_Type 255;
BA_ "UserSigValidity" SG_ 1278 HU_Type 1;
BA_ "GenSigTimeoutTime" SG_ 1278 HU_Type 5000;
BA_ "NetworkRequest" SG_ 1278 HU_Type 0;
BA_ "Version" SG_ 1278 HU_Type "18.09.04";
BA_ "Description" SG_ 1278 HU_DistributeInfo "18.08.09_";
BA_ "GenSigSendType" SG_ 1278 HU_DistributeInfo 4;
BA_ "GenSigStartValue" SG_ 1278 HU_DistributeInfo 255;
BA_ "UserSigValidity" SG_ 1278 HU_DistributeInfo 1;
BA_ "GenSigTimeoutTime" SG_ 1278 HU_DistributeInfo 5000;
BA_ "NetworkRequest" SG_ 1278 HU_DistributeInfo 0;
BA_ "Version" SG_ 1278 HU_DistributeInfo "18.09.04";
BA_ "Description" SG_ 1278 HU_OptionInfo "18.08.09_Bit0 : Navi (0: Not Support / 1: Support)
Bit1 : USM (0: Not Support / 1: Support)
Bit2 : TMS (0: Not Support / 1: Support)
Bit3 : Multi Profile (0: Not Support(No Profile or Single Profile)  / 1: Support)
Bit4 : Camera Guideline (0: Displayed by Camera / 1: Displayed by H/U)
Bit5 : LVDS Interface (0:MIPI, 1:Non-MIPI)
Bit6~Bit14 : Reserved
Bit15 : 1 Invalid";
BA_ "GenSigSendType" SG_ 1278 HU_OptionInfo 4;
BA_ "GenSigStartValue" SG_ 1278 HU_OptionInfo 32768;
BA_ "UserSigValidity" SG_ 1278 HU_OptionInfo 1;
BA_ "GenSigTimeoutTime" SG_ 1278 HU_OptionInfo 5000;
BA_ "Version" SG_ 1278 HU_OptionInfo "18.09.04";
BA_ "Description" SG_ 1278 HU_AdasSupport "18.08.09_";
BA_ "GenSigSendType" SG_ 1278 HU_AdasSupport 4;
BA_ "GenSigStartValue" SG_ 1278 HU_AdasSupport 7;
BA_ "UserSigValidity" SG_ 1278 HU_AdasSupport 1;
BA_ "GenSigTimeoutTime" SG_ 1278 HU_AdasSupport 5000;
BA_ "NetworkRequest" SG_ 1278 HU_AdasSupport 0;
BA_ "Version" SG_ 1278 HU_AdasSupport "18.09.04";
BA_ "GenMsgSendType" BO_ 1246 0;
BA_ "Description" SG_ 1246 POS_V2_Offset "18.08.09_[Default Value]
0x1FFF";
BA_ "GenSigSendType" SG_ 1246 POS_V2_Offset 4;
BA_ "GenSigStartValue" SG_ 1246 POS_V2_Offset 8191;
BA_ "UserSigValidity" SG_ 1246 POS_V2_Offset 3;
BA_ "GenSigTimeoutTime" SG_ 1246 POS_V2_Offset 1500;
BA_ "Version" SG_ 1246 POS_V2_Offset "18.09.04";
BA_ "Description" SG_ 1246 POS_V2_CyclicCounter "18.08.09_[Default Value]
0x0";
BA_ "GenSigSendType" SG_ 1246 POS_V2_CyclicCounter 4;
BA_ "UserSigValidity" SG_ 1246 POS_V2_CyclicCounter 3;
BA_ "GenSigTimeoutTime" SG_ 1246 POS_V2_CyclicCounter 1500;
BA_ "Version" SG_ 1246 POS_V2_CyclicCounter "18.09.04";
BA_ "Description" SG_ 1246 POS_V2_RangeAvgSpeed "18.08.09_[Default Value]
0x0";
BA_ "GenSigSendType" SG_ 1246 POS_V2_RangeAvgSpeed 4;
BA_ "GenSigStartValue" SG_ 1246 POS_V2_RangeAvgSpeed 511;
BA_ "UserSigValidity" SG_ 1246 POS_V2_RangeAvgSpeed 3;
BA_ "GenSigTimeoutTime" SG_ 1246 POS_V2_RangeAvgSpeed 1500;
BA_ "Version" SG_ 1246 POS_V2_RangeAvgSpeed "18.09.04";
BA_ "GenMsgCycleTime" BO_ 1208 0;
BA_ "GenMsgDelayTime" BO_ 1208 0;
BA_ "Description" SG_ 1208 PROLONG_V2_Value "18.08.09_[Default Value]

0xFFFFFFFF";
BA_ "GenSigSendType" SG_ 1208 PROLONG_V2_Value 4;
BA_ "UserSigValidity" SG_ 1208 PROLONG_V2_Value 3;
BA_ "GenSigTimeoutTime" SG_ 1208 PROLONG_V2_Value 0;
BA_ "Version" SG_ 1208 PROLONG_V2_Value "18.09.04";
BA_ "Description" SG_ 1208 PROLONG_V2_Offset "18.08.09_[Default Value]
0x1FFF";
BA_ "GenSigSendType" SG_ 1208 PROLONG_V2_Offset 4;
BA_ "GenSigStartValue" SG_ 1208 PROLONG_V2_Offset 8191;
BA_ "UserSigValidity" SG_ 1208 PROLONG_V2_Offset 3;
BA_ "GenSigTimeoutTime" SG_ 1208 PROLONG_V2_Offset 0;
BA_ "Version" SG_ 1208 PROLONG_V2_Offset "18.09.04";
BA_ "Description" SG_ 1208 PROLONG_V2_CyclicCounter "18.08.09_[Default Value]
0x0";
BA_ "GenSigSendType" SG_ 1208 PROLONG_V2_CyclicCounter 4;
BA_ "UserSigValidity" SG_ 1208 PROLONG_V2_CyclicCounter 3;
BA_ "GenSigTimeoutTime" SG_ 1208 PROLONG_V2_CyclicCounter 0;
BA_ "Version" SG_ 1208 PROLONG_V2_CyclicCounter "18.09.04";
BA_ "Description" SG_ 1208 PROLONG_V2_Update "18.08.09_[Default Value]
0x0";
BA_ "GenSigSendType" SG_ 1208 PROLONG_V2_Update 4;
BA_ "UserSigValidity" SG_ 1208 PROLONG_V2_Update 3;
BA_ "GenSigTimeoutTime" SG_ 1208 PROLONG_V2_Update 0;
BA_ "Version" SG_ 1208 PROLONG_V2_Update "18.09.04";
BA_ "Description" SG_ 1208 PROLONG_V2_ProfileType "18.08.09_[Default Value]
0x0";
BA_ "GenSigSendType" SG_ 1208 PROLONG_V2_ProfileType 4;
BA_ "UserSigValidity" SG_ 1208 PROLONG_V2_ProfileType 3;
BA_ "GenSigTimeoutTime" SG_ 1208 PROLONG_V2_ProfileType 0;
BA_ "Version" SG_ 1208 PROLONG_V2_ProfileType "18.09.04";
BA_ "GenMsgCycleTime" BO_ 1207 0;
BA_ "GenMsgDelayTime" BO_ 1207 0;
BA_ "Description" SG_ 1207 PROSHORT_V2_Offset "18.08.09_[Default Value]
0x1FFF";
BA_ "GenSigSendType" SG_ 1207 PROSHORT_V2_Offset 4;
BA_ "GenSigStartValue" SG_ 1207 PROSHORT_V2_Offset 8191;
BA_ "UserSigValidity" SG_ 1207 PROSHORT_V2_Offset 3;
BA_ "GenSigTimeoutTime" SG_ 1207 PROSHORT_V2_Offset 0;
BA_ "Version" SG_ 1207 PROSHORT_V2_Offset "18.09.04";
BA_ "Description" SG_ 1207 PROSHORT_V2_CyclicCounter "18.08.09_[Default Value]
0x0";
BA_ "GenSigSendType" SG_ 1207 PROSHORT_V2_CyclicCounter 4;
BA_ "UserSigValidity" SG_ 1207 PROSHORT_V2_CyclicCounter 3;
BA_ "GenSigTimeoutTime" SG_ 1207 PROSHORT_V2_CyclicCounter 0;
BA_ "Version" SG_ 1207 PROSHORT_V2_CyclicCounter "18.09.04";
BA_ "Description" SG_ 1207 PROSHORT_V2_Distance "18.08.09_[Default Value]
0x3FF";
BA_ "GenSigSendType" SG_ 1207 PROSHORT_V2_Distance 4;
BA_ "GenSigStartValue" SG_ 1207 PROSHORT_V2_Distance 1023;
BA_ "UserSigValidity" SG_ 1207 PROSHORT_V2_Distance 3;
BA_ "GenSigTimeoutTime" SG_ 1207 PROSHORT_V2_Distance 0;
BA_ "Version" SG_ 1207 PROSHORT_V2_Distance "18.09.04";
BA_ "Description" SG_ 1207 PROSHORT_V2_Value0 "18.08.09_[Default Value]
0x3FF";
BA_ "GenSigSendType" SG_ 1207 PROSHORT_V2_Value0 4;
BA_ "GenSigStartValue" SG_ 1207 PROSHORT_V2_Value0 1023;
BA_ "UserSigValidity" SG_ 1207 PROSHORT_V2_Value0 3;
BA_ "GenSigTimeoutTime" SG_ 1207 PROSHORT_V2_Value0 0;
BA_ "Version" SG_ 1207 PROSHORT_V2_Value0 "18.09.04";
BA_ "Description" SG_ 1207 PROSHORT_V2_Value1 "18.08.09_[Default Value]
0x3FF";
BA_ "GenSigSendType" SG_ 1207 PROSHORT_V2_Value1 4;
BA_ "GenSigStartValue" SG_ 1207 PROSHORT_V2_Value1 1023;
BA_ "UserSigValidity" SG_ 1207 PROSHORT_V2_Value1 3;
BA_ "GenSigTimeoutTime" SG_ 1207 PROSHORT_V2_Value1 0;
BA_ "Version" SG_ 1207 PROSHORT_V2_Value1 "18.09.04";
BA_ "Description" SG_ 1207 PROSHORT_V2_ProfileType "18.08.09_[Default Value]
0x0";
BA_ "GenSigSendType" SG_ 1207 PROSHORT_V2_ProfileType 4;
BA_ "UserSigValidity" SG_ 1207 PROSHORT_V2_ProfileType 3;
BA_ "GenSigTimeoutTime" SG_ 1207 PROSHORT_V2_ProfileType 0;
BA_ "Version" SG_ 1207 PROSHORT_V2_ProfileType "18.09.04";
BA_ "GenMsgCycleTime" BO_ 1204 0;
BA_ "GenMsgDelayTime" BO_ 1204 0;
BA_ "Description" SG_ 1204 SEG_V2_Offset "18.08.09_[Default Value]
0x1FFF";
BA_ "GenSigSendType" SG_ 1204 SEG_V2_Offset 4;
BA_ "GenSigStartValue" SG_ 1204 SEG_V2_Offset 8191;
BA_ "UserSigValidity" SG_ 1204 SEG_V2_Offset 3;
BA_ "GenSigTimeoutTime" SG_ 1204 SEG_V2_Offset 0;
BA_ "Version" SG_ 1204 SEG_V2_Offset "18.09.04";
BA_ "Description" SG_ 1204 SEG_V2_CyclicCounter "18.08.09_[Default Value]
0x0";
BA_ "GenSigSendType" SG_ 1204 SEG_V2_CyclicCounter 4;
BA_ "UserSigValidity" SG_ 1204 SEG_V2_CyclicCounter 3;
BA_ "GenSigTimeoutTime" SG_ 1204 SEG_V2_CyclicCounter 0;
BA_ "Version" SG_ 1204 SEG_V2_CyclicCounter "18.09.04";
BA_ "Description" SG_ 1204 SEG_V2_Retransmission "18.08.09_[Default Value]
0x0";
BA_ "GenSigSendType" SG_ 1204 SEG_V2_Retransmission 4;
BA_ "UserSigValidity" SG_ 1204 SEG_V2_Retransmission 3;
BA_ "GenSigTimeoutTime" SG_ 1204 SEG_V2_Retransmission 0;
BA_ "Version" SG_ 1204 SEG_V2_Retransmission "18.09.04";
BA_ "Description" SG_ 1204 SEG_V2_CalculatedRoute "18.08.09_[Default Value]
0x3";
BA_ "GenSigSendType" SG_ 1204 SEG_V2_CalculatedRoute 4;
BA_ "GenSigStartValue" SG_ 1204 SEG_V2_CalculatedRoute 3;
BA_ "UserSigValidity" SG_ 1204 SEG_V2_CalculatedRoute 3;
BA_ "GenSigTimeoutTime" SG_ 1204 SEG_V2_CalculatedRoute 0;
BA_ "Version" SG_ 1204 SEG_V2_CalculatedRoute "18.09.04";
BA_ "Description" SG_ 1204 SEG_V2_FuncRoadClass "18.08.09_[Default Vaule]
0x0";
BA_ "GenSigSendType" SG_ 1204 SEG_V2_FuncRoadClass 4;
BA_ "GenSigStartValue" SG_ 1204 SEG_V2_FuncRoadClass 7;
BA_ "UserSigValidity" SG_ 1204 SEG_V2_FuncRoadClass 3;
BA_ "GenSigTimeoutTime" SG_ 1204 SEG_V2_FuncRoadClass 0;
BA_ "Version" SG_ 1204 SEG_V2_FuncRoadClass "18.09.04";
BA_ "Description" SG_ 1204 SEG_V2_SpeedLimit "18.08.09_[Default Value]
0x0";
BA_ "GenSigSendType" SG_ 1204 SEG_V2_SpeedLimit 4;
BA_ "GenSigStartValue" SG_ 1204 SEG_V2_SpeedLimit 31;
BA_ "UserSigValidity" SG_ 1204 SEG_V2_SpeedLimit 3;
BA_ "GenSigTimeoutTime" SG_ 1204 SEG_V2_SpeedLimit 0;
BA_ "Version" SG_ 1204 SEG_V2_SpeedLimit "18.09.04";
BA_ "Description" SG_ 1204 SEG_V2_FormOfWay "18.08.09_[Default Value]
0x0";
BA_ "GenSigSendType" SG_ 1204 SEG_V2_FormOfWay 4;
BA_ "GenSigStartValue" SG_ 1204 SEG_V2_FormOfWay 15;
BA_ "UserSigValidity" SG_ 1204 SEG_V2_FormOfWay 3;
BA_ "GenSigTimeoutTime" SG_ 1204 SEG_V2_FormOfWay 0;
BA_ "Version" SG_ 1204 SEG_V2_FormOfWay "18.09.04";
BA_ "Description" SG_ 1204 SEG_V2_DirectionLanes "18.08.09_[Default Value]
0x0";
BA_ "GenSigSendType" SG_ 1204 SEG_V2_DirectionLanes 4;
BA_ "GenSigStartValue" SG_ 1204 SEG_V2_DirectionLanes 15;
BA_ "UserSigValidity" SG_ 1204 SEG_V2_DirectionLanes 3;
BA_ "GenSigTimeoutTime" SG_ 1204 SEG_V2_DirectionLanes 0;
BA_ "Version" SG_ 1204 SEG_V2_DirectionLanes "18.09.04";
BA_ "Description" SG_ 1204 SEG_V2_SpeedLimitUnder5 "18.08.09_[Default Value]

0x0";
BA_ "GenSigSendType" SG_ 1204 SEG_V2_SpeedLimitUnder5 4;
BA_ "GenSigStartValue" SG_ 1204 SEG_V2_SpeedLimitUnder5 7;
BA_ "UserSigValidity" SG_ 1204 SEG_V2_SpeedLimitUnder5 3;
BA_ "GenSigTimeoutTime" SG_ 1204 SEG_V2_SpeedLimitUnder5 0;
BA_ "Version" SG_ 1204 SEG_V2_SpeedLimitUnder5 "18.09.04";
BA_ "GenMsgSendType" BO_ 1187 0;
BA_ "GenMsgStartDelayTime" BO_ 1187 130;
BA_ "Description" SG_ 1187 Navi_ISLW_LinkClass "18.08.09_";
BA_ "GenSigSendType" SG_ 1187 Navi_ISLW_LinkClass 4;
BA_ "GenSigStartValue" SG_ 1187 Navi_ISLW_LinkClass 7;
BA_ "UserSigValidity" SG_ 1187 Navi_ISLW_LinkClass 1;
BA_ "GenSigTimeoutTime" SG_ 1187 Navi_ISLW_LinkClass 1500;
BA_ "Version" SG_ 1187 Navi_ISLW_LinkClass "18.09.04";
BA_ "Description" SG_ 1187 Navi_ISLW_CountryCode "18.08.09_";
BA_ "GenSigSendType" SG_ 1187 Navi_ISLW_CountryCode 4;
BA_ "GenSigStartValue" SG_ 1187 Navi_ISLW_CountryCode 1023;
BA_ "UserSigValidity" SG_ 1187 Navi_ISLW_CountryCode 1;
BA_ "GenSigTimeoutTime" SG_ 1187 Navi_ISLW_CountryCode 1500;
BA_ "Version" SG_ 1187 Navi_ISLW_CountryCode "18.09.04";
BA_ "Description" SG_ 1187 Navi_ISLW_MapSource "18.08.09_";
BA_ "GenSigSendType" SG_ 1187 Navi_ISLW_MapSource 4;
BA_ "GenSigStartValue" SG_ 1187 Navi_ISLW_MapSource 7;
BA_ "UserSigValidity" SG_ 1187 Navi_ISLW_MapSource 1;
BA_ "GenSigTimeoutTime" SG_ 1187 Navi_ISLW_MapSource 1500;
BA_ "Version" SG_ 1187 Navi_ISLW_MapSource "18.09.04";
BA_ "Description" SG_ 1187 Navi_ISLW_Frwinfo "18.08.09_";
BA_ "GenSigSendType" SG_ 1187 Navi_ISLW_Frwinfo 4;
BA_ "GenSigStartValue" SG_ 1187 Navi_ISLW_Frwinfo 7;
BA_ "UserSigValidity" SG_ 1187 Navi_ISLW_Frwinfo 1;
BA_ "GenSigTimeoutTime" SG_ 1187 Navi_ISLW_Frwinfo 1500;
BA_ "Version" SG_ 1187 Navi_ISLW_Frwinfo "18.09.04";
BA_ "Description" SG_ 1187 Navi_ISLW_TollExist "18.08.09_";
BA_ "GenSigSendType" SG_ 1187 Navi_ISLW_TollExist 4;
BA_ "GenSigStartValue" SG_ 1187 Navi_ISLW_TollExist 3;
BA_ "UserSigValidity" SG_ 1187 Navi_ISLW_TollExist 1;
BA_ "GenSigTimeoutTime" SG_ 1187 Navi_ISLW_TollExist 1500;
BA_ "Version" SG_ 1187 Navi_ISLW_TollExist "18.09.04";
BA_ "Description" SG_ 1187 Navi_ISLW_TunnelExist "18.08.09_";
BA_ "GenSigSendType" SG_ 1187 Navi_ISLW_TunnelExist 4;
BA_ "GenSigStartValue" SG_ 1187 Navi_ISLW_TunnelExist 3;
BA_ "UserSigValidity" SG_ 1187 Navi_ISLW_TunnelExist 1;
BA_ "GenSigTimeoutTime" SG_ 1187 Navi_ISLW_TunnelExist 1500;
BA_ "Version" SG_ 1187 Navi_ISLW_TunnelExist "18.09.04";
BA_ "Description" SG_ 1187 Navi_ISLW_TimeSpd "18.08.09_";
BA_ "GenSigSendType" SG_ 1187 Navi_ISLW_TimeSpd 4;
BA_ "GenSigStartValue" SG_ 1187 Navi_ISLW_TimeSpd 255;
BA_ "UserSigValidity" SG_ 1187 Navi_ISLW_TimeSpd 1;
BA_ "GenSigTimeoutTime" SG_ 1187 Navi_ISLW_TimeSpd 1500;
BA_ "Version" SG_ 1187 Navi_ISLW_TimeSpd "18.09.04";
BA_ "Description" SG_ 1187 Navi_ISLW_SpdUnit "18.08.09_";
BA_ "GenSigSendType" SG_ 1187 Navi_ISLW_SpdUnit 4;
BA_ "GenSigStartValue" SG_ 1187 Navi_ISLW_SpdUnit 3;
BA_ "UserSigValidity" SG_ 1187 Navi_ISLW_SpdUnit 1;
BA_ "GenSigTimeoutTime" SG_ 1187 Navi_ISLW_SpdUnit 1500;
BA_ "Version" SG_ 1187 Navi_ISLW_SpdUnit "18.09.04";
BA_ "Description" SG_ 1187 Navi_ISLW_SpdLimit "18.08.09_";
BA_ "GenSigSendType" SG_ 1187 Navi_ISLW_SpdLimit 4;
BA_ "GenSigStartValue" SG_ 1187 Navi_ISLW_SpdLimit 255;
BA_ "UserSigValidity" SG_ 1187 Navi_ISLW_SpdLimit 1;
BA_ "GenSigTimeoutTime" SG_ 1187 Navi_ISLW_SpdLimit 1500;
BA_ "Version" SG_ 1187 Navi_ISLW_SpdLimit "18.09.04";
BA_ "GenMsgCycleTime" BO_ 1192 0;
BA_ "GenMsgDelayTime" BO_ 1192 0;
BA_ "Description" SG_ 1192 CF_AVN_FCANValueSet "18.08.09_";
BA_ "GenSigSendType" SG_ 1192 CF_AVN_FCANValueSet 4;
BA_ "UserSigValidity" SG_ 1192 CF_AVN_FCANValueSet 3;
BA_ "GenSigTimeoutTime" SG_ 1192 CF_AVN_FCANValueSet 0;
BA_ "Version" SG_ 1192 CF_AVN_FCANValueSet "18.09.04";
BA_ "Description" SG_ 1192 CF_AVN_HDANValueSet "18.08.09_";
BA_ "GenSigSendType" SG_ 1192 CF_AVN_HDANValueSet 4;
BA_ "UserSigValidity" SG_ 1192 CF_AVN_HDANValueSet 3;
BA_ "GenSigTimeoutTime" SG_ 1192 CF_AVN_HDANValueSet 0;
BA_ "Version" SG_ 1192 CF_AVN_HDANValueSet "18.09.04";
BA_ "Description" SG_ 1192 CF_AVN_SEANValueSet "18.08.09_";
BA_ "GenSigSendType" SG_ 1192 CF_AVN_SEANValueSet 4;
BA_ "UserSigValidity" SG_ 1192 CF_AVN_SEANValueSet 3;
BA_ "GenSigTimeoutTime" SG_ 1192 CF_AVN_SEANValueSet 0;
BA_ "Version" SG_ 1192 CF_AVN_SEANValueSet "18.09.04";
BA_ "Description" SG_ 1192 CF_AVN_NSCCCamNValueSet "18.08.09_";
BA_ "GenSigSendType" SG_ 1192 CF_AVN_NSCCCamNValueSet 4;
BA_ "UserSigValidity" SG_ 1192 CF_AVN_NSCCCamNValueSet 3;
BA_ "GenSigTimeoutTime" SG_ 1192 CF_AVN_NSCCCamNValueSet 0;
BA_ "Version" SG_ 1192 CF_AVN_NSCCCamNValueSet "18.09.04";
BA_ "Description" SG_ 1192 CF_AVN_BCANValueSet "18.08.09_";
BA_ "GenSigSendType" SG_ 1192 CF_AVN_BCANValueSet 4;
BA_ "UserSigValidity" SG_ 1192 CF_AVN_BCANValueSet 3;
BA_ "GenSigTimeoutTime" SG_ 1192 CF_AVN_BCANValueSet 0;
BA_ "Version" SG_ 1192 CF_AVN_BCANValueSet "18.09.04";
BA_ "Description" SG_ 1192 CF_AVN_ISLWNValueSet "18.08.09_";
BA_ "GenSigSendType" SG_ 1192 CF_AVN_ISLWNValueSet 4;
BA_ "UserSigValidity" SG_ 1192 CF_AVN_ISLWNValueSet 3;
BA_ "GenSigTimeoutTime" SG_ 1192 CF_AVN_ISLWNValueSet 0;
BA_ "Version" SG_ 1192 CF_AVN_ISLWNValueSet "18.09.04";
BA_ "Description" SG_ 1192 CF_AVN_WarningTimingNValueSet "18.08.09_";
BA_ "GenSigSendType" SG_ 1192 CF_AVN_WarningTimingNValueSet 4;
BA_ "UserSigValidity" SG_ 1192 CF_AVN_WarningTimingNValueSet 3;
BA_ "GenSigTimeoutTime" SG_ 1192 CF_AVN_WarningTimingNValueSet 0;
BA_ "Version" SG_ 1192 CF_AVN_WarningTimingNValueSet "18.09.04";
BA_ "Description" SG_ 1192 CF_AVN_NSCCCrvNValueSet "18.08.09_";
BA_ "GenSigSendType" SG_ 1192 CF_AVN_NSCCCrvNValueSet 4;
BA_ "UserSigValidity" SG_ 1192 CF_AVN_NSCCCrvNValueSet 3;
BA_ "GenSigTimeoutTime" SG_ 1192 CF_AVN_NSCCCrvNValueSet 0;
BA_ "Version" SG_ 1192 CF_AVN_NSCCCrvNValueSet "18.09.04";
BA_ "Description" SG_ 1192 CF_AVN_BCWSndWanNValueSet "18.08.09_";
BA_ "GenSigSendType" SG_ 1192 CF_AVN_BCWSndWanNValueSet 4;
BA_ "UserSigValidity" SG_ 1192 CF_AVN_BCWSndWanNValueSet 3;
BA_ "GenSigTimeoutTime" SG_ 1192 CF_AVN_BCWSndWanNValueSet 0;
BA_ "Version" SG_ 1192 CF_AVN_BCWSndWanNValueSet "18.09.04";
BA_ "Description" SG_ 1192 CF_AVN_RCCWNValueSet "18.08.09_";
BA_ "GenSigSendType" SG_ 1192 CF_AVN_RCCWNValueSet 4;
BA_ "UserSigValidity" SG_ 1192 CF_AVN_RCCWNValueSet 3;
BA_ "GenSigTimeoutTime" SG_ 1192 CF_AVN_RCCWNValueSet 0;
BA_ "Version" SG_ 1192 CF_AVN_RCCWNValueSet "18.09.04";
BA_ "Description" SG_ 1192 CF_AVN_LkaModeNValueSet "18.08.09_";
BA_ "GenSigSendType" SG_ 1192 CF_AVN_LkaModeNValueSet 4;
BA_ "UserSigValidity" SG_ 1192 CF_AVN_LkaModeNValueSet 3;
BA_ "GenSigTimeoutTime" SG_ 1192 CF_AVN_LkaModeNValueSet 0;
BA_ "Version" SG_ 1192 CF_AVN_LkaModeNValueSet "18.09.04";
BA_ "Description" SG_ 1192 CF_AVN_AdasVolumeNValueSet "17.07.06_";
BA_ "GenSigSendType" SG_ 1192 CF_AVN_AdasVolumeNValueSet 4;
BA_ "UserSigValidity" SG_ 1192 CF_AVN_AdasVolumeNValueSet 3;
BA_ "GenSigTimeoutTime" SG_ 1192 CF_AVN_AdasVolumeNValueSet 0;
BA_ "Version" SG_ 1192 CF_AVN_AdasVolumeNValueSet "18.04.02";
BA_ "Description" SG_ 1192 CF_AVN_SCCDrvModeNValueSet "18.08.09_";
BA_ "GenSigSendType" SG_ 1192 CF_AVN_SCCDrvModeNValueSet 4;
BA_ "UserSigValidity" SG_ 1192 CF_AVN_SCCDrvModeNValueSet 3;
BA_ "GenSigTimeoutTime" SG_ 1192 CF_AVN_SCCDrvModeNValueSet 0;
BA_ "Version" SG_ 1192 CF_AVN_SCCDrvModeNValueSet "18.09.04";
BA_ "GenMsgCycleTime" BO_ 1195 0;
BA_ "GenMsgDelayTime" BO_ 1195 0;
BA_ "Description" SG_ 1195 CF_AVN_CluWelcomeSnd "16.06.04_";
BA_ "GenSigSendType" SG_ 1195 CF_AVN_CluWelcomeSnd 4;
BA_ "UserSigValidity" SG_ 1195 CF_AVN_CluWelcomeSnd 3;
BA_ "GenSigTimeoutTime" SG_ 1195 CF_AVN_CluWelcomeSnd 0;
BA_ "Version" SG_ 1195 CF_AVN_CluWelcomeSnd "18.04.02";
BA_ "Description" SG_ 1195 CF_AVN_CluTransmissionDisp "16.06.04_";
BA_ "GenSigSendType" SG_ 1195 CF_AVN_CluTransmissionDisp 4;
BA_ "UserSigValidity" SG_ 1195 CF_AVN_CluTransmissionDisp 3;
BA_ "GenSigTimeoutTime" SG_ 1195 CF_AVN_CluTransmissionDisp 0;
BA_ "Version" SG_ 1195 CF_AVN_CluTransmissionDisp "18.04.02";
BA_ "Description" SG_ 1195 CF_AVN_CluWiperLight "16.06.04_";
BA_ "GenSigSendType" SG_ 1195 CF_AVN_CluWiperLight 4;
BA_ "UserSigValidity" SG_ 1195 CF_AVN_CluWiperLight 3;
BA_ "GenSigTimeoutTime" SG_ 1195 CF_AVN_CluWiperLight 0;
BA_ "Version" SG_ 1195 CF_AVN_CluWiperLight "18.04.02";
BA_ "Description" SG_ 1195 CF_AVN_CluRoadInfoGuide "16.06.04_";
BA_ "GenSigSendType" SG_ 1195 CF_AVN_CluRoadInfoGuide 4;
BA_ "UserSigValidity" SG_ 1195 CF_AVN_CluRoadInfoGuide 3;
BA_ "GenSigTimeoutTime" SG_ 1195 CF_AVN_CluRoadInfoGuide 0;
BA_ "Version" SG_ 1195 CF_AVN_CluRoadInfoGuide "18.04.02";
BA_ "Description" SG_ 1195 CF_AVN_CluUserSettingPeriod "16.06.04_";
BA_ "GenSigSendType" SG_ 1195 CF_AVN_CluUserSettingPeriod 4;
BA_ "GenSigStartValue" SG_ 1195 CF_AVN_CluUserSettingPeriod 127;
BA_ "UserSigValidity" SG_ 1195 CF_AVN_CluUserSettingPeriod 3;
BA_ "GenSigTimeoutTime" SG_ 1195 CF_AVN_CluUserSettingPeriod 0;
BA_ "Version" SG_ 1195 CF_AVN_CluUserSettingPeriod "19.01.10";
BA_ "Description" SG_ 1195 CF_AVN_CluAutoInitFuelEconomy "16.06.04_";
BA_ "GenSigSendType" SG_ 1195 CF_AVN_CluAutoInitFuelEconomy 4;
BA_ "UserSigValidity" SG_ 1195 CF_AVN_CluAutoInitFuelEconomy 3;
BA_ "GenSigTimeoutTime" SG_ 1195 CF_AVN_CluAutoInitFuelEconomy 0;
BA_ "Version" SG_ 1195 CF_AVN_CluAutoInitFuelEconomy "18.04.02";
BA_ "Description" SG_ 1195 CF_AVN_CluSubspeedOdometerDisp "18.08.08_";
BA_ "GenSigSendType" SG_ 1195 CF_AVN_CluSubspeedOdometerDisp 4;
BA_ "UserSigValidity" SG_ 1195 CF_AVN_CluSubspeedOdometerDisp 3;
BA_ "GenSigTimeoutTime" SG_ 1195 CF_AVN_CluSubspeedOdometerDisp 0;
BA_ "Version" SG_ 1195 CF_AVN_CluSubspeedOdometerDisp "18.09.04";
BA_ "Description" SG_ 1195 CF_AVN_CluFuelEconUnit_mi "18.08.08_";
BA_ "GenSigSendType" SG_ 1195 CF_AVN_CluFuelEconUnit_mi 4;
BA_ "UserSigValidity" SG_ 1195 CF_AVN_CluFuelEconUnit_mi 3;
BA_ "GenSigTimeoutTime" SG_ 1195 CF_AVN_CluFuelEconUnit_mi 0;
BA_ "Version" SG_ 1195 CF_AVN_CluFuelEconUnit_mi "18.09.04";
BA_ "Description" SG_ 1195 CF_AVN_CluFuelEconUnit_km "18.08.08_";
BA_ "GenSigSendType" SG_ 1195 CF_AVN_CluFuelEconUnit_km 4;
BA_ "UserSigValidity" SG_ 1195 CF_AVN_CluFuelEconUnit_km 3;
BA_ "GenSigTimeoutTime" SG_ 1195 CF_AVN_CluFuelEconUnit_km 0;
BA_ "Version" SG_ 1195 CF_AVN_CluFuelEconUnit_km "18.09.04";
BA_ "Description" SG_ 1195 CF_AVN_CluUserSettingDistance "16.06.04_";
BA_ "GenSigSendType" SG_ 1195 CF_AVN_CluUserSettingDistance 4;
BA_ "GenSigStartValue" SG_ 1195 CF_AVN_CluUserSettingDistance 131071;
BA_ "UserSigValidity" SG_ 1195 CF_AVN_CluUserSettingDistance 3;
BA_ "GenSigTimeoutTime" SG_ 1195 CF_AVN_CluUserSettingDistance 0;
BA_ "Version" SG_ 1195 CF_AVN_CluUserSettingDistance "19.01.10";
BA_ "Description" SG_ 1195 CF_AVN_CluRheostatLvl "18.06.00_";
BA_ "GenSigSendType" SG_ 1195 CF_AVN_CluRheostatLvl 4;
BA_ "GenSigStartValue" SG_ 1195 CF_AVN_CluRheostatLvl 31;
BA_ "UserSigValidity" SG_ 1195 CF_AVN_CluRheostatLvl 3;
BA_ "GenSigTimeoutTime" SG_ 1195 CF_AVN_CluRheostatLvl 0;
BA_ "Version" SG_ 1195 CF_AVN_CluRheostatLvl "18.06.04";
BA_ "Description" SG_ 1195 CF_AVN_CluVoiceVolume "16.06.04_";
BA_ "GenSigSendType" SG_ 1195 CF_AVN_CluVoiceVolume 4;
BA_ "UserSigValidity" SG_ 1195 CF_AVN_CluVoiceVolume 3;
BA_ "GenSigTimeoutTime" SG_ 1195 CF_AVN_CluVoiceVolume 0;
BA_ "Version" SG_ 1195 CF_AVN_CluVoiceVolume "18.04.02";
BA_ "Description" SG_ 1195 CF_AVN_UnitReset "18.08.08_";
BA_ "GenSigSendType" SG_ 1195 CF_AVN_UnitReset 4;
BA_ "UserSigValidity" SG_ 1195 CF_AVN_UnitReset 3;
BA_ "GenSigTimeoutTime" SG_ 1195 CF_AVN_UnitReset 0;
BA_ "Version" SG_ 1195 CF_AVN_UnitReset "18.09.04";
BA_ "Description" SG_ 1195 CF_AVN_CluServiceReminderReset "16.11.03_";
BA_ "GenSigSendType" SG_ 1195 CF_AVN_CluServiceReminderReset 4;
BA_ "UserSigValidity" SG_ 1195 CF_AVN_CluServiceReminderReset 3;
BA_ "GenSigTimeoutTime" SG_ 1195 CF_AVN_CluServiceReminderReset 0;
BA_ "Version" SG_ 1195 CF_AVN_CluServiceReminderReset "18.04.02";
BA_ "Description" SG_ 1195 CF_AVN_CluUSMReset "18.08.08_";
BA_ "GenSigSendType" SG_ 1195 CF_AVN_CluUSMReset 4;
BA_ "UserSigValidity" SG_ 1195 CF_AVN_CluUSMReset 3;
BA_ "GenSigTimeoutTime" SG_ 1195 CF_AVN_CluUSMReset 0;
BA_ "Version" SG_ 1195 CF_AVN_CluUSMReset "18.09.04";
BA_ "Description" SG_ 1195 CF_AVN_CluServiceReminderSet "16.06.04_";
BA_ "GenSigSendType" SG_ 1195 CF_AVN_CluServiceReminderSet 4;
BA_ "UserSigValidity" SG_ 1195 CF_AVN_CluServiceReminderSet 3;
BA_ "GenSigTimeoutTime" SG_ 1195 CF_AVN_CluServiceReminderSet 0;
BA_ "Version" SG_ 1195 CF_AVN_CluServiceReminderSet "18.04.02";
BA_ "GenMsgCycleTime" BO_ 1197 0;
BA_ "GenMsgDelayTime" BO_ 1197 0;
BA_ "Description" SG_ 1197 CF_AVN_HBANValueSet "18.08.09_";
BA_ "GenSigSendType" SG_ 1197 CF_AVN_HBANValueSet 4;
BA_ "UserSigValidity" SG_ 1197 CF_AVN_HBANValueSet 3;
BA_ "GenSigTimeoutTime" SG_ 1197 CF_AVN_HBANValueSet 0;
BA_ "Version" SG_ 1197 CF_AVN_HBANValueSet "18.09.04";
BA_ "Description" SG_ 1197 CF_AVN_DAWModeNValueSet_NEW "18.08.09_";
BA_ "GenSigSendType" SG_ 1197 CF_AVN_DAWModeNValueSet_NEW 4;
BA_ "UserSigValidity" SG_ 1197 CF_AVN_DAWModeNValueSet_NEW 3;
BA_ "GenSigTimeoutTime" SG_ 1197 CF_AVN_DAWModeNValueSet_NEW 0;
BA_ "Version" SG_ 1197 CF_AVN_DAWModeNValueSet_NEW "18.09.04";
BA_ "GenMsgCycleTime" BO_ 1715 0;
BA_ "GenMsgILSupport" BO_ 1715 0;
BA_ "TpMessage" BO_ 1715 1;
BA_ "GenMsgDelayTime" BO_ 1715 0;
BA_ "Description" SG_ 1715 Byte0_TCP_4ED "17.10.01_";
BA_ "GenSigSendType" SG_ 1715 Byte0_TCP_4ED 2;
BA_ "UserSigValidity" SG_ 1715 Byte0_TCP_4ED 1;
BA_ "GenSigTimeoutTime" SG_ 1715 Byte0_TCP_4ED 0;
BA_ "Version" SG_ 1715 Byte0_TCP_4ED "18.12.06";
BA_ "Description" SG_ 1715 Byte2_Data_4ED "17.10.01_";
BA_ "GenSigSendType" SG_ 1715 Byte2_Data_4ED 2;
BA_ "UserSigValidity" SG_ 1715 Byte2_Data_4ED 1;
BA_ "GenSigTimeoutTime" SG_ 1715 Byte2_Data_4ED 0;
BA_ "Version" SG_ 1715 Byte2_Data_4ED "18.12.06";
BA_ "Description" SG_ 1715 Byte3_Data_4ED "17.10.01_";
BA_ "GenSigSendType" SG_ 1715 Byte3_Data_4ED 2;
BA_ "UserSigValidity" SG_ 1715 Byte3_Data_4ED 1;
BA_ "GenSigTimeoutTime" SG_ 1715 Byte3_Data_4ED 0;
BA_ "Version" SG_ 1715 Byte3_Data_4ED "18.12.06";
BA_ "Description" SG_ 1715 Byte4_Data_4ED "17.10.01_";
BA_ "GenSigSendType" SG_ 1715 Byte4_Data_4ED 2;
BA_ "UserSigValidity" SG_ 1715 Byte4_Data_4ED 1;
BA_ "GenSigTimeoutTime" SG_ 1715 Byte4_Data_4ED 0;
BA_ "Version" SG_ 1715 Byte4_Data_4ED "18.12.06";
BA_ "Description" SG_ 1715 Byte5_Data_4ED "17.10.01_";
BA_ "GenSigSendType" SG_ 1715 Byte5_Data_4ED 2;
BA_ "UserSigValidity" SG_ 1715 Byte5_Data_4ED 1;
BA_ "GenSigTimeoutTime" SG_ 1715 Byte5_Data_4ED 0;
BA_ "Version" SG_ 1715 Byte5_Data_4ED "18.12.06";
BA_ "Description" SG_ 1715 Byte6_Data_4ED "17.10.01_";
BA_ "GenSigSendType" SG_ 1715 Byte6_Data_4ED 2;
BA_ "UserSigValidity" SG_ 1715 Byte6_Data_4ED 1;
BA_ "GenSigTimeoutTime" SG_ 1715 Byte6_Data_4ED 0;
BA_ "Version" SG_ 1715 Byte6_Data_4ED "18.12.06";
BA_ "Description" SG_ 1715 Byte7_Data_4ED "17.10.01_";
BA_ "GenSigSendType" SG_ 1715 Byte7_Data_4ED 2;
BA_ "UserSigValidity" SG_ 1715 Byte7_Data_4ED 1;
BA_ "GenSigTimeoutTime" SG_ 1715 Byte7_Data_4ED 0;
BA_ "Version" SG_ 1715 Byte7_Data_4ED "18.12.06";
BA_ "Description" SG_ 1715 Byte1_Data_4ED "17.10.01_";
BA_ "GenSigSendType" SG_ 1715 Byte1_Data_4ED 2;
BA_ "UserSigValidity" SG_ 1715 Byte1_Data_4ED 1;
BA_ "GenSigTimeoutTime" SG_ 1715 Byte1_Data_4ED 0;
BA_ "Version" SG_ 1715 Byte1_Data_4ED "18.12.06";
BA_ "GenMsgCycleTime" BO_ 1716 0;
BA_ "GenMsgILSupport" BO_ 1716 0;
BA_ "TpMessage" BO_ 1716 1;
BA_ "GenMsgDelayTime" BO_ 1716 0;
BA_ "Description" SG_ 1716 Byte0_TCP_4F7 "15.03.01_";
BA_ "GenSigSendType" SG_ 1716 Byte0_TCP_4F7 2;
BA_ "UserSigValidity" SG_ 1716 Byte0_TCP_4F7 1;
BA_ "GenSigTimeoutTime" SG_ 1716 Byte0_TCP_4F7 0;
BA_ "Version" SG_ 1716 Byte0_TCP_4F7 "18.12.06";
BA_ "Description" SG_ 1716 Byte2_Data_4F7 "15.03.01_";
BA_ "GenSigSendType" SG_ 1716 Byte2_Data_4F7 2;
BA_ "UserSigValidity" SG_ 1716 Byte2_Data_4F7 1;
BA_ "GenSigTimeoutTime" SG_ 1716 Byte2_Data_4F7 0;
BA_ "Version" SG_ 1716 Byte2_Data_4F7 "18.12.06";
BA_ "Description" SG_ 1716 Byte3_Data_4F7 "15.03.01_";
BA_ "GenSigSendType" SG_ 1716 Byte3_Data_4F7 2;
BA_ "UserSigValidity" SG_ 1716 Byte3_Data_4F7 1;
BA_ "GenSigTimeoutTime" SG_ 1716 Byte3_Data_4F7 0;
BA_ "Version" SG_ 1716 Byte3_Data_4F7 "18.12.06";
BA_ "Description" SG_ 1716 Byte4_Data_4F7 "15.03.01_";
BA_ "GenSigSendType" SG_ 1716 Byte4_Data_4F7 2;
BA_ "UserSigValidity" SG_ 1716 Byte4_Data_4F7 1;
BA_ "GenSigTimeoutTime" SG_ 1716 Byte4_Data_4F7 0;
BA_ "Version" SG_ 1716 Byte4_Data_4F7 "18.12.06";
BA_ "Description" SG_ 1716 Byte5_Data_4F7 "15.03.01_";
BA_ "GenSigSendType" SG_ 1716 Byte5_Data_4F7 2;
BA_ "UserSigValidity" SG_ 1716 Byte5_Data_4F7 1;
BA_ "GenSigTimeoutTime" SG_ 1716 Byte5_Data_4F7 0;
BA_ "Version" SG_ 1716 Byte5_Data_4F7 "18.12.06";
BA_ "Description" SG_ 1716 Byte6_Data_4F7 "15.03.01_";
BA_ "GenSigSendType" SG_ 1716 Byte6_Data_4F7 2;
BA_ "UserSigValidity" SG_ 1716 Byte6_Data_4F7 1;
BA_ "GenSigTimeoutTime" SG_ 1716 Byte6_Data_4F7 0;
BA_ "Version" SG_ 1716 Byte6_Data_4F7 "18.12.06";
BA_ "Description" SG_ 1716 Byte7_Data_4F7 "15.03.01_";
BA_ "GenSigSendType" SG_ 1716 Byte7_Data_4F7 2;
BA_ "UserSigValidity" SG_ 1716 Byte7_Data_4F7 1;
BA_ "GenSigTimeoutTime" SG_ 1716 Byte7_Data_4F7 0;
BA_ "Version" SG_ 1716 Byte7_Data_4F7 "18.12.06";
BA_ "Description" SG_ 1716 Byte1_Data_4F7 "15.03.01_";
BA_ "GenSigSendType" SG_ 1716 Byte1_Data_4F7 2;
BA_ "UserSigValidity" SG_ 1716 Byte1_Data_4F7 1;
BA_ "GenSigTimeoutTime" SG_ 1716 Byte1_Data_4F7 0;
BA_ "Version" SG_ 1716 Byte1_Data_4F7 "18.12.06";
BA_ "GenMsgCycleTime" BO_ 1717 0;
BA_ "GenMsgILSupport" BO_ 1717 0;
BA_ "TpMessage" BO_ 1717 1;
BA_ "GenMsgDelayTime" BO_ 1717 0;
BA_ "Description" SG_ 1717 Byte0_TCP_4F1 "17.05.02_";
BA_ "GenSigSendType" SG_ 1717 Byte0_TCP_4F1 2;
BA_ "UserSigValidity" SG_ 1717 Byte0_TCP_4F1 1;
BA_ "GenSigTimeoutTime" SG_ 1717 Byte0_TCP_4F1 0;
BA_ "Version" SG_ 1717 Byte0_TCP_4F1 "18.12.06";
BA_ "Description" SG_ 1717 Byte2_Data_4F1 "17.05.02_";
BA_ "GenSigSendType" SG_ 1717 Byte2_Data_4F1 2;
BA_ "UserSigValidity" SG_ 1717 Byte2_Data_4F1 1;
BA_ "GenSigTimeoutTime" SG_ 1717 Byte2_Data_4F1 0;
BA_ "Version" SG_ 1717 Byte2_Data_4F1 "18.12.06";
BA_ "Description" SG_ 1717 Byte3_Data_4F1 "17.05.02_";
BA_ "GenSigSendType" SG_ 1717 Byte3_Data_4F1 2;
BA_ "UserSigValidity" SG_ 1717 Byte3_Data_4F1 1;
BA_ "GenSigTimeoutTime" SG_ 1717 Byte3_Data_4F1 0;
BA_ "Version" SG_ 1717 Byte3_Data_4F1 "18.12.06";
BA_ "Description" SG_ 1717 Byte4_Data_4F1 "17.05.02_";
BA_ "GenSigSendType" SG_ 1717 Byte4_Data_4F1 2;
BA_ "UserSigValidity" SG_ 1717 Byte4_Data_4F1 1;
BA_ "GenSigTimeoutTime" SG_ 1717 Byte4_Data_4F1 0;
BA_ "Version" SG_ 1717 Byte4_Data_4F1 "18.12.06";
BA_ "Description" SG_ 1717 Byte5_Data_4F1 "17.05.02_";
BA_ "GenSigSendType" SG_ 1717 Byte5_Data_4F1 2;
BA_ "UserSigValidity" SG_ 1717 Byte5_Data_4F1 1;
BA_ "GenSigTimeoutTime" SG_ 1717 Byte5_Data_4F1 0;
BA_ "Version" SG_ 1717 Byte5_Data_4F1 "18.12.06";
BA_ "Description" SG_ 1717 Byte6_Data_4F1 "17.05.02_";
BA_ "GenSigSendType" SG_ 1717 Byte6_Data_4F1 2;
BA_ "UserSigValidity" SG_ 1717 Byte6_Data_4F1 1;
BA_ "GenSigTimeoutTime" SG_ 1717 Byte6_Data_4F1 0;
BA_ "Version" SG_ 1717 Byte6_Data_4F1 "18.12.06";
BA_ "Description" SG_ 1717 Byte7_Data_4F1 "17.05.02_";
BA_ "GenSigSendType" SG_ 1717 Byte7_Data_4F1 2;
BA_ "UserSigValidity" SG_ 1717 Byte7_Data_4F1 1;
BA_ "GenSigTimeoutTime" SG_ 1717 Byte7_Data_4F1 0;
BA_ "Version" SG_ 1717 Byte7_Data_4F1 "18.12.06";
BA_ "Description" SG_ 1717 Byte1_Data_4F1 "17.05.02_";
BA_ "GenSigSendType" SG_ 1717 Byte1_Data_4F1 2;
BA_ "UserSigValidity" SG_ 1717 Byte1_Data_4F1 1;
BA_ "GenSigTimeoutTime" SG_ 1717 Byte1_Data_4F1 0;
BA_ "Version" SG_ 1717 Byte1_Data_4F1 "18.12.06";
BA_ "GenMsgCycleTime" BO_ 1718 0;
BA_ "GenMsgILSupport" BO_ 1718 0;
BA_ "TpMessage" BO_ 1718 1;
BA_ "GenMsgDelayTime" BO_ 1718 0;
BA_ "Description" SG_ 1718 Byte0_TCP_4F3 "14.09.01_";
BA_ "GenSigSendType" SG_ 1718 Byte0_TCP_4F3 2;
BA_ "UserSigValidity" SG_ 1718 Byte0_TCP_4F3 1;
BA_ "GenSigTimeoutTime" SG_ 1718 Byte0_TCP_4F3 0;
BA_ "Version" SG_ 1718 Byte0_TCP_4F3 "18.12.06";
BA_ "Description" SG_ 1718 Byte2_Data_4F3 "14.09.01_";
BA_ "GenSigSendType" SG_ 1718 Byte2_Data_4F3 2;
BA_ "UserSigValidity" SG_ 1718 Byte2_Data_4F3 1;
BA_ "GenSigTimeoutTime" SG_ 1718 Byte2_Data_4F3 0;
BA_ "Version" SG_ 1718 Byte2_Data_4F3 "18.12.06";
BA_ "Description" SG_ 1718 Byte3_Data_4F3 "14.09.01_";
BA_ "GenSigSendType" SG_ 1718 Byte3_Data_4F3 2;
BA_ "UserSigValidity" SG_ 1718 Byte3_Data_4F3 1;
BA_ "GenSigTimeoutTime" SG_ 1718 Byte3_Data_4F3 0;
BA_ "Version" SG_ 1718 Byte3_Data_4F3 "18.12.06";
BA_ "Description" SG_ 1718 Byte4_Data_4F3 "14.09.01_";
BA_ "GenSigSendType" SG_ 1718 Byte4_Data_4F3 2;
BA_ "UserSigValidity" SG_ 1718 Byte4_Data_4F3 1;
BA_ "GenSigTimeoutTime" SG_ 1718 Byte4_Data_4F3 0;
BA_ "Version" SG_ 1718 Byte4_Data_4F3 "18.12.06";
BA_ "Description" SG_ 1718 Byte5_Data_4F3 "14.09.01_";
BA_ "GenSigSendType" SG_ 1718 Byte5_Data_4F3 2;
BA_ "UserSigValidity" SG_ 1718 Byte5_Data_4F3 1;
BA_ "GenSigTimeoutTime" SG_ 1718 Byte5_Data_4F3 0;
BA_ "Version" SG_ 1718 Byte5_Data_4F3 "18.12.06";
BA_ "Description" SG_ 1718 Byte6_Data_4F3 "14.09.01_";
BA_ "GenSigSendType" SG_ 1718 Byte6_Data_4F3 2;
BA_ "UserSigValidity" SG_ 1718 Byte6_Data_4F3 1;
BA_ "GenSigTimeoutTime" SG_ 1718 Byte6_Data_4F3 0;
BA_ "Version" SG_ 1718 Byte6_Data_4F3 "18.12.06";
BA_ "Description" SG_ 1718 Byte7_Data_4F3 "14.09.01_";
BA_ "GenSigSendType" SG_ 1718 Byte7_Data_4F3 2;
BA_ "UserSigValidity" SG_ 1718 Byte7_Data_4F3 1;
BA_ "GenSigTimeoutTime" SG_ 1718 Byte7_Data_4F3 0;
BA_ "Version" SG_ 1718 Byte7_Data_4F3 "18.12.06";
BA_ "Description" SG_ 1718 Byte1_Data_4F3 "14.09.01_";
BA_ "GenSigSendType" SG_ 1718 Byte1_Data_4F3 2;
BA_ "UserSigValidity" SG_ 1718 Byte1_Data_4F3 1;
BA_ "GenSigTimeoutTime" SG_ 1718 Byte1_Data_4F3 0;
BA_ "Version" SG_ 1718 Byte1_Data_4F3 "18.12.06";
BA_ "GenMsgCycleTime" BO_ 1723 0;
BA_ "GenMsgILSupport" BO_ 1723 0;
BA_ "TpMessage" BO_ 1723 1;
BA_ "GenMsgDelayTime" BO_ 1723 0;
BA_ "Description" SG_ 1723 Byte0_TCP_4E9 "1.08.00_";
BA_ "GenSigSendType" SG_ 1723 Byte0_TCP_4E9 2;
BA_ "UserSigValidity" SG_ 1723 Byte0_TCP_4E9 1;
BA_ "GenSigTimeoutTime" SG_ 1723 Byte0_TCP_4E9 0;
BA_ "Version" SG_ 1723 Byte0_TCP_4E9 "18.12.06";
BA_ "Description" SG_ 1723 Byte2_Data_4E9 "1.08.00_";
BA_ "GenSigSendType" SG_ 1723 Byte2_Data_4E9 2;
BA_ "UserSigValidity" SG_ 1723 Byte2_Data_4E9 1;
BA_ "GenSigTimeoutTime" SG_ 1723 Byte2_Data_4E9 0;
BA_ "Version" SG_ 1723 Byte2_Data_4E9 "18.12.06";
BA_ "Description" SG_ 1723 Byte3_Data_4E9 "1.08.00_";
BA_ "GenSigSendType" SG_ 1723 Byte3_Data_4E9 2;
BA_ "UserSigValidity" SG_ 1723 Byte3_Data_4E9 1;
BA_ "GenSigTimeoutTime" SG_ 1723 Byte3_Data_4E9 0;
BA_ "Version" SG_ 1723 Byte3_Data_4E9 "18.12.06";
BA_ "Description" SG_ 1723 Byte4_Data_4E9 "1.08.00_";
BA_ "GenSigSendType" SG_ 1723 Byte4_Data_4E9 2;
BA_ "UserSigValidity" SG_ 1723 Byte4_Data_4E9 1;
BA_ "GenSigTimeoutTime" SG_ 1723 Byte4_Data_4E9 0;
BA_ "Version" SG_ 1723 Byte4_Data_4E9 "18.12.06";
BA_ "Description" SG_ 1723 Byte5_Data_4E9 "1.08.00_";
BA_ "GenSigSendType" SG_ 1723 Byte5_Data_4E9 2;
BA_ "UserSigValidity" SG_ 1723 Byte5_Data_4E9 1;
BA_ "GenSigTimeoutTime" SG_ 1723 Byte5_Data_4E9 0;
BA_ "Version" SG_ 1723 Byte5_Data_4E9 "18.12.06";
BA_ "Description" SG_ 1723 Byte6_Data_4E9 "1.08.00_";
BA_ "GenSigSendType" SG_ 1723 Byte6_Data_4E9 2;
BA_ "UserSigValidity" SG_ 1723 Byte6_Data_4E9 1;
BA_ "GenSigTimeoutTime" SG_ 1723 Byte6_Data_4E9 0;
BA_ "Version" SG_ 1723 Byte6_Data_4E9 "18.12.06";
BA_ "Description" SG_ 1723 Byte7_Data_4E9 "1.08.00_";
BA_ "GenSigSendType" SG_ 1723 Byte7_Data_4E9 2;
BA_ "UserSigValidity" SG_ 1723 Byte7_Data_4E9 1;
BA_ "GenSigTimeoutTime" SG_ 1723 Byte7_Data_4E9 0;
BA_ "Version" SG_ 1723 Byte7_Data_4E9 "18.12.06";
BA_ "Description" SG_ 1723 Byte1_Data_4E9 "1.08.00_";
BA_ "GenSigSendType" SG_ 1723 Byte1_Data_4E9 2;
BA_ "UserSigValidity" SG_ 1723 Byte1_Data_4E9 1;
BA_ "GenSigTimeoutTime" SG_ 1723 Byte1_Data_4E9 0;
BA_ "Version" SG_ 1723 Byte1_Data_4E9 "18.12.06";
BA_ "GenMsgCycleTime" BO_ 1724 0;
BA_ "GenMsgILSupport" BO_ 1724 0;
BA_ "TpMessage" BO_ 1724 1;
BA_ "GenMsgDelayTime" BO_ 1724 0;
BA_ "Description" SG_ 1724 Byte0_TCP_4F9 "15.03.01_";
BA_ "GenSigSendType" SG_ 1724 Byte0_TCP_4F9 2;
BA_ "UserSigValidity" SG_ 1724 Byte0_TCP_4F9 1;
BA_ "GenSigTimeoutTime" SG_ 1724 Byte0_TCP_4F9 0;
BA_ "Version" SG_ 1724 Byte0_TCP_4F9 "18.12.06";
BA_ "Description" SG_ 1724 Byte2_Data_4F9 "15.03.01_";
BA_ "GenSigSendType" SG_ 1724 Byte2_Data_4F9 2;
BA_ "UserSigValidity" SG_ 1724 Byte2_Data_4F9 1;
BA_ "GenSigTimeoutTime" SG_ 1724 Byte2_Data_4F9 0;
BA_ "Version" SG_ 1724 Byte2_Data_4F9 "18.12.06";
BA_ "Description" SG_ 1724 Byte3_Data_4F9 "15.03.01_";
BA_ "GenSigSendType" SG_ 1724 Byte3_Data_4F9 2;
BA_ "UserSigValidity" SG_ 1724 Byte3_Data_4F9 1;
BA_ "GenSigTimeoutTime" SG_ 1724 Byte3_Data_4F9 0;
BA_ "Version" SG_ 1724 Byte3_Data_4F9 "18.12.06";
BA_ "Description" SG_ 1724 Byte4_Data_4F9 "15.03.01_";
BA_ "GenSigSendType" SG_ 1724 Byte4_Data_4F9 2;
BA_ "UserSigValidity" SG_ 1724 Byte4_Data_4F9 1;
BA_ "GenSigTimeoutTime" SG_ 1724 Byte4_Data_4F9 0;
BA_ "Version" SG_ 1724 Byte4_Data_4F9 "18.12.06";
BA_ "Description" SG_ 1724 Byte5_Data_4F9 "15.03.01_";
BA_ "GenSigSendType" SG_ 1724 Byte5_Data_4F9 2;
BA_ "UserSigValidity" SG_ 1724 Byte5_Data_4F9 1;
BA_ "GenSigTimeoutTime" SG_ 1724 Byte5_Data_4F9 0;
BA_ "Version" SG_ 1724 Byte5_Data_4F9 "18.12.06";
BA_ "Description" SG_ 1724 Byte6_Data_4F9 "15.03.01_";
BA_ "GenSigSendType" SG_ 1724 Byte6_Data_4F9 2;
BA_ "UserSigValidity" SG_ 1724 Byte6_Data_4F9 1;
BA_ "GenSigTimeoutTime" SG_ 1724 Byte6_Data_4F9 0;
BA_ "Version" SG_ 1724 Byte6_Data_4F9 "18.12.06";
BA_ "Description" SG_ 1724 Byte7_Data_4F9 "15.03.01_";
BA_ "GenSigSendType" SG_ 1724 Byte7_Data_4F9 2;
BA_ "UserSigValidity" SG_ 1724 Byte7_Data_4F9 1;
BA_ "GenSigTimeoutTime" SG_ 1724 Byte7_Data_4F9 0;
BA_ "Version" SG_ 1724 Byte7_Data_4F9 "18.12.06";
BA_ "Description" SG_ 1724 Byte1_Data_4F9 "15.03.01_";
BA_ "GenSigSendType" SG_ 1724 Byte1_Data_4F9 2;
BA_ "UserSigValidity" SG_ 1724 Byte1_Data_4F9 1;
BA_ "GenSigTimeoutTime" SG_ 1724 Byte1_Data_4F9 0;
BA_ "Version" SG_ 1724 Byte1_Data_4F9 "18.12.06";
BA_ "GenMsgCycleTime" BO_ 1725 0;
BA_ "GenMsgILSupport" BO_ 1725 0;
BA_ "TpMessage" BO_ 1725 1;
BA_ "GenMsgDelayTime" BO_ 1725 0;
BA_ "Description" SG_ 1725 Byte0_TCP_484 "15.03.01_";
BA_ "GenSigSendType" SG_ 1725 Byte0_TCP_484 2;
BA_ "UserSigValidity" SG_ 1725 Byte0_TCP_484 1;
BA_ "GenSigTimeoutTime" SG_ 1725 Byte0_TCP_484 0;
BA_ "Version" SG_ 1725 Byte0_TCP_484 "18.12.06";
BA_ "Description" SG_ 1725 Byte2_Data_484 "15.03.01_";
BA_ "GenSigSendType" SG_ 1725 Byte2_Data_484 2;
BA_ "UserSigValidity" SG_ 1725 Byte2_Data_484 1;
BA_ "GenSigTimeoutTime" SG_ 1725 Byte2_Data_484 0;
BA_ "Version" SG_ 1725 Byte2_Data_484 "18.12.06";
BA_ "Description" SG_ 1725 Byte3_Data_484 "15.03.01_";
BA_ "GenSigSendType" SG_ 1725 Byte3_Data_484 2;
BA_ "UserSigValidity" SG_ 1725 Byte3_Data_484 1;
BA_ "GenSigTimeoutTime" SG_ 1725 Byte3_Data_484 0;
BA_ "Version" SG_ 1725 Byte3_Data_484 "18.12.06";
BA_ "Description" SG_ 1725 Byte4_Data_484 "15.03.01_";
BA_ "GenSigSendType" SG_ 1725 Byte4_Data_484 2;
BA_ "UserSigValidity" SG_ 1725 Byte4_Data_484 1;
BA_ "GenSigTimeoutTime" SG_ 1725 Byte4_Data_484 0;
BA_ "Version" SG_ 1725 Byte4_Data_484 "18.12.06";
BA_ "Description" SG_ 1725 Byte5_Data_484 "15.03.01_";
BA_ "GenSigSendType" SG_ 1725 Byte5_Data_484 2;
BA_ "UserSigValidity" SG_ 1725 Byte5_Data_484 1;
BA_ "GenSigTimeoutTime" SG_ 1725 Byte5_Data_484 0;
BA_ "Version" SG_ 1725 Byte5_Data_484 "18.12.06";
BA_ "Description" SG_ 1725 Byte6_Data_484 "15.03.01_";
BA_ "GenSigSendType" SG_ 1725 Byte6_Data_484 2;
BA_ "UserSigValidity" SG_ 1725 Byte6_Data_484 1;
BA_ "GenSigTimeoutTime" SG_ 1725 Byte6_Data_484 0;
BA_ "Version" SG_ 1725 Byte6_Data_484 "18.12.06";
BA_ "Description" SG_ 1725 Byte7_Data_484 "15.03.01_";
BA_ "GenSigSendType" SG_ 1725 Byte7_Data_484 2;
BA_ "UserSigValidity" SG_ 1725 Byte7_Data_484 1;
BA_ "GenSigTimeoutTime" SG_ 1725 Byte7_Data_484 0;
BA_ "Version" SG_ 1725 Byte7_Data_484 "18.12.06";
BA_ "Description" SG_ 1725 Byte1_Data_484 "15.03.01_";
BA_ "GenSigSendType" SG_ 1725 Byte1_Data_484 2;
BA_ "UserSigValidity" SG_ 1725 Byte1_Data_484 1;
BA_ "GenSigTimeoutTime" SG_ 1725 Byte1_Data_484 0;
BA_ "Version" SG_ 1725 Byte1_Data_484 "18.12.06";
BA_ "GenMsgCycleTime" BO_ 1726 0;
BA_ "GenMsgILSupport" BO_ 1726 0;
BA_ "TpMessage" BO_ 1726 1;
BA_ "GenMsgDelayTime" BO_ 1726 0;
BA_ "Description" SG_ 1726 Byte0_TCP_4EF "1.08.00_";
BA_ "GenSigSendType" SG_ 1726 Byte0_TCP_4EF 2;
BA_ "UserSigValidity" SG_ 1726 Byte0_TCP_4EF 1;
BA_ "GenSigTimeoutTime" SG_ 1726 Byte0_TCP_4EF 0;
BA_ "Version" SG_ 1726 Byte0_TCP_4EF "18.12.06";
BA_ "Description" SG_ 1726 Byte2_Data_4EF "1.08.00_";
BA_ "GenSigSendType" SG_ 1726 Byte2_Data_4EF 2;
BA_ "UserSigValidity" SG_ 1726 Byte2_Data_4EF 1;
BA_ "GenSigTimeoutTime" SG_ 1726 Byte2_Data_4EF 0;
BA_ "Version" SG_ 1726 Byte2_Data_4EF "18.12.06";
BA_ "Description" SG_ 1726 Byte3_Data_4EF "1.08.00_";
BA_ "GenSigSendType" SG_ 1726 Byte3_Data_4EF 2;
BA_ "UserSigValidity" SG_ 1726 Byte3_Data_4EF 1;
BA_ "GenSigTimeoutTime" SG_ 1726 Byte3_Data_4EF 0;
BA_ "Version" SG_ 1726 Byte3_Data_4EF "18.12.06";
BA_ "Description" SG_ 1726 Byte4_Data_4EF "1.08.00_";
BA_ "GenSigSendType" SG_ 1726 Byte4_Data_4EF 2;
BA_ "UserSigValidity" SG_ 1726 Byte4_Data_4EF 1;
BA_ "GenSigTimeoutTime" SG_ 1726 Byte4_Data_4EF 0;
BA_ "Version" SG_ 1726 Byte4_Data_4EF "18.12.06";
BA_ "Description" SG_ 1726 Byte5_Data_4EF "1.08.00_";
BA_ "GenSigSendType" SG_ 1726 Byte5_Data_4EF 2;
BA_ "UserSigValidity" SG_ 1726 Byte5_Data_4EF 1;
BA_ "GenSigTimeoutTime" SG_ 1726 Byte5_Data_4EF 0;
BA_ "Version" SG_ 1726 Byte5_Data_4EF "18.12.06";
BA_ "Description" SG_ 1726 Byte6_Data_4EF "1.08.00_";
BA_ "GenSigSendType" SG_ 1726 Byte6_Data_4EF 2;
BA_ "UserSigValidity" SG_ 1726 Byte6_Data_4EF 1;
BA_ "GenSigTimeoutTime" SG_ 1726 Byte6_Data_4EF 0;
BA_ "Version" SG_ 1726 Byte6_Data_4EF "18.12.06";
BA_ "Description" SG_ 1726 Byte7_Data_4EF "1.08.00_";
BA_ "GenSigSendType" SG_ 1726 Byte7_Data_4EF 2;
BA_ "UserSigValidity" SG_ 1726 Byte7_Data_4EF 1;
BA_ "GenSigTimeoutTime" SG_ 1726 Byte7_Data_4EF 0;
BA_ "Version" SG_ 1726 Byte7_Data_4EF "18.12.06";
BA_ "Description" SG_ 1726 Byte1_Data_4EF "1.08.00_";
BA_ "GenSigSendType" SG_ 1726 Byte1_Data_4EF 2;
BA_ "UserSigValidity" SG_ 1726 Byte1_Data_4EF 1;
BA_ "GenSigTimeoutTime" SG_ 1726 Byte1_Data_4EF 0;
BA_ "Version" SG_ 1726 Byte1_Data_4EF "18.12.06";
BA_ "GenMsgCycleTime" BO_ 1727 0;
BA_ "GenMsgILSupport" BO_ 1727 0;
BA_ "TpMessage" BO_ 1727 1;
BA_ "GenMsgDelayTime" BO_ 1727 0;
BA_ "Description" SG_ 1727 Byte0_TCP_49A "13.08.01_";
BA_ "GenSigSendType" SG_ 1727 Byte0_TCP_49A 2;
BA_ "UserSigValidity" SG_ 1727 Byte0_TCP_49A 1;
BA_ "GenSigTimeoutTime" SG_ 1727 Byte0_TCP_49A 0;
BA_ "Version" SG_ 1727 Byte0_TCP_49A "18.12.06";
BA_ "Description" SG_ 1727 Byte2_Data_49A "13.08.01_";
BA_ "GenSigSendType" SG_ 1727 Byte2_Data_49A 2;
BA_ "UserSigValidity" SG_ 1727 Byte2_Data_49A 1;
BA_ "GenSigTimeoutTime" SG_ 1727 Byte2_Data_49A 0;
BA_ "Version" SG_ 1727 Byte2_Data_49A "18.12.06";
BA_ "Description" SG_ 1727 Byte3_Data_49A "13.08.01_";
BA_ "GenSigSendType" SG_ 1727 Byte3_Data_49A 2;
BA_ "UserSigValidity" SG_ 1727 Byte3_Data_49A 1;
BA_ "GenSigTimeoutTime" SG_ 1727 Byte3_Data_49A 0;
BA_ "Version" SG_ 1727 Byte3_Data_49A "18.12.06";
BA_ "Description" SG_ 1727 Byte4_Data_49A "13.08.01_";
BA_ "GenSigSendType" SG_ 1727 Byte4_Data_49A 2;
BA_ "UserSigValidity" SG_ 1727 Byte4_Data_49A 1;
BA_ "GenSigTimeoutTime" SG_ 1727 Byte4_Data_49A 0;
BA_ "Version" SG_ 1727 Byte4_Data_49A "18.12.06";
BA_ "Description" SG_ 1727 Byte5_Data_49A "13.08.01_";
BA_ "GenSigSendType" SG_ 1727 Byte5_Data_49A 2;
BA_ "UserSigValidity" SG_ 1727 Byte5_Data_49A 1;
BA_ "GenSigTimeoutTime" SG_ 1727 Byte5_Data_49A 0;
BA_ "Version" SG_ 1727 Byte5_Data_49A "18.12.06";
BA_ "Description" SG_ 1727 Byte6_Data_49A "13.08.01_";
BA_ "GenSigSendType" SG_ 1727 Byte6_Data_49A 2;
BA_ "UserSigValidity" SG_ 1727 Byte6_Data_49A 1;
BA_ "GenSigTimeoutTime" SG_ 1727 Byte6_Data_49A 0;
BA_ "Version" SG_ 1727 Byte6_Data_49A "18.12.06";
BA_ "Description" SG_ 1727 Byte7_Data_49A "13.08.01_";
BA_ "GenSigSendType" SG_ 1727 Byte7_Data_49A 2;
BA_ "UserSigValidity" SG_ 1727 Byte7_Data_49A 1;
BA_ "GenSigTimeoutTime" SG_ 1727 Byte7_Data_49A 0;
BA_ "Version" SG_ 1727 Byte7_Data_49A "18.12.06";
BA_ "Description" SG_ 1727 Byte1_Data_49A "13.08.01_";
BA_ "GenSigSendType" SG_ 1727 Byte1_Data_49A 2;
BA_ "UserSigValidity" SG_ 1727 Byte1_Data_49A 1;
BA_ "GenSigTimeoutTime" SG_ 1727 Byte1_Data_49A 0;
BA_ "Version" SG_ 1727 Byte1_Data_49A "18.12.06";
BA_ "GenMsgCycleTime" BO_ 1730 0;
BA_ "GenMsgILSupport" BO_ 1730 0;
BA_ "TpMessage" BO_ 1730 1;
BA_ "GenMsgDelayTime" BO_ 1730 0;
BA_ "Description" SG_ 1730 Byte0_TCP_4E7 "18.06.00_";
BA_ "GenSigSendType" SG_ 1730 Byte0_TCP_4E7 2;
BA_ "UserSigValidity" SG_ 1730 Byte0_TCP_4E7 1;
BA_ "GenSigTimeoutTime" SG_ 1730 Byte0_TCP_4E7 0;
BA_ "Version" SG_ 1730 Byte0_TCP_4E7 "18.12.06";
BA_ "Description" SG_ 1730 Byte2_Data_4E7 "18.06.00_";
BA_ "GenSigSendType" SG_ 1730 Byte2_Data_4E7 2;
BA_ "UserSigValidity" SG_ 1730 Byte2_Data_4E7 1;
BA_ "GenSigTimeoutTime" SG_ 1730 Byte2_Data_4E7 0;
BA_ "Version" SG_ 1730 Byte2_Data_4E7 "18.12.06";
BA_ "Description" SG_ 1730 Byte3_Data_4E7 "18.06.00_";
BA_ "GenSigSendType" SG_ 1730 Byte3_Data_4E7 2;
BA_ "UserSigValidity" SG_ 1730 Byte3_Data_4E7 1;
BA_ "GenSigTimeoutTime" SG_ 1730 Byte3_Data_4E7 0;
BA_ "Version" SG_ 1730 Byte3_Data_4E7 "18.12.06";
BA_ "Description" SG_ 1730 Byte4_Data_4E7 "18.06.00_";
BA_ "GenSigSendType" SG_ 1730 Byte4_Data_4E7 2;
BA_ "UserSigValidity" SG_ 1730 Byte4_Data_4E7 1;
BA_ "GenSigTimeoutTime" SG_ 1730 Byte4_Data_4E7 0;
BA_ "Version" SG_ 1730 Byte4_Data_4E7 "18.12.06";
BA_ "Description" SG_ 1730 Byte5_Data_4E7 "18.06.00_";
BA_ "GenSigSendType" SG_ 1730 Byte5_Data_4E7 2;
BA_ "UserSigValidity" SG_ 1730 Byte5_Data_4E7 1;
BA_ "GenSigTimeoutTime" SG_ 1730 Byte5_Data_4E7 0;
BA_ "Version" SG_ 1730 Byte5_Data_4E7 "18.12.06";
BA_ "Description" SG_ 1730 Byte6_Data_4E7 "18.06.00_";
BA_ "GenSigSendType" SG_ 1730 Byte6_Data_4E7 2;
BA_ "UserSigValidity" SG_ 1730 Byte6_Data_4E7 1;
BA_ "GenSigTimeoutTime" SG_ 1730 Byte6_Data_4E7 0;
BA_ "Version" SG_ 1730 Byte6_Data_4E7 "18.12.06";
BA_ "Description" SG_ 1730 Byte7_Data_4E7 "18.06.00_";
BA_ "GenSigSendType" SG_ 1730 Byte7_Data_4E7 2;
BA_ "UserSigValidity" SG_ 1730 Byte7_Data_4E7 1;
BA_ "GenSigTimeoutTime" SG_ 1730 Byte7_Data_4E7 0;
BA_ "Version" SG_ 1730 Byte7_Data_4E7 "18.12.06";
BA_ "Description" SG_ 1730 Byte1_Data_4E7 "18.06.00_";
BA_ "GenSigSendType" SG_ 1730 Byte1_Data_4E7 2;
BA_ "UserSigValidity" SG_ 1730 Byte1_Data_4E7 1;
BA_ "GenSigTimeoutTime" SG_ 1730 Byte1_Data_4E7 0;
BA_ "Version" SG_ 1730 Byte1_Data_4E7 "18.12.06";
BA_ "GenMsgCycleTime" BO_ 1733 0;
BA_ "GenMsgILSupport" BO_ 1733 0;
BA_ "TpMessage" BO_ 1733 1;
BA_ "GenMsgDelayTime" BO_ 1733 0;
BA_ "Description" SG_ 1733 Byte0_TCP_48C "1.08.00_";
BA_ "GenSigSendType" SG_ 1733 Byte0_TCP_48C 2;
BA_ "UserSigValidity" SG_ 1733 Byte0_TCP_48C 1;
BA_ "GenSigTimeoutTime" SG_ 1733 Byte0_TCP_48C 0;
BA_ "Version" SG_ 1733 Byte0_TCP_48C "18.12.06";
BA_ "Description" SG_ 1733 Byte2_Data_48C "1.08.00_";
BA_ "GenSigSendType" SG_ 1733 Byte2_Data_48C 2;
BA_ "UserSigValidity" SG_ 1733 Byte2_Data_48C 1;
BA_ "GenSigTimeoutTime" SG_ 1733 Byte2_Data_48C 0;
BA_ "Version" SG_ 1733 Byte2_Data_48C "18.12.06";
BA_ "Description" SG_ 1733 Byte3_Data_48C "1.08.00_";
BA_ "GenSigSendType" SG_ 1733 Byte3_Data_48C 2;
BA_ "UserSigValidity" SG_ 1733 Byte3_Data_48C 1;
BA_ "GenSigTimeoutTime" SG_ 1733 Byte3_Data_48C 0;
BA_ "Version" SG_ 1733 Byte3_Data_48C "18.12.06";
BA_ "Description" SG_ 1733 Byte4_Data_48C "1.08.00_";
BA_ "GenSigSendType" SG_ 1733 Byte4_Data_48C 2;
BA_ "UserSigValidity" SG_ 1733 Byte4_Data_48C 1;
BA_ "GenSigTimeoutTime" SG_ 1733 Byte4_Data_48C 0;
BA_ "Version" SG_ 1733 Byte4_Data_48C "18.12.06";
BA_ "Description" SG_ 1733 Byte5_Data_48C "1.08.00_";
BA_ "GenSigSendType" SG_ 1733 Byte5_Data_48C 2;
BA_ "UserSigValidity" SG_ 1733 Byte5_Data_48C 1;
BA_ "GenSigTimeoutTime" SG_ 1733 Byte5_Data_48C 0;
BA_ "Version" SG_ 1733 Byte5_Data_48C "18.12.06";
BA_ "Description" SG_ 1733 Byte6_Data_48C "1.08.00_";
BA_ "GenSigSendType" SG_ 1733 Byte6_Data_48C 2;
BA_ "UserSigValidity" SG_ 1733 Byte6_Data_48C 1;
BA_ "GenSigTimeoutTime" SG_ 1733 Byte6_Data_48C 0;
BA_ "Version" SG_ 1733 Byte6_Data_48C "18.12.06";
BA_ "Description" SG_ 1733 Byte7_Data_48C "1.08.00_";
BA_ "GenSigSendType" SG_ 1733 Byte7_Data_48C 2;
BA_ "UserSigValidity" SG_ 1733 Byte7_Data_48C 1;
BA_ "GenSigTimeoutTime" SG_ 1733 Byte7_Data_48C 0;
BA_ "Version" SG_ 1733 Byte7_Data_48C "18.12.06";
BA_ "Description" SG_ 1733 Byte1_Data_48C "1.08.00_";
BA_ "GenSigSendType" SG_ 1733 Byte1_Data_48C 2;
BA_ "UserSigValidity" SG_ 1733 Byte1_Data_48C 1;
BA_ "GenSigTimeoutTime" SG_ 1733 Byte1_Data_48C 0;
BA_ "Version" SG_ 1733 Byte1_Data_48C "18.12.06";
BA_ "GenMsgCycleTime" BO_ 1734 0;
BA_ "GenMsgILSupport" BO_ 1734 0;
BA_ "TpMessage" BO_ 1734 1;
BA_ "GenMsgDelayTime" BO_ 1734 0;
BA_ "Description" SG_ 1734 Byte0_TCP_4E5 "18.02.05_";
BA_ "GenSigSendType" SG_ 1734 Byte0_TCP_4E5 2;
BA_ "UserSigValidity" SG_ 1734 Byte0_TCP_4E5 1;
BA_ "GenSigTimeoutTime" SG_ 1734 Byte0_TCP_4E5 0;
BA_ "Version" SG_ 1734 Byte0_TCP_4E5 "18.12.06";
BA_ "Description" SG_ 1734 Byte2_Data_4E5 "18.02.05_";
BA_ "GenSigSendType" SG_ 1734 Byte2_Data_4E5 2;
BA_ "UserSigValidity" SG_ 1734 Byte2_Data_4E5 1;
BA_ "GenSigTimeoutTime" SG_ 1734 Byte2_Data_4E5 0;
BA_ "Version" SG_ 1734 Byte2_Data_4E5 "18.12.06";
BA_ "Description" SG_ 1734 Byte3_Data_4E5 "18.02.05_";
BA_ "GenSigSendType" SG_ 1734 Byte3_Data_4E5 2;
BA_ "UserSigValidity" SG_ 1734 Byte3_Data_4E5 1;
BA_ "GenSigTimeoutTime" SG_ 1734 Byte3_Data_4E5 0;
BA_ "Version" SG_ 1734 Byte3_Data_4E5 "18.12.06";
BA_ "Description" SG_ 1734 Byte4_Data_4E5 "18.02.05_";
BA_ "GenSigSendType" SG_ 1734 Byte4_Data_4E5 2;
BA_ "UserSigValidity" SG_ 1734 Byte4_Data_4E5 1;
BA_ "GenSigTimeoutTime" SG_ 1734 Byte4_Data_4E5 0;
BA_ "Version" SG_ 1734 Byte4_Data_4E5 "18.12.06";
BA_ "Description" SG_ 1734 Byte5_Data_4E5 "18.02.05_";
BA_ "GenSigSendType" SG_ 1734 Byte5_Data_4E5 2;
BA_ "UserSigValidity" SG_ 1734 Byte5_Data_4E5 1;
BA_ "GenSigTimeoutTime" SG_ 1734 Byte5_Data_4E5 0;
BA_ "Version" SG_ 1734 Byte5_Data_4E5 "18.12.06";
BA_ "Description" SG_ 1734 Byte6_Data_4E5 "18.02.05_";
BA_ "GenSigSendType" SG_ 1734 Byte6_Data_4E5 2;
BA_ "UserSigValidity" SG_ 1734 Byte6_Data_4E5 1;
BA_ "GenSigTimeoutTime" SG_ 1734 Byte6_Data_4E5 0;
BA_ "Version" SG_ 1734 Byte6_Data_4E5 "18.12.06";
BA_ "Description" SG_ 1734 Byte7_Data_4E5 "18.02.05_";
BA_ "GenSigSendType" SG_ 1734 Byte7_Data_4E5 2;
BA_ "UserSigValidity" SG_ 1734 Byte7_Data_4E5 1;
BA_ "GenSigTimeoutTime" SG_ 1734 Byte7_Data_4E5 0;
BA_ "Version" SG_ 1734 Byte7_Data_4E5 "18.12.06";
BA_ "Description" SG_ 1734 Byte1_Data_4E5 "18.02.05_";
BA_ "GenSigSendType" SG_ 1734 Byte1_Data_4E5 2;
BA_ "UserSigValidity" SG_ 1734 Byte1_Data_4E5 1;
BA_ "GenSigTimeoutTime" SG_ 1734 Byte1_Data_4E5 0;
BA_ "Version" SG_ 1734 Byte1_Data_4E5 "18.12.06";
BA_ "GenMsgCycleTime" BO_ 1736 0;
BA_ "GenMsgILSupport" BO_ 1736 0;
BA_ "TpMessage" BO_ 1736 1;
BA_ "GenMsgDelayTime" BO_ 1736 0;
BA_ "Description" SG_ 1736 Byte0_TCP_497 "13.08.01_";
BA_ "GenSigSendType" SG_ 1736 Byte0_TCP_497 2;
BA_ "UserSigValidity" SG_ 1736 Byte0_TCP_497 1;
BA_ "GenSigTimeoutTime" SG_ 1736 Byte0_TCP_497 0;
BA_ "Version" SG_ 1736 Byte0_TCP_497 "18.12.06";
BA_ "Description" SG_ 1736 Byte2_Data_497 "13.08.01_";
BA_ "GenSigSendType" SG_ 1736 Byte2_Data_497 2;
BA_ "UserSigValidity" SG_ 1736 Byte2_Data_497 1;
BA_ "GenSigTimeoutTime" SG_ 1736 Byte2_Data_497 0;
BA_ "Version" SG_ 1736 Byte2_Data_497 "18.12.06";
BA_ "Description" SG_ 1736 Byte3_Data_497 "13.08.01_";
BA_ "GenSigSendType" SG_ 1736 Byte3_Data_497 2;
BA_ "UserSigValidity" SG_ 1736 Byte3_Data_497 1;
BA_ "GenSigTimeoutTime" SG_ 1736 Byte3_Data_497 0;
BA_ "Version" SG_ 1736 Byte3_Data_497 "18.12.06";
BA_ "Description" SG_ 1736 Byte4_Data_497 "13.08.01_";
BA_ "GenSigSendType" SG_ 1736 Byte4_Data_497 2;
BA_ "UserSigValidity" SG_ 1736 Byte4_Data_497 1;
BA_ "GenSigTimeoutTime" SG_ 1736 Byte4_Data_497 0;
BA_ "Version" SG_ 1736 Byte4_Data_497 "18.12.06";
BA_ "Description" SG_ 1736 Byte5_Data_497 "13.08.01_";
BA_ "GenSigSendType" SG_ 1736 Byte5_Data_497 2;
BA_ "UserSigValidity" SG_ 1736 Byte5_Data_497 1;
BA_ "GenSigTimeoutTime" SG_ 1736 Byte5_Data_497 0;
BA_ "Version" SG_ 1736 Byte5_Data_497 "18.12.06";
BA_ "Description" SG_ 1736 Byte6_Data_497 "13.08.01_";
BA_ "GenSigSendType" SG_ 1736 Byte6_Data_497 2;
BA_ "UserSigValidity" SG_ 1736 Byte6_Data_497 1;
BA_ "GenSigTimeoutTime" SG_ 1736 Byte6_Data_497 0;
BA_ "Version" SG_ 1736 Byte6_Data_497 "18.12.06";
BA_ "Description" SG_ 1736 Byte7_Data_497 "13.08.01_";
BA_ "GenSigSendType" SG_ 1736 Byte7_Data_497 2;
BA_ "UserSigValidity" SG_ 1736 Byte7_Data_497 1;
BA_ "GenSigTimeoutTime" SG_ 1736 Byte7_Data_497 0;
BA_ "Version" SG_ 1736 Byte7_Data_497 "18.12.06";
BA_ "Description" SG_ 1736 Byte1_Data_497 "13.08.01_";
BA_ "GenSigSendType" SG_ 1736 Byte1_Data_497 2;
BA_ "UserSigValidity" SG_ 1736 Byte1_Data_497 1;
BA_ "GenSigTimeoutTime" SG_ 1736 Byte1_Data_497 0;
BA_ "Version" SG_ 1736 Byte1_Data_497 "18.12.06";
BA_ "GenMsgCycleTime" BO_ 1747 0;
BA_ "GenMsgILSupport" BO_ 1747 0;
BA_ "TpMessage" BO_ 1747 1;
BA_ "GenMsgDelayTime" BO_ 1747 0;
BA_ "Description" SG_ 1747 Byte0_TCP_4EC "17.10.01_";
BA_ "GenSigSendType" SG_ 1747 Byte0_TCP_4EC 2;
BA_ "UserSigValidity" SG_ 1747 Byte0_TCP_4EC 1;
BA_ "GenSigTimeoutTime" SG_ 1747 Byte0_TCP_4EC 0;
BA_ "Version" SG_ 1747 Byte0_TCP_4EC "18.12.06";
BA_ "Description" SG_ 1747 Byte2_Data_4EC "17.10.01_";
BA_ "GenSigSendType" SG_ 1747 Byte2_Data_4EC 2;
BA_ "UserSigValidity" SG_ 1747 Byte2_Data_4EC 1;
BA_ "GenSigTimeoutTime" SG_ 1747 Byte2_Data_4EC 0;
BA_ "Version" SG_ 1747 Byte2_Data_4EC "18.12.06";
BA_ "Description" SG_ 1747 Byte3_Data_4EC "17.10.01_";
BA_ "GenSigSendType" SG_ 1747 Byte3_Data_4EC 2;
BA_ "UserSigValidity" SG_ 1747 Byte3_Data_4EC 1;
BA_ "GenSigTimeoutTime" SG_ 1747 Byte3_Data_4EC 0;
BA_ "Version" SG_ 1747 Byte3_Data_4EC "18.12.06";
BA_ "Description" SG_ 1747 Byte4_Data_4EC "17.10.01_";
BA_ "GenSigSendType" SG_ 1747 Byte4_Data_4EC 2;
BA_ "UserSigValidity" SG_ 1747 Byte4_Data_4EC 1;
BA_ "GenSigTimeoutTime" SG_ 1747 Byte4_Data_4EC 0;
BA_ "Version" SG_ 1747 Byte4_Data_4EC "18.12.06";
BA_ "Description" SG_ 1747 Byte5_Data_4EC "17.10.01_";
BA_ "GenSigSendType" SG_ 1747 Byte5_Data_4EC 2;
BA_ "UserSigValidity" SG_ 1747 Byte5_Data_4EC 1;
BA_ "GenSigTimeoutTime" SG_ 1747 Byte5_Data_4EC 0;
BA_ "Version" SG_ 1747 Byte5_Data_4EC "18.12.06";
BA_ "Description" SG_ 1747 Byte6_Data_4EC "17.10.01_";
BA_ "GenSigSendType" SG_ 1747 Byte6_Data_4EC 2;
BA_ "UserSigValidity" SG_ 1747 Byte6_Data_4EC 1;
BA_ "GenSigTimeoutTime" SG_ 1747 Byte6_Data_4EC 0;
BA_ "Version" SG_ 1747 Byte6_Data_4EC "18.12.06";
BA_ "Description" SG_ 1747 Byte7_Data_4EC "17.10.01_";
BA_ "GenSigSendType" SG_ 1747 Byte7_Data_4EC 2;
BA_ "UserSigValidity" SG_ 1747 Byte7_Data_4EC 1;
BA_ "GenSigTimeoutTime" SG_ 1747 Byte7_Data_4EC 0;
BA_ "Version" SG_ 1747 Byte7_Data_4EC "18.12.06";
BA_ "Description" SG_ 1747 Byte1_Data_4EC "17.10.01_";
BA_ "GenSigSendType" SG_ 1747 Byte1_Data_4EC 2;
BA_ "UserSigValidity" SG_ 1747 Byte1_Data_4EC 1;
BA_ "GenSigTimeoutTime" SG_ 1747 Byte1_Data_4EC 0;
BA_ "Version" SG_ 1747 Byte1_Data_4EC "18.12.06";
BA_ "GenMsgCycleTime" BO_ 1748 0;
BA_ "GenMsgILSupport" BO_ 1748 0;
BA_ "TpMessage" BO_ 1748 1;
BA_ "GenMsgDelayTime" BO_ 1748 0;
BA_ "Description" SG_ 1748 Byte0_TCP_4F6 "15.03.01_";
BA_ "GenSigSendType" SG_ 1748 Byte0_TCP_4F6 2;
BA_ "UserSigValidity" SG_ 1748 Byte0_TCP_4F6 1;
BA_ "GenSigTimeoutTime" SG_ 1748 Byte0_TCP_4F6 0;
BA_ "Version" SG_ 1748 Byte0_TCP_4F6 "18.12.06";
BA_ "Description" SG_ 1748 Byte2_Data_4F6 "15.03.01_";
BA_ "GenSigSendType" SG_ 1748 Byte2_Data_4F6 2;
BA_ "UserSigValidity" SG_ 1748 Byte2_Data_4F6 1;
BA_ "GenSigTimeoutTime" SG_ 1748 Byte2_Data_4F6 0;
BA_ "Version" SG_ 1748 Byte2_Data_4F6 "18.12.06";
BA_ "Description" SG_ 1748 Byte3_Data_4F6 "15.03.01_";
BA_ "GenSigSendType" SG_ 1748 Byte3_Data_4F6 2;
BA_ "UserSigValidity" SG_ 1748 Byte3_Data_4F6 1;
BA_ "GenSigTimeoutTime" SG_ 1748 Byte3_Data_4F6 0;
BA_ "Version" SG_ 1748 Byte3_Data_4F6 "18.12.06";
BA_ "Description" SG_ 1748 Byte4_Data_4F6 "15.03.01_";
BA_ "GenSigSendType" SG_ 1748 Byte4_Data_4F6 2;
BA_ "UserSigValidity" SG_ 1748 Byte4_Data_4F6 1;
BA_ "GenSigTimeoutTime" SG_ 1748 Byte4_Data_4F6 0;
BA_ "Version" SG_ 1748 Byte4_Data_4F6 "18.12.06";
BA_ "Description" SG_ 1748 Byte5_Data_4F6 "15.03.01_";
BA_ "GenSigSendType" SG_ 1748 Byte5_Data_4F6 2;
BA_ "UserSigValidity" SG_ 1748 Byte5_Data_4F6 1;
BA_ "GenSigTimeoutTime" SG_ 1748 Byte5_Data_4F6 0;
BA_ "Version" SG_ 1748 Byte5_Data_4F6 "18.12.06";
BA_ "Description" SG_ 1748 Byte6_Data_4F6 "15.03.01_";
BA_ "GenSigSendType" SG_ 1748 Byte6_Data_4F6 2;
BA_ "UserSigValidity" SG_ 1748 Byte6_Data_4F6 1;
BA_ "GenSigTimeoutTime" SG_ 1748 Byte6_Data_4F6 0;
BA_ "Version" SG_ 1748 Byte6_Data_4F6 "18.12.06";
BA_ "Description" SG_ 1748 Byte7_Data_4F6 "15.03.01_";
BA_ "GenSigSendType" SG_ 1748 Byte7_Data_4F6 2;
BA_ "UserSigValidity" SG_ 1748 Byte7_Data_4F6 1;
BA_ "GenSigTimeoutTime" SG_ 1748 Byte7_Data_4F6 0;
BA_ "Version" SG_ 1748 Byte7_Data_4F6 "18.12.06";
BA_ "Description" SG_ 1748 Byte1_Data_4F6 "15.03.01_";
BA_ "GenSigSendType" SG_ 1748 Byte1_Data_4F6 2;
BA_ "UserSigValidity" SG_ 1748 Byte1_Data_4F6 1;
BA_ "GenSigTimeoutTime" SG_ 1748 Byte1_Data_4F6 0;
BA_ "Version" SG_ 1748 Byte1_Data_4F6 "18.12.06";
BA_ "GenMsgCycleTime" BO_ 1749 0;
BA_ "GenMsgILSupport" BO_ 1749 0;
BA_ "TpMessage" BO_ 1749 1;
BA_ "GenMsgDelayTime" BO_ 1749 0;
BA_ "Description" SG_ 1749 Byte0_TCP_4F0 "17.05.02_";
BA_ "GenSigSendType" SG_ 1749 Byte0_TCP_4F0 2;
BA_ "UserSigValidity" SG_ 1749 Byte0_TCP_4F0 1;
BA_ "GenSigTimeoutTime" SG_ 1749 Byte0_TCP_4F0 0;
BA_ "Version" SG_ 1749 Byte0_TCP_4F0 "18.12.06";
BA_ "Description" SG_ 1749 Byte2_Data_4F0 "17.05.02_";
BA_ "GenSigSendType" SG_ 1749 Byte2_Data_4F0 2;
BA_ "UserSigValidity" SG_ 1749 Byte2_Data_4F0 1;
BA_ "GenSigTimeoutTime" SG_ 1749 Byte2_Data_4F0 0;
BA_ "Version" SG_ 1749 Byte2_Data_4F0 "18.12.06";
BA_ "Description" SG_ 1749 Byte3_Data_4F0 "17.05.02_";
BA_ "GenSigSendType" SG_ 1749 Byte3_Data_4F0 2;
BA_ "UserSigValidity" SG_ 1749 Byte3_Data_4F0 1;
BA_ "GenSigTimeoutTime" SG_ 1749 Byte3_Data_4F0 0;
BA_ "Version" SG_ 1749 Byte3_Data_4F0 "18.12.06";
BA_ "Description" SG_ 1749 Byte4_Data_4F0 "17.05.02_";
BA_ "GenSigSendType" SG_ 1749 Byte4_Data_4F0 2;
BA_ "UserSigValidity" SG_ 1749 Byte4_Data_4F0 1;
BA_ "GenSigTimeoutTime" SG_ 1749 Byte4_Data_4F0 0;
BA_ "Version" SG_ 1749 Byte4_Data_4F0 "18.12.06";
BA_ "Description" SG_ 1749 Byte5_Data_4F0 "17.05.02_";
BA_ "GenSigSendType" SG_ 1749 Byte5_Data_4F0 2;
BA_ "UserSigValidity" SG_ 1749 Byte5_Data_4F0 1;
BA_ "GenSigTimeoutTime" SG_ 1749 Byte5_Data_4F0 0;
BA_ "Version" SG_ 1749 Byte5_Data_4F0 "18.12.06";
BA_ "Description" SG_ 1749 Byte6_Data_4F0 "17.05.02_";
BA_ "GenSigSendType" SG_ 1749 Byte6_Data_4F0 2;
BA_ "UserSigValidity" SG_ 1749 Byte6_Data_4F0 1;
BA_ "GenSigTimeoutTime" SG_ 1749 Byte6_Data_4F0 0;
BA_ "Version" SG_ 1749 Byte6_Data_4F0 "18.12.06";
BA_ "Description" SG_ 1749 Byte7_Data_4F0 "17.05.02_";
BA_ "GenSigSendType" SG_ 1749 Byte7_Data_4F0 2;
BA_ "UserSigValidity" SG_ 1749 Byte7_Data_4F0 1;
BA_ "GenSigTimeoutTime" SG_ 1749 Byte7_Data_4F0 0;
BA_ "Version" SG_ 1749 Byte7_Data_4F0 "18.12.06";
BA_ "Description" SG_ 1749 Byte1_Data_4F0 "17.05.02_";
BA_ "GenSigSendType" SG_ 1749 Byte1_Data_4F0 2;
BA_ "UserSigValidity" SG_ 1749 Byte1_Data_4F0 1;
BA_ "GenSigTimeoutTime" SG_ 1749 Byte1_Data_4F0 0;
BA_ "Version" SG_ 1749 Byte1_Data_4F0 "18.12.06";
BA_ "GenMsgCycleTime" BO_ 1750 0;
BA_ "GenMsgILSupport" BO_ 1750 0;
BA_ "TpMessage" BO_ 1750 1;
BA_ "GenMsgDelayTime" BO_ 1750 0;
BA_ "Description" SG_ 1750 Byte0_TCP_4F2 "14.07.01_";
BA_ "GenSigSendType" SG_ 1750 Byte0_TCP_4F2 2;
BA_ "UserSigValidity" SG_ 1750 Byte0_TCP_4F2 1;
BA_ "GenSigTimeoutTime" SG_ 1750 Byte0_TCP_4F2 0;
BA_ "Version" SG_ 1750 Byte0_TCP_4F2 "18.12.06";
BA_ "Description" SG_ 1750 Byte2_Data_4F2 "14.07.01_";
BA_ "GenSigSendType" SG_ 1750 Byte2_Data_4F2 2;
BA_ "UserSigValidity" SG_ 1750 Byte2_Data_4F2 1;
BA_ "GenSigTimeoutTime" SG_ 1750 Byte2_Data_4F2 0;
BA_ "Version" SG_ 1750 Byte2_Data_4F2 "18.12.06";
BA_ "Description" SG_ 1750 Byte3_Data_4F2 "14.07.01_";
BA_ "GenSigSendType" SG_ 1750 Byte3_Data_4F2 2;
BA_ "UserSigValidity" SG_ 1750 Byte3_Data_4F2 1;
BA_ "GenSigTimeoutTime" SG_ 1750 Byte3_Data_4F2 0;
BA_ "Version" SG_ 1750 Byte3_Data_4F2 "18.12.06";
BA_ "Description" SG_ 1750 Byte4_Data_4F2 "14.07.01_";
BA_ "GenSigSendType" SG_ 1750 Byte4_Data_4F2 2;
BA_ "UserSigValidity" SG_ 1750 Byte4_Data_4F2 1;
BA_ "GenSigTimeoutTime" SG_ 1750 Byte4_Data_4F2 0;
BA_ "Version" SG_ 1750 Byte4_Data_4F2 "18.12.06";
BA_ "Description" SG_ 1750 Byte5_Data_4F2 "14.07.01_";
BA_ "GenSigSendType" SG_ 1750 Byte5_Data_4F2 2;
BA_ "UserSigValidity" SG_ 1750 Byte5_Data_4F2 1;
BA_ "GenSigTimeoutTime" SG_ 1750 Byte5_Data_4F2 0;
BA_ "Version" SG_ 1750 Byte5_Data_4F2 "18.12.06";
BA_ "Description" SG_ 1750 Byte6_Data_4F2 "14.07.01_";
BA_ "GenSigSendType" SG_ 1750 Byte6_Data_4F2 2;
BA_ "UserSigValidity" SG_ 1750 Byte6_Data_4F2 1;
BA_ "GenSigTimeoutTime" SG_ 1750 Byte6_Data_4F2 0;
BA_ "Version" SG_ 1750 Byte6_Data_4F2 "18.12.06";
BA_ "Description" SG_ 1750 Byte7_Data_4F2 "14.07.01_";
BA_ "GenSigSendType" SG_ 1750 Byte7_Data_4F2 2;
BA_ "UserSigValidity" SG_ 1750 Byte7_Data_4F2 1;
BA_ "GenSigTimeoutTime" SG_ 1750 Byte7_Data_4F2 0;
BA_ "Version" SG_ 1750 Byte7_Data_4F2 "18.12.06";
BA_ "Description" SG_ 1750 Byte1_Data_4F2 "14.07.01_";
BA_ "GenSigSendType" SG_ 1750 Byte1_Data_4F2 2;
BA_ "UserSigValidity" SG_ 1750 Byte1_Data_4F2 1;
BA_ "GenSigTimeoutTime" SG_ 1750 Byte1_Data_4F2 0;
BA_ "Version" SG_ 1750 Byte1_Data_4F2 "18.12.06";
BA_ "GenMsgCycleTime" BO_ 1756 0;
BA_ "GenMsgILSupport" BO_ 1756 0;
BA_ "TpMessage" BO_ 1756 1;
BA_ "GenMsgDelayTime" BO_ 1756 0;
BA_ "Description" SG_ 1756 Byte0_TCP_4E8 "1.08.00_";
BA_ "GenSigSendType" SG_ 1756 Byte0_TCP_4E8 2;
BA_ "UserSigValidity" SG_ 1756 Byte0_TCP_4E8 1;
BA_ "GenSigTimeoutTime" SG_ 1756 Byte0_TCP_4E8 0;
BA_ "Version" SG_ 1756 Byte0_TCP_4E8 "18.12.06";
BA_ "Description" SG_ 1756 Byte2_Data_4E8 "1.08.00_";
BA_ "GenSigSendType" SG_ 1756 Byte2_Data_4E8 2;
BA_ "UserSigValidity" SG_ 1756 Byte2_Data_4E8 1;
BA_ "GenSigTimeoutTime" SG_ 1756 Byte2_Data_4E8 0;
BA_ "Version" SG_ 1756 Byte2_Data_4E8 "18.12.06";
BA_ "Description" SG_ 1756 Byte3_Data_4E8 "1.08.00_";
BA_ "GenSigSendType" SG_ 1756 Byte3_Data_4E8 2;
BA_ "UserSigValidity" SG_ 1756 Byte3_Data_4E8 1;
BA_ "GenSigTimeoutTime" SG_ 1756 Byte3_Data_4E8 0;
BA_ "Version" SG_ 1756 Byte3_Data_4E8 "18.12.06";
BA_ "Description" SG_ 1756 Byte4_Data_4E8 "1.08.00_";
BA_ "GenSigSendType" SG_ 1756 Byte4_Data_4E8 2;
BA_ "UserSigValidity" SG_ 1756 Byte4_Data_4E8 1;
BA_ "GenSigTimeoutTime" SG_ 1756 Byte4_Data_4E8 0;
BA_ "Version" SG_ 1756 Byte4_Data_4E8 "18.12.06";
BA_ "Description" SG_ 1756 Byte5_Data_4E8 "1.08.00_";
BA_ "GenSigSendType" SG_ 1756 Byte5_Data_4E8 2;
BA_ "UserSigValidity" SG_ 1756 Byte5_Data_4E8 1;
BA_ "GenSigTimeoutTime" SG_ 1756 Byte5_Data_4E8 0;
BA_ "Version" SG_ 1756 Byte5_Data_4E8 "18.12.06";
BA_ "Description" SG_ 1756 Byte6_Data_4E8 "1.08.00_";
BA_ "GenSigSendType" SG_ 1756 Byte6_Data_4E8 2;
BA_ "UserSigValidity" SG_ 1756 Byte6_Data_4E8 1;
BA_ "GenSigTimeoutTime" SG_ 1756 Byte6_Data_4E8 0;
BA_ "Version" SG_ 1756 Byte6_Data_4E8 "18.12.06";
BA_ "Description" SG_ 1756 Byte7_Data_4E8 "1.08.00_";
BA_ "GenSigSendType" SG_ 1756 Byte7_Data_4E8 2;
BA_ "UserSigValidity" SG_ 1756 Byte7_Data_4E8 1;
BA_ "GenSigTimeoutTime" SG_ 1756 Byte7_Data_4E8 0;
BA_ "Version" SG_ 1756 Byte7_Data_4E8 "18.12.06";
BA_ "Description" SG_ 1756 Byte1_Data_4E8 "1.08.00_";
BA_ "GenSigSendType" SG_ 1756 Byte1_Data_4E8 2;
BA_ "UserSigValidity" SG_ 1756 Byte1_Data_4E8 1;
BA_ "GenSigTimeoutTime" SG_ 1756 Byte1_Data_4E8 0;
BA_ "Version" SG_ 1756 Byte1_Data_4E8 "18.12.06";
BA_ "GenMsgCycleTime" BO_ 1757 0;
BA_ "GenMsgILSupport" BO_ 1757 0;
BA_ "TpMessage" BO_ 1757 1;
BA_ "GenMsgDelayTime" BO_ 1757 0;
BA_ "Description" SG_ 1757 Byte0_TCP_4F8 "15.03.01_";
BA_ "GenSigSendType" SG_ 1757 Byte0_TCP_4F8 2;
BA_ "UserSigValidity" SG_ 1757 Byte0_TCP_4F8 1;
BA_ "GenSigTimeoutTime" SG_ 1757 Byte0_TCP_4F8 0;
BA_ "Version" SG_ 1757 Byte0_TCP_4F8 "18.12.06";
BA_ "Description" SG_ 1757 Byte2_Data_4F8 "15.03.01_";
BA_ "GenSigSendType" SG_ 1757 Byte2_Data_4F8 2;
BA_ "UserSigValidity" SG_ 1757 Byte2_Data_4F8 1;
BA_ "GenSigTimeoutTime" SG_ 1757 Byte2_Data_4F8 0;
BA_ "Version" SG_ 1757 Byte2_Data_4F8 "18.12.06";
BA_ "Description" SG_ 1757 Byte3_Data_4F8 "15.03.01_";
BA_ "GenSigSendType" SG_ 1757 Byte3_Data_4F8 2;
BA_ "UserSigValidity" SG_ 1757 Byte3_Data_4F8 1;
BA_ "GenSigTimeoutTime" SG_ 1757 Byte3_Data_4F8 0;
BA_ "Version" SG_ 1757 Byte3_Data_4F8 "18.12.06";
BA_ "Description" SG_ 1757 Byte4_Data_4F8 "15.03.01_";
BA_ "GenSigSendType" SG_ 1757 Byte4_Data_4F8 2;
BA_ "UserSigValidity" SG_ 1757 Byte4_Data_4F8 1;
BA_ "GenSigTimeoutTime" SG_ 1757 Byte4_Data_4F8 0;
BA_ "Version" SG_ 1757 Byte4_Data_4F8 "18.12.06";
BA_ "Description" SG_ 1757 Byte5_Data_4F8 "15.03.01_";
BA_ "GenSigSendType" SG_ 1757 Byte5_Data_4F8 2;
BA_ "UserSigValidity" SG_ 1757 Byte5_Data_4F8 1;
BA_ "GenSigTimeoutTime" SG_ 1757 Byte5_Data_4F8 0;
BA_ "Version" SG_ 1757 Byte5_Data_4F8 "18.12.06";
BA_ "Description" SG_ 1757 Byte6_Data_4F8 "15.03.01_";
BA_ "GenSigSendType" SG_ 1757 Byte6_Data_4F8 2;
BA_ "UserSigValidity" SG_ 1757 Byte6_Data_4F8 1;
BA_ "GenSigTimeoutTime" SG_ 1757 Byte6_Data_4F8 0;
BA_ "Version" SG_ 1757 Byte6_Data_4F8 "18.12.06";
BA_ "Description" SG_ 1757 Byte7_Data_4F8 "15.03.01_";
BA_ "GenSigSendType" SG_ 1757 Byte7_Data_4F8 2;
BA_ "UserSigValidity" SG_ 1757 Byte7_Data_4F8 1;
BA_ "GenSigTimeoutTime" SG_ 1757 Byte7_Data_4F8 0;
BA_ "Version" SG_ 1757 Byte7_Data_4F8 "18.12.06";
BA_ "Description" SG_ 1757 Byte1_Data_4F8 "15.03.01_";
BA_ "GenSigSendType" SG_ 1757 Byte1_Data_4F8 2;
BA_ "UserSigValidity" SG_ 1757 Byte1_Data_4F8 1;
BA_ "GenSigTimeoutTime" SG_ 1757 Byte1_Data_4F8 0;
BA_ "Version" SG_ 1757 Byte1_Data_4F8 "18.12.06";
BA_ "GenMsgCycleTime" BO_ 1758 0;
BA_ "GenMsgILSupport" BO_ 1758 0;
BA_ "TpMessage" BO_ 1758 1;
BA_ "GenMsgDelayTime" BO_ 1758 0;
BA_ "Description" SG_ 1758 Byte0_TCP_485 "15.03.01_";
BA_ "GenSigSendType" SG_ 1758 Byte0_TCP_485 2;
BA_ "UserSigValidity" SG_ 1758 Byte0_TCP_485 1;
BA_ "GenSigTimeoutTime" SG_ 1758 Byte0_TCP_485 0;
BA_ "Version" SG_ 1758 Byte0_TCP_485 "18.12.06";
BA_ "Description" SG_ 1758 Byte2_Data_485 "15.03.01_";
BA_ "GenSigSendType" SG_ 1758 Byte2_Data_485 2;
BA_ "UserSigValidity" SG_ 1758 Byte2_Data_485 1;
BA_ "GenSigTimeoutTime" SG_ 1758 Byte2_Data_485 0;
BA_ "Version" SG_ 1758 Byte2_Data_485 "18.12.06";
BA_ "Description" SG_ 1758 Byte3_Data_485 "15.03.01_";
BA_ "GenSigSendType" SG_ 1758 Byte3_Data_485 2;
BA_ "UserSigValidity" SG_ 1758 Byte3_Data_485 1;
BA_ "GenSigTimeoutTime" SG_ 1758 Byte3_Data_485 0;
BA_ "Version" SG_ 1758 Byte3_Data_485 "18.12.06";
BA_ "Description" SG_ 1758 Byte4_Data_485 "15.03.01_";
BA_ "GenSigSendType" SG_ 1758 Byte4_Data_485 2;
BA_ "UserSigValidity" SG_ 1758 Byte4_Data_485 1;
BA_ "GenSigTimeoutTime" SG_ 1758 Byte4_Data_485 0;
BA_ "Version" SG_ 1758 Byte4_Data_485 "18.12.06";
BA_ "Description" SG_ 1758 Byte5_Data_485 "15.03.01_";
BA_ "GenSigSendType" SG_ 1758 Byte5_Data_485 2;
BA_ "UserSigValidity" SG_ 1758 Byte5_Data_485 1;
BA_ "GenSigTimeoutTime" SG_ 1758 Byte5_Data_485 0;
BA_ "Version" SG_ 1758 Byte5_Data_485 "18.12.06";
BA_ "Description" SG_ 1758 Byte6_Data_485 "15.03.01_";
BA_ "GenSigSendType" SG_ 1758 Byte6_Data_485 2;
BA_ "UserSigValidity" SG_ 1758 Byte6_Data_485 1;
BA_ "GenSigTimeoutTime" SG_ 1758 Byte6_Data_485 0;
BA_ "Version" SG_ 1758 Byte6_Data_485 "18.12.06";
BA_ "Description" SG_ 1758 Byte7_Data_485 "15.03.01_";
BA_ "GenSigSendType" SG_ 1758 Byte7_Data_485 2;
BA_ "UserSigValidity" SG_ 1758 Byte7_Data_485 1;
BA_ "GenSigTimeoutTime" SG_ 1758 Byte7_Data_485 0;
BA_ "Version" SG_ 1758 Byte7_Data_485 "18.12.06";
BA_ "Description" SG_ 1758 Byte1_Data_485 "15.03.01_";
BA_ "GenSigSendType" SG_ 1758 Byte1_Data_485 2;
BA_ "UserSigValidity" SG_ 1758 Byte1_Data_485 1;
BA_ "GenSigTimeoutTime" SG_ 1758 Byte1_Data_485 0;
BA_ "Version" SG_ 1758 Byte1_Data_485 "18.12.06";
BA_ "GenMsgCycleTime" BO_ 1760 0;
BA_ "GenMsgILSupport" BO_ 1760 0;
BA_ "TpMessage" BO_ 1760 1;
BA_ "GenMsgDelayTime" BO_ 1760 0;
BA_ "Description" SG_ 1760 Byte0_TCP_4EE "1.08.00_";
BA_ "GenSigSendType" SG_ 1760 Byte0_TCP_4EE 2;
BA_ "UserSigValidity" SG_ 1760 Byte0_TCP_4EE 1;
BA_ "GenSigTimeoutTime" SG_ 1760 Byte0_TCP_4EE 0;
BA_ "Version" SG_ 1760 Byte0_TCP_4EE "18.12.06";
BA_ "Description" SG_ 1760 Byte2_Data_4EE "1.08.00_";
BA_ "GenSigSendType" SG_ 1760 Byte2_Data_4EE 2;
BA_ "UserSigValidity" SG_ 1760 Byte2_Data_4EE 1;
BA_ "GenSigTimeoutTime" SG_ 1760 Byte2_Data_4EE 0;
BA_ "Version" SG_ 1760 Byte2_Data_4EE "18.12.06";
BA_ "Description" SG_ 1760 Byte3_Data_4EE "1.08.00_";
BA_ "GenSigSendType" SG_ 1760 Byte3_Data_4EE 2;
BA_ "UserSigValidity" SG_ 1760 Byte3_Data_4EE 1;
BA_ "GenSigTimeoutTime" SG_ 1760 Byte3_Data_4EE 0;
BA_ "Version" SG_ 1760 Byte3_Data_4EE "18.12.06";
BA_ "Description" SG_ 1760 Byte4_Data_4EE "1.08.00_";
BA_ "GenSigSendType" SG_ 1760 Byte4_Data_4EE 2;
BA_ "UserSigValidity" SG_ 1760 Byte4_Data_4EE 1;
BA_ "GenSigTimeoutTime" SG_ 1760 Byte4_Data_4EE 0;
BA_ "Version" SG_ 1760 Byte4_Data_4EE "18.12.06";
BA_ "Description" SG_ 1760 Byte5_Data_4EE "1.08.00_";
BA_ "GenSigSendType" SG_ 1760 Byte5_Data_4EE 2;
BA_ "UserSigValidity" SG_ 1760 Byte5_Data_4EE 1;
BA_ "GenSigTimeoutTime" SG_ 1760 Byte5_Data_4EE 0;
BA_ "Version" SG_ 1760 Byte5_Data_4EE "18.12.06";
BA_ "Description" SG_ 1760 Byte6_Data_4EE "1.08.00_";
BA_ "GenSigSendType" SG_ 1760 Byte6_Data_4EE 2;
BA_ "UserSigValidity" SG_ 1760 Byte6_Data_4EE 1;
BA_ "GenSigTimeoutTime" SG_ 1760 Byte6_Data_4EE 0;
BA_ "Version" SG_ 1760 Byte6_Data_4EE "18.12.06";
BA_ "Description" SG_ 1760 Byte7_Data_4EE "1.08.00_";
BA_ "GenSigSendType" SG_ 1760 Byte7_Data_4EE 2;
BA_ "UserSigValidity" SG_ 1760 Byte7_Data_4EE 1;
BA_ "GenSigTimeoutTime" SG_ 1760 Byte7_Data_4EE 0;
BA_ "Version" SG_ 1760 Byte7_Data_4EE "18.12.06";
BA_ "Description" SG_ 1760 Byte1_Data_4EE "1.08.00_";
BA_ "GenSigSendType" SG_ 1760 Byte1_Data_4EE 2;
BA_ "UserSigValidity" SG_ 1760 Byte1_Data_4EE 1;
BA_ "GenSigTimeoutTime" SG_ 1760 Byte1_Data_4EE 0;
BA_ "Version" SG_ 1760 Byte1_Data_4EE "18.12.06";
BA_ "GenMsgCycleTime" BO_ 1761 0;
BA_ "GenMsgILSupport" BO_ 1761 0;
BA_ "TpMessage" BO_ 1761 1;
BA_ "GenMsgDelayTime" BO_ 1761 0;
BA_ "Description" SG_ 1761 Byte0_TCP_48F "1.08.00_";
BA_ "GenSigSendType" SG_ 1761 Byte0_TCP_48F 2;
BA_ "UserSigValidity" SG_ 1761 Byte0_TCP_48F 1;
BA_ "GenSigTimeoutTime" SG_ 1761 Byte0_TCP_48F 0;
BA_ "Version" SG_ 1761 Byte0_TCP_48F "18.12.06";
BA_ "Description" SG_ 1761 Byte2_Data_48F "1.08.00_";
BA_ "GenSigSendType" SG_ 1761 Byte2_Data_48F 2;
BA_ "UserSigValidity" SG_ 1761 Byte2_Data_48F 1;
BA_ "GenSigTimeoutTime" SG_ 1761 Byte2_Data_48F 0;
BA_ "Version" SG_ 1761 Byte2_Data_48F "18.12.06";
BA_ "Description" SG_ 1761 Byte3_Data_48F "1.08.00_";
BA_ "GenSigSendType" SG_ 1761 Byte3_Data_48F 2;
BA_ "UserSigValidity" SG_ 1761 Byte3_Data_48F 1;
BA_ "GenSigTimeoutTime" SG_ 1761 Byte3_Data_48F 0;
BA_ "Version" SG_ 1761 Byte3_Data_48F "18.12.06";
BA_ "Description" SG_ 1761 Byte4_Data_48F "1.08.00_";
BA_ "GenSigSendType" SG_ 1761 Byte4_Data_48F 2;
BA_ "UserSigValidity" SG_ 1761 Byte4_Data_48F 1;
BA_ "GenSigTimeoutTime" SG_ 1761 Byte4_Data_48F 0;
BA_ "Version" SG_ 1761 Byte4_Data_48F "18.12.06";
BA_ "Description" SG_ 1761 Byte5_Data_48F "1.08.00_";
BA_ "GenSigSendType" SG_ 1761 Byte5_Data_48F 2;
BA_ "UserSigValidity" SG_ 1761 Byte5_Data_48F 1;
BA_ "GenSigTimeoutTime" SG_ 1761 Byte5_Data_48F 0;
BA_ "Version" SG_ 1761 Byte5_Data_48F "18.12.06";
BA_ "Description" SG_ 1761 Byte6_Data_48F "1.08.00_";
BA_ "GenSigSendType" SG_ 1761 Byte6_Data_48F 2;
BA_ "UserSigValidity" SG_ 1761 Byte6_Data_48F 1;
BA_ "GenSigTimeoutTime" SG_ 1761 Byte6_Data_48F 0;
BA_ "Version" SG_ 1761 Byte6_Data_48F "18.12.06";
BA_ "Description" SG_ 1761 Byte7_Data_48F "1.08.00_";
BA_ "GenSigSendType" SG_ 1761 Byte7_Data_48F 2;
BA_ "UserSigValidity" SG_ 1761 Byte7_Data_48F 1;
BA_ "GenSigTimeoutTime" SG_ 1761 Byte7_Data_48F 0;
BA_ "Version" SG_ 1761 Byte7_Data_48F "18.12.06";
BA_ "Description" SG_ 1761 Byte1_Data_48F "1.08.00_";
BA_ "GenSigSendType" SG_ 1761 Byte1_Data_48F 2;
BA_ "UserSigValidity" SG_ 1761 Byte1_Data_48F 1;
BA_ "GenSigTimeoutTime" SG_ 1761 Byte1_Data_48F 0;
BA_ "Version" SG_ 1761 Byte1_Data_48F "18.12.06";
BA_ "GenMsgCycleTime" BO_ 1764 0;
BA_ "GenMsgILSupport" BO_ 1764 0;
BA_ "TpMessage" BO_ 1764 1;
BA_ "GenMsgDelayTime" BO_ 1764 0;
BA_ "Description" SG_ 1764 Byte0_TCP_4E6 "18.06.00_";
BA_ "GenSigSendType" SG_ 1764 Byte0_TCP_4E6 2;
BA_ "UserSigValidity" SG_ 1764 Byte0_TCP_4E6 1;
BA_ "GenSigTimeoutTime" SG_ 1764 Byte0_TCP_4E6 0;
BA_ "Version" SG_ 1764 Byte0_TCP_4E6 "18.12.06";
BA_ "Description" SG_ 1764 Byte2_Data_4E6 "18.06.00_";
BA_ "GenSigSendType" SG_ 1764 Byte2_Data_4E6 2;
BA_ "UserSigValidity" SG_ 1764 Byte2_Data_4E6 1;
BA_ "GenSigTimeoutTime" SG_ 1764 Byte2_Data_4E6 0;
BA_ "Version" SG_ 1764 Byte2_Data_4E6 "18.12.06";
BA_ "Description" SG_ 1764 Byte3_Data_4E6 "18.06.00_";
BA_ "GenSigSendType" SG_ 1764 Byte3_Data_4E6 2;
BA_ "UserSigValidity" SG_ 1764 Byte3_Data_4E6 1;
BA_ "GenSigTimeoutTime" SG_ 1764 Byte3_Data_4E6 0;
BA_ "Version" SG_ 1764 Byte3_Data_4E6 "18.12.06";
BA_ "Description" SG_ 1764 Byte4_Data_4E6 "18.06.00_";
BA_ "GenSigSendType" SG_ 1764 Byte4_Data_4E6 2;
BA_ "UserSigValidity" SG_ 1764 Byte4_Data_4E6 1;
BA_ "GenSigTimeoutTime" SG_ 1764 Byte4_Data_4E6 0;
BA_ "Version" SG_ 1764 Byte4_Data_4E6 "18.12.06";
BA_ "Description" SG_ 1764 Byte5_Data_4E6 "18.06.00_";
BA_ "GenSigSendType" SG_ 1764 Byte5_Data_4E6 2;
BA_ "UserSigValidity" SG_ 1764 Byte5_Data_4E6 1;
BA_ "GenSigTimeoutTime" SG_ 1764 Byte5_Data_4E6 0;
BA_ "Version" SG_ 1764 Byte5_Data_4E6 "18.12.06";
BA_ "Description" SG_ 1764 Byte6_Data_4E6 "18.06.00_";
BA_ "GenSigSendType" SG_ 1764 Byte6_Data_4E6 2;
BA_ "UserSigValidity" SG_ 1764 Byte6_Data_4E6 1;
BA_ "GenSigTimeoutTime" SG_ 1764 Byte6_Data_4E6 0;
BA_ "Version" SG_ 1764 Byte6_Data_4E6 "18.12.06";
BA_ "Description" SG_ 1764 Byte7_Data_4E6 "18.06.00_";
BA_ "GenSigSendType" SG_ 1764 Byte7_Data_4E6 2;
BA_ "UserSigValidity" SG_ 1764 Byte7_Data_4E6 1;
BA_ "GenSigTimeoutTime" SG_ 1764 Byte7_Data_4E6 0;
BA_ "Version" SG_ 1764 Byte7_Data_4E6 "18.12.06";
BA_ "Description" SG_ 1764 Byte1_Data_4E6 "18.06.00_";
BA_ "GenSigSendType" SG_ 1764 Byte1_Data_4E6 2;
BA_ "UserSigValidity" SG_ 1764 Byte1_Data_4E6 1;
BA_ "GenSigTimeoutTime" SG_ 1764 Byte1_Data_4E6 0;
BA_ "Version" SG_ 1764 Byte1_Data_4E6 "18.12.06";
BA_ "GenMsgCycleTime" BO_ 1767 0;
BA_ "GenMsgILSupport" BO_ 1767 0;
BA_ "TpMessage" BO_ 1767 1;
BA_ "GenMsgDelayTime" BO_ 1767 0;
BA_ "Description" SG_ 1767 Byte0_TCP_49B "1.08.00_";
BA_ "GenSigSendType" SG_ 1767 Byte0_TCP_49B 2;
BA_ "UserSigValidity" SG_ 1767 Byte0_TCP_49B 1;
BA_ "GenSigTimeoutTime" SG_ 1767 Byte0_TCP_49B 0;
BA_ "Version" SG_ 1767 Byte0_TCP_49B "18.12.06";
BA_ "Description" SG_ 1767 Byte2_Data_49B "1.08.00_";
BA_ "GenSigSendType" SG_ 1767 Byte2_Data_49B 2;
BA_ "UserSigValidity" SG_ 1767 Byte2_Data_49B 1;
BA_ "GenSigTimeoutTime" SG_ 1767 Byte2_Data_49B 0;
BA_ "Version" SG_ 1767 Byte2_Data_49B "18.12.06";
BA_ "Description" SG_ 1767 Byte3_Data_49B "1.08.00_";
BA_ "GenSigSendType" SG_ 1767 Byte3_Data_49B 2;
BA_ "UserSigValidity" SG_ 1767 Byte3_Data_49B 1;
BA_ "GenSigTimeoutTime" SG_ 1767 Byte3_Data_49B 0;
BA_ "Version" SG_ 1767 Byte3_Data_49B "18.12.06";
BA_ "Description" SG_ 1767 Byte4_Data_49B "1.08.00_";
BA_ "GenSigSendType" SG_ 1767 Byte4_Data_49B 2;
BA_ "UserSigValidity" SG_ 1767 Byte4_Data_49B 1;
BA_ "GenSigTimeoutTime" SG_ 1767 Byte4_Data_49B 0;
BA_ "Version" SG_ 1767 Byte4_Data_49B "18.12.06";
BA_ "Description" SG_ 1767 Byte5_Data_49B "1.08.00_";
BA_ "GenSigSendType" SG_ 1767 Byte5_Data_49B 2;
BA_ "UserSigValidity" SG_ 1767 Byte5_Data_49B 1;
BA_ "GenSigTimeoutTime" SG_ 1767 Byte5_Data_49B 0;
BA_ "Version" SG_ 1767 Byte5_Data_49B "18.12.06";
BA_ "Description" SG_ 1767 Byte6_Data_49B "1.08.00_";
BA_ "GenSigSendType" SG_ 1767 Byte6_Data_49B 2;
BA_ "UserSigValidity" SG_ 1767 Byte6_Data_49B 1;
BA_ "GenSigTimeoutTime" SG_ 1767 Byte6_Data_49B 0;
BA_ "Version" SG_ 1767 Byte6_Data_49B "18.12.06";
BA_ "Description" SG_ 1767 Byte7_Data_49B "1.08.00_";
BA_ "GenSigSendType" SG_ 1767 Byte7_Data_49B 2;
BA_ "UserSigValidity" SG_ 1767 Byte7_Data_49B 1;
BA_ "GenSigTimeoutTime" SG_ 1767 Byte7_Data_49B 0;
BA_ "Version" SG_ 1767 Byte7_Data_49B "18.12.06";
BA_ "Description" SG_ 1767 Byte1_Data_49B "1.08.00_";
BA_ "GenSigSendType" SG_ 1767 Byte1_Data_49B 2;
BA_ "UserSigValidity" SG_ 1767 Byte1_Data_49B 1;
BA_ "GenSigTimeoutTime" SG_ 1767 Byte1_Data_49B 0;
BA_ "Version" SG_ 1767 Byte1_Data_49B "18.12.06";
BA_ "GenMsgCycleTime" BO_ 1768 0;
BA_ "GenMsgILSupport" BO_ 1768 0;
BA_ "TpMessage" BO_ 1768 1;
BA_ "GenMsgDelayTime" BO_ 1768 0;
BA_ "Description" SG_ 1768 Byte0_TCP_4E4 "18.02.05_";
BA_ "GenSigSendType" SG_ 1768 Byte0_TCP_4E4 2;
BA_ "UserSigValidity" SG_ 1768 Byte0_TCP_4E4 1;
BA_ "GenSigTimeoutTime" SG_ 1768 Byte0_TCP_4E4 0;
BA_ "Version" SG_ 1768 Byte0_TCP_4E4 "18.12.06";
BA_ "Description" SG_ 1768 Byte2_Data_4E4 "18.02.05_";
BA_ "GenSigSendType" SG_ 1768 Byte2_Data_4E4 2;
BA_ "UserSigValidity" SG_ 1768 Byte2_Data_4E4 1;
BA_ "GenSigTimeoutTime" SG_ 1768 Byte2_Data_4E4 0;
BA_ "Version" SG_ 1768 Byte2_Data_4E4 "18.12.06";
BA_ "Description" SG_ 1768 Byte3_Data_4E4 "18.02.05_";
BA_ "GenSigSendType" SG_ 1768 Byte3_Data_4E4 2;
BA_ "UserSigValidity" SG_ 1768 Byte3_Data_4E4 1;
BA_ "GenSigTimeoutTime" SG_ 1768 Byte3_Data_4E4 0;
BA_ "Version" SG_ 1768 Byte3_Data_4E4 "18.12.06";
BA_ "Description" SG_ 1768 Byte4_Data_4E4 "18.02.05_";
BA_ "GenSigSendType" SG_ 1768 Byte4_Data_4E4 2;
BA_ "UserSigValidity" SG_ 1768 Byte4_Data_4E4 1;
BA_ "GenSigTimeoutTime" SG_ 1768 Byte4_Data_4E4 0;
BA_ "Version" SG_ 1768 Byte4_Data_4E4 "18.12.06";
BA_ "Description" SG_ 1768 Byte5_Data_4E4 "18.02.05_";
BA_ "GenSigSendType" SG_ 1768 Byte5_Data_4E4 2;
BA_ "UserSigValidity" SG_ 1768 Byte5_Data_4E4 1;
BA_ "GenSigTimeoutTime" SG_ 1768 Byte5_Data_4E4 0;
BA_ "Version" SG_ 1768 Byte5_Data_4E4 "18.12.06";
BA_ "Description" SG_ 1768 Byte6_Data_4E4 "18.02.05_";
BA_ "GenSigSendType" SG_ 1768 Byte6_Data_4E4 2;
BA_ "UserSigValidity" SG_ 1768 Byte6_Data_4E4 1;
BA_ "GenSigTimeoutTime" SG_ 1768 Byte6_Data_4E4 0;
BA_ "Version" SG_ 1768 Byte6_Data_4E4 "18.12.06";
BA_ "Description" SG_ 1768 Byte7_Data_4E4 "18.02.05_";
BA_ "GenSigSendType" SG_ 1768 Byte7_Data_4E4 2;
BA_ "UserSigValidity" SG_ 1768 Byte7_Data_4E4 1;
BA_ "GenSigTimeoutTime" SG_ 1768 Byte7_Data_4E4 0;
BA_ "Version" SG_ 1768 Byte7_Data_4E4 "18.12.06";
BA_ "Description" SG_ 1768 Byte1_Data_4E4 "18.02.05_";
BA_ "GenSigSendType" SG_ 1768 Byte1_Data_4E4 2;
BA_ "UserSigValidity" SG_ 1768 Byte1_Data_4E4 1;
BA_ "GenSigTimeoutTime" SG_ 1768 Byte1_Data_4E4 0;
BA_ "Version" SG_ 1768 Byte1_Data_4E4 "18.12.06";
BA_ "GenMsgCycleTime" BO_ 1770 0;
BA_ "GenMsgILSupport" BO_ 1770 0;
BA_ "TpMessage" BO_ 1770 1;
BA_ "GenMsgDelayTime" BO_ 1770 0;
BA_ "Description" SG_ 1770 Byte0_TCP_490 "1.08.00_";
BA_ "GenSigSendType" SG_ 1770 Byte0_TCP_490 2;
BA_ "UserSigValidity" SG_ 1770 Byte0_TCP_490 1;
BA_ "GenSigTimeoutTime" SG_ 1770 Byte0_TCP_490 0;
BA_ "Version" SG_ 1770 Byte0_TCP_490 "18.12.06";
BA_ "Description" SG_ 1770 Byte2_Data_490 "1.08.00_";
BA_ "GenSigSendType" SG_ 1770 Byte2_Data_490 2;
BA_ "UserSigValidity" SG_ 1770 Byte2_Data_490 1;
BA_ "GenSigTimeoutTime" SG_ 1770 Byte2_Data_490 0;
BA_ "Version" SG_ 1770 Byte2_Data_490 "18.12.06";
BA_ "Description" SG_ 1770 Byte3_Data_490 "1.08.00_";
BA_ "GenSigSendType" SG_ 1770 Byte3_Data_490 2;
BA_ "UserSigValidity" SG_ 1770 Byte3_Data_490 1;
BA_ "GenSigTimeoutTime" SG_ 1770 Byte3_Data_490 0;
BA_ "Version" SG_ 1770 Byte3_Data_490 "18.12.06";
BA_ "Description" SG_ 1770 Byte4_Data_490 "1.08.00_";
BA_ "GenSigSendType" SG_ 1770 Byte4_Data_490 2;
BA_ "UserSigValidity" SG_ 1770 Byte4_Data_490 1;
BA_ "GenSigTimeoutTime" SG_ 1770 Byte4_Data_490 0;
BA_ "Version" SG_ 1770 Byte4_Data_490 "18.12.06";
BA_ "Description" SG_ 1770 Byte5_Data_490 "1.08.00_";
BA_ "GenSigSendType" SG_ 1770 Byte5_Data_490 2;
BA_ "UserSigValidity" SG_ 1770 Byte5_Data_490 1;
BA_ "GenSigTimeoutTime" SG_ 1770 Byte5_Data_490 0;
BA_ "Version" SG_ 1770 Byte5_Data_490 "18.12.06";
BA_ "Description" SG_ 1770 Byte6_Data_490 "1.08.00_";
BA_ "GenSigSendType" SG_ 1770 Byte6_Data_490 2;
BA_ "UserSigValidity" SG_ 1770 Byte6_Data_490 1;
BA_ "GenSigTimeoutTime" SG_ 1770 Byte6_Data_490 0;
BA_ "Version" SG_ 1770 Byte6_Data_490 "18.12.06";
BA_ "Description" SG_ 1770 Byte7_Data_490 "1.08.00_";
BA_ "GenSigSendType" SG_ 1770 Byte7_Data_490 2;
BA_ "UserSigValidity" SG_ 1770 Byte7_Data_490 1;
BA_ "GenSigTimeoutTime" SG_ 1770 Byte7_Data_490 0;
BA_ "Version" SG_ 1770 Byte7_Data_490 "18.12.06";
BA_ "Description" SG_ 1770 Byte1_Data_490 "1.08.00_";
BA_ "GenSigSendType" SG_ 1770 Byte1_Data_490 2;
BA_ "UserSigValidity" SG_ 1770 Byte1_Data_490 1;
BA_ "GenSigTimeoutTime" SG_ 1770 Byte1_Data_490 0;
BA_ "Version" SG_ 1770 Byte1_Data_490 "18.12.06";
BA_ "NmMessage" BO_ 1377 1;
BA_ "GenMsgILSupport" BO_ 1377 0;
BA_ "NWM-Botschaft" BO_ 1377 1;
BA_ "NmMessage" BO_ 1379 1;
BA_ "GenMsgILSupport" BO_ 1379 0;
BA_ "NWM-Botschaft" BO_ 1379 1;
BA_ "NmMessage" BO_ 1302 1;
BA_ "GenMsgILSupport" BO_ 1302 0;
BA_ "NWM-Botschaft" BO_ 1302 1;
VAL_ 810 C_BLEOption 0 "None" 1 "BLE Option" 2 "Reserved" 3 "Reserved" ;
VAL_ 810 C_BLE_ProfileIDRValue 0 "Default" 1 "Guest" 2 "Profile1" 3 "Profile2" 4 "Reserved" 5 "Reserved" 6 "Reserved" 7 "Reserved" 8 "Reserved" 9 "Reserved" 10 "Reserved" 11 "Reserved" 12 "Reserved" 13 "Reserved" 14 "Reserved" 15 "Invalid" ;
VAL_ 810 C_BLEIDOut 0 "None" 1 "Buzzer On" 2 "Reserved" 3 "Invalid" ;
VAL_ 810 C_BLEKeyreminder 0 "Default(Normal)" 1 "Auth fail1" 2 "Auth fail2" 3 "Vehicle ON" 4 "No Policy" 5 "Reserved" 6 "Reserved" 7 "Invalid" ;
VAL_ 1228 TBT_Display_Type 0 "No Symbol" 1 "No info" 16 "Turn Combination2" 17 "Exit-R" 18 "Exit-L" 19 "Exit Combination1-R" 20 "Exit Combination1-L" 21 "Exit Combination2-R" 22 "Exit Combination2-L" 23 "Srv Road-R" 24 "Srv Road-L" 25 "Fork-2" 26 "Fork-3" 27 "Roundabout Trs-R" 28 "Roundabout Trs-L" 29 "Square Trs-R" 30 "Square Trs-L" 31 "U turn" 2 "Direction to Dest" 32 "Exit Roundabout Trs-R" 33 "Exit Roundabout Trs-L" 34 "Prepare Turn" 35 "Prepare Roundabout" 36 "Prepare Exit" 37 "Prepare Square" 38 "Prepare U Turn" 39 "Exit Ramp Up-R" 40 "Exit Ramp Down-R" 41 "Exit Ramp Up-L" 42 "Exit Ramp Down-L" 43 "Overpass-R" 44 "Overpass-L" 45 "Underpass-R" 46 "Underpass-L" 47 "Schematic Diagram" 3 "Arrived" 4 "Near Dest" 64 "No Direction" 65 "Straight" 66 "Turn 1 oclock" 67 "Turn-R" 68 "Turn 4 oclock" 69 "Turn 8 oclock" 70 "Turn-L" 71 "Turn 11 oclock" 72 "U Turn-L" 73 "U Turn-R" 74 "P Turn-L" 75 "P Turn-R" 76 "Permitted Turn-L" 5 "Arrived Dest Off Map" 80 "Aside Overpass-C" 81 "Aside Overpass-R" 82 "Aside Overpass-L" 83 "Aside Underpass-C" 84 "Aside Underpass-R" 85 "Aside Underpass-L" 86 "Into Overpass-C" 87 "Into Overpass-R" 88 "Into Overpass-L" 89 "Into Underpass-C" 90 "Into Underpass-R" 91 "Into Underpass-L" 6 "OffRoad" 96 "Roundabout(R12)" 97 "Roundabout(R1~R11)" 98 "Roundabout(R1~R11)" 99 "Roundabout(R1~R11)" 100 "Roundabout(R1~R11)" 101 "Roundabout(R1~R11)" 102 "Roundabout(R1~R11)" 103 "Roundabout(R1~R11)" 104 "Roundabout(R1~R11)" 105 "Roundabout(R1~R11)" 106 "Roundabout(R1~R11)" 107 "Roundabout(R1~R11)" 7 "Off Map" 112 "Dest-C" 113 "Dest-R" 114 "Dest-L" 115 "WP1-C" 116 "WP1-R" 117 "WP1-L" 118 "WP2-C" 119 "WP2-R" 120 "WP2-L" 121 "WP3-C" 122 "WP3-R" 123 "WP3-L" 124 "WP4-C" 125 "WP4-R" 126 "WP4-L" 8 "No Route(Compass)" 128 "WP5-C" 129 "WP5-L" 130 "WP5-R" 131 "WP6-C" 132 "WP6-L" 133 "WP6-R" 134 "WP7-C" 135 "WP7-L" 136 "WP7-R" 137 "walk to Dest" 138 "walk to WP1" 139 "walk to WP2" 140 "walk to WP3" 141 "walk to WP4" 9 "Calc Route" 144 "Fork-2-R" 145 "Fork-2-L" 146 "Fork-SR Straight" 147 "Fork-SR-R" 148 "Fork-SL Straight" 149 "Fork-SL-L" 10 "Recalc Route" 160 "FWY Entrance-C" 161 "FWY Entrance-R" 162 "FWY Entrance-L" 163 "FWY Exit-C" 164 "FWY Exit-R" 165 "FWY Exit-L" 166 "CHWY Entrance-C" 167 "CHWY Entrance-R" 168 "CHWY Entrance-L" 169 "CHWY Exit-C" 170 "CHWY Exit-R" 171 "CHWY Exit-L" 172 "MainRoad Entrance-C" 173 "MainRoad Entrance-R" 174 "MainRoad Entrance-L" 11 "Follow Street" 176 "Ferry" 177 "Tunnel" 178 "Toll" 179 "IC" 180 "JC" 181 "SA" 182 "PA" 183 "SA Entrance" 184 "Coin Toll" 185 "JC Exit-C" 186 "JC Exit-R" 187 "JC Exit-L" 12 "Change Lane" 192 "Roundabout(L12)" 193 "Roundabout(L1~L11)" 194 "Roundabout(L1~L11)" 195 "Roundabout(L1~L11)" 196 "Roundabout(L1~L11)" 197 "Roundabout(L1~L11)" 198 "Roundabout(L1~L11)" 199 "Roundabout(L1~L11)" 200 "Roundabout(L1~L11)" 201 "Roundabout(L1~L11)" 202 "Roundabout(L1~L11)" 203 "Roundabout(L1~L11)" 204 "Enter roundabout" 205 "Exit roundabout" 206 "most-L of line" 207 "most-R of line" 13 "Turn" 208 "M of line" 209 "most-L of 3 normal_JCT_SAPA" 210 "most-R of 3 normal_JCT_SAPA" 211 "Enter ferry" 212 "Exit ferry" 213 "L_2Branch_L_Base" 214 "L_2Branch_R_Base" 215 "R_2Branch_L_Base" 216 "R_2Branch_R_Base" 217 "Straight_Front" 218 "M of 3 normal_JCT_SAPA" 219 "Starting Point" 220 "IC 2 on L straight walk IC" 221 "IC 2 on the R straight walk IC" 222 "Normal_JCT_SAPA 2 on L straight line" 223 "Normal_JCT_SAPA 2 on R straight line" 14 "Turn On Main Road" 224 "Normal_JCT_SAPA 3 on L straight line" 225 "Normal_JCT_SAPA 3 on M straight line" 226 "Normal_JCT_SAPA 3 on R straight line" 227 "IC 3 on L side of IC" 228 "IC 3 on M side of IC" 229 "IC 3 on R side of IC" 230 "IC 3 on L straight line" 231 "IC 3 on M straight line" 232 "IC 3 on R straight line" 233 "8 direction straight L" 234 "8 direction straight R" 235 "8 direction on the most L straight line" 236 "8 direction on M straight line" 237 "8 direction on the most R straight line" 238 "L_3Branch_L_Base" 239 "L_3Branch_M_Base" 15 "Turn Combination1" 240 "L_3Branch_R_Base" 241 "R_3Branch_L_Base" 242 "R_3Branch_M_Base" 243 "R_3Branch_R_Base" 248 "8 direction turn around, then L" 249 "8 direction turn around, then R" 250 "8 direction turn around, then the most L" 251 "8 direction turn around, then M" 252 "8 direction turn around, then the most R" 253 "Reserved" 254 "Reserved" 255 "Invalid" ;
VAL_ 1228 TBT_Direction 0 "Increase value (0~352.5 deg.)" 1 "Increase value (0~352.5 deg.)" 2 "Increase value (0~352.5 deg.)" 3 "Increase value (0~352.5 deg.)" 4 "Increase value (0~352.5 deg.)" 5 "Increase value (0~352.5 deg.)" 6 "Increase value (0~352.5 deg.)" 7 "Increase value (0~352.5 deg.)" 8 "Increase value (0~352.5 deg.)" 9 "Increase value (0~352.5 deg.)" 10 "Increase value (0~352.5 deg.)" 11 "Increase value (0~352.5 deg.)" 12 "Increase value (0~352.5 deg.)" 13 "Increase value (0~352.5 deg.)" 14 "Increase value (0~352.5 deg.)" 15 "Increase value (0~352.5 deg.)" 16 "Increase value (0~352.5 deg.)" 17 "Increase value (0~352.5 deg.)" 18 "Increase value (0~352.5 deg.)" 19 "Increase value (0~352.5 deg.)" 20 "Increase value (0~352.5 deg.)" 21 "Increase value (0~352.5 deg.)" 22 "Increase value (0~352.5 deg.)" 23 "Increase value (0~352.5 deg.)" 24 "Increase value (0~352.5 deg.)" 25 "Increase value (0~352.5 deg.)" 26 "Increase value (0~352.5 deg.)" 27 "Increase value (0~352.5 deg.)" 28 "Increase value (0~352.5 deg.)" 29 "Increase value (0~352.5 deg.)" 30 "Increase value (0~352.5 deg.)" 31 "Increase value (0~352.5 deg.)" 32 "Increase value (0~352.5 deg.)" 33 "Increase value (0~352.5 deg.)" 34 "Increase value (0~352.5 deg.)" 35 "Increase value (0~352.5 deg.)" 36 "Increase value (0~352.5 deg.)" 37 "Increase value (0~352.5 deg.)" 38 "Increase value (0~352.5 deg.)" 39 "Increase value (0~352.5 deg.)" 40 "Increase value (0~352.5 deg.)" 41 "Increase value (0~352.5 deg.)" 42 "Increase value (0~352.5 deg.)" 43 "Increase value (0~352.5 deg.)" 44 "Increase value (0~352.5 deg.)" 45 "Increase value (0~352.5 deg.)" 46 "Increase value (0~352.5 deg.)" 47 "Increase value (0~352.5 deg.)" 255 "Invalid" ;
VAL_ 1228 TBT_Distance_Turn_Point 0 "0" 1 "0x0001~0xFFFE:distance" 65534 "0x0001~0xFFFE:distance" 65535 "Invalid" ;
VAL_ 1228 TBT_Scale 0 "Meter" 1 "Kilometer" 2 "Mile" 3 "Feet" 4 "yard" 15 "Invalid" ;
VAL_ 1228 TBT_Combined_Side_Street 0 "No Combined" 1 "Right Combined" 2 "Left combined" 3 "Bothside" 4 "Reserved" 5 "Reserved" 6 "Reserved" 7 "Reserved" 8 "Reserved" 9 "Reserved" 10 "Reserved" 11 "Reserved" 12 "Reserved" 13 "Reserved" 14 "Reserved" 15 "Invalid" ;
VAL_ 1228 TBT_DistancetoTurnPoint 0 "0" 1 "number of tuning point" 2 "number of tuning point" 3 "number of tuning point" 4 "number of tuning point" 5 "number of tuning point" 6 "number of tuning point" 7 "number of tuning point" 8 "number of tuning point" 9 "number of tuning point" 10 "Reserved" 11 "Reserved" 12 "Reserved" 13 "Reserved" 14 "Reserved" 15 "Invalid" ;
VAL_ 1228 TBT_Side_Street 65535 "Invalid" ;
VAL_ 1266 HU_LanguageInfo 0 "Off" 1 "Korea" 2 "English(US)" 3 "English(UK)" 4 "Simplified chinese" 5 "Traditional chinese" 6 "French(EU)" 7 "Spanish(EU)" 8 "Arabic" 9 "Czech" 10 "Danish" 11 "German" 12 "Italian" 13 "Dutch" 14 "Polish" 15 "Portuguese" 16 "Russain" 17 "Slovak" 18 "Swedish" 19 "Turkish" 20 "French(US)" 21 "Spanish(US)" 22 "English(India)" 23 "Norwegian" 24 "Finnish" 25 "Indonesian" 26 "Brazilian Portuguese" 27 "Malay" 28 "Hungarian" 29 "English (Australia)" 30 "Japanese" 31 "0x1F~0xFE:reserved" 254 "0x1F~0xFE:reserved" 255 "Invalid" ;
VAL_ 1266 HU_MuteStatus 0 "Off" 1 "Mute On" 2 "reserved" 3 "Invalid" ;
VAL_ 1266 HU_NaviStatus 0 "Booting" 1 "Normal Operation" 2 "No SD Card(Map)" 3 "Invalid" ;
VAL_ 1266 HU_NaviDisp 0 "Non_Navi" 1 "Navi" 2 "reserved" 3 "Invalid" ;
VAL_ 1266 HU_NaviCamSettingStatus 0 "Navi Camera Alert Setting Status" 1 "Navi Camera Alert Setting Status" 2 "Navi Camera Alert Setting Status" 3 "Navi Camera Alert Setting Status" 4 "Navi Camera Alert Setting Status" 5 "Navi Camera Alert Setting Status" 6 "Navi Camera Alert Setting Status" 7 "Navi Camera Alert Setting Status" 8 "Navi Camera Alert Setting Status" 9 "Navi Camera Alert Setting Status" 10 "Navi Camera Alert Setting Status" 11 "Navi Camera Alert Setting Status" 12 "Navi Camera Alert Setting Status" 13 "Navi Camera Alert Setting Status" 14 "Navi Camera Alert Setting Status" 15 "Navi Camera Alert Setting Status" 16 "Navi Camera Alert Setting Status" 17 "Navi Camera Alert Setting Status" 18 "Navi Camera Alert Setting Status" 19 "Navi Camera Alert Setting Status" 20 "Navi Camera Alert Setting Status" 21 "Navi Camera Alert Setting Status" 22 "Navi Camera Alert Setting Status" 23 "Navi Camera Alert Setting Status" 24 "Navi Camera Alert Setting Status" 25 "Navi Camera Alert Setting Status" 26 "Navi Camera Alert Setting Status" 27 "Navi Camera Alert Setting Status" 28 "Navi Camera Alert Setting Status" 29 "Navi Camera Alert Setting Status" 30 "Navi Camera Alert Setting Status" 31 "Navi Camera Alert Setting Status" 32 "0x20~0xFE:Reserved" 254 "0x20~0xFE:Reserved" 255 "Invalid" ;
VAL_ 1266 HU_VolumeStatus 63 "Invalid" ;
VAL_ 1230 HU_OpState_New 0 "Initial" 1 "iBox App" 2 "Reserved" 3 "Reserved" 4 "Reserved" 5 "Reserved" 6 "ZUNE" 7 "Juke Box" 8 "Bluetooth Audio" 9 "Reserved" 10 "AV OFF" 11 "AV PowerOFF" 12 "MY music (ripping)" 13 "Internet Radio(Pandora)" 14 "Internet Radio(Kaola FM)" 15 "JukeBox-video" 16 "Aha Radio" 17 "FM" 18 "FM1" 19 "FM2" 20 "AM" 21 "Reserved" 22 "Reserved" 23 "Reserved" 24 "FMA" 25 "AMA" 26 "Emergency Call" 27 "ACN" 28 "Center Call" 29 "Hyundai Emergency Services" 30 "Kia Emergency Services" 31 "Reserved" 32 "Reserved" 33 "FM(HD)" 34 "FM1(HD)" 35 "FM2(HD)" 36 "AM(HD)" 37 "FMA_OLD(Use 0x18)" 38 "AMA_OLD(Use 0x19)" 39 "Reserved" 40 "Reserved" 41 "Reserved" 42 "Mozen Incoming call" 43 "Mozen Active call" 44 "Mozen Hangup" 45 "Mozen outgoing call" 46 "Reserved" 47 "Reserved" 48 "Reserved" 49 "SXM" 50 "XM1" 51 "XM2" 52 "XM3" 53 "Reserved" 54 "DAB" 55 "DAB1" 56 "DAB2" 57 "DAB3" 58 "Reserved" 59 "SXM Receiving" 60 "SXM Signal Weak" 61 "Reserved" 62 "DAB Receiving" 63 "DAB Signal Weak" 64 "Reserved" 65 "DMB1 TV" 66 "ISDB-T" 67 "Reserved" 68 "Reserved" 69 "DMB TV" 70 "DMB Radio" 71 "DMB Searching" 72 "Reserved" 73 "Reserved" 74 "Reserved" 75 "DMB Receiving" 76 "DMB Signal Weak" 77 "Reserved" 78 "Reserved" 79 "Reserved" 80 "CD" 81 "CD Audio" 82 "CD MP3" 83 "Mixed CD (Audio)" 84 "DVD" 85 "Reserved" 86 "Reserved" 87 "Reserved" 88 "Reserved" 89 "Disc reading" 90 "Mirror Link" 91 "Car Life" 92 "Reserved" 93 "READING CD" 94 "LOADING CD" 95 "Reserved" 96 "Loading" 97 "iPod" 98 "USB" 99 "AUX(Use 0x6B 0x6C Instead)" 100 "USB Video" 101 "USB Music" 102 "Rear USB Video" 103 "Rear USB Audio" 104 "IPOD Reading" 105 "USB Reading" 106 "Reading Media" 107 "AUX-audio" 108 "AUX-video" 109 "Reserved" 110 "CarPlay" 111 "Android Auto" 112 "Reserved" 113 "Incoming call" 114 "Active call" 115 "Hangup" 116 "Last Call" 117 "Reserved" 118 "Reserved" 119 "Reserved" 120 "Reserved" 121 "Reserved" 122 "BlueLink Mode" 123 "MOZEN Mode for cubis -T" 124 "RSA" 125 "Baidu Music" 126 "QQ Music" 127 "Invalid" ;
VAL_ 1230 HU_FMFrequency_Offset_Type 0 "Offset Type 1(8750)" 1 "Offset Type 2(6000)" 2 "Reserved" 3 "Invalid" ;
VAL_ 1230 HU_User_Input 0 "Off" 1 "User Input" 2 "Reserved" 3 "Invalid" ;
VAL_ 1230 HU_Frequency_Unit 0 "Off (Not Display)" 1 "On (Display)" 2 "Reserved" 3 "Invalid" ;
VAL_ 1230 HU_Track_Number_New 0 "0x0x0~0x327:Track No." 807 "0x0x0~0x327:Track No." 65535 "Invalid" ;
VAL_ 1230 HU_Frequency_New 0 "0x0x0~0x1FFE:Refer to Signal Description" 8190 "0x0x0~0x1FFE:Refer to Signal Description" 8191 "invalid" ;
VAL_ 1230 FM_Decimal_Point 0 "Off" 1 "1 Digit under point" 2 "2 Digits under point" 3 "Invalid" ;
VAL_ 1600 NV_Display_TG 0 "off" 1 "on" 2 "not used" 3 "invalid" ;
VAL_ 1600 TBT_BarGraph100Level 0 "0x0x0~0x64:Physical value" 100 "0x0x0~0x64:Physical value" 254 "Not Displayed" 255 "initial value, invald" ;
VAL_ 1601 Navi_WarnDist_OverDec 0 "0" 1 "0x1~0xFFFD:distance" 65533 "0x1~0xFFFD:distance" 65533 "no display over decimal point" 65535 "invalid" ;
VAL_ 1601 Navi_WarnDist_Scale 0 "m" 1 "km" 2 "mile" 3 "feet" 4 "yard" 5 "reserved" 6 "reserved" 7 "reserved" 8 "reserved" 9 "reserved" 10 "reserved" 11 "reserved" 12 "reserved" 13 "reserved" 14 "reserved" 15 "invalid" ;
VAL_ 1601 Navi_WarnDist_UnderDec 0 "0" 1 "distance" 2 "distance" 3 "distance" 4 "distance" 5 "distance" 6 "distance" 7 "distance" 8 "distance" 9 "distance" 10 "reserved" 11 "reserved" 12 "reserved" 13 "reserved" 14 "no display under decimal point" 15 "invalid" ;
VAL_ 1255 Navi_OverSpdAlarm 0 "None" 1 "Alarm" 2 "reserved" 3 "Invalid" ;
VAL_ 1255 Navi_WarningZone2 0 "None" 1 "blindslope_continuous" 16 "blindslope_down" 17 "tunnel" 18 "underwater" 19 "uneven" 20 "unmanaged_railway_cross" 21 "zippass" 22 "slope_continuousdown" 23 "slope_up" 24 "slope_down" 25 "railway_managed" 26 "Village" 27 "audible warning" 28 "Hov lane" 29 "vehicle_limite" 30 "incident_icon" 31 "Invarid" 2 "cross wind" 3 "hillsidedangerous" 4 "hump_bridg" 5 "joint_left" 6 "joint_right" 7 "lowspeed" 8 "narrow_both" 9 "narrowbridge" 10 "narrow_left" 11 "narrow_right" 12 "rockfall_left" 13 "rockfall_right" 14 "slip" 15 "blindslope_up" ;
VAL_ 1255 Navi_NonSpdTrap 0 "None" 1 "Red Light Trap" 2 "Bus Only Trap" 3 "Cut In Trap" 4 "Parking_Stopping Trap" 5 "Overloaded Trap" 6 "Badloaded Trap" 7 "Shoulder Trap" 8 "Plate Recogn. Camera" 9 "Traffic Camera" 10 "Intersection Block Trap" 11 "Ramp Metering Trap" 12 "User Registered Camera" 13 "Others" 31 "Invalid" ;
VAL_ 1255 Navi_WarningZone3 0 "None" 1 "Traffic accident" 2 "Traffic jam" 3 "traffic control" 4 "dangerous" 5 "Road closure" 6 "Traffic police" 7 "Reserved" 8 "Reserved" 9 "Reserved" 10 "Reserved" 11 "Reserved" 12 "Reserved" 13 "Reserved" 14 "Reserved" 15 "Invalid" ;
VAL_ 1255 Navi_WarningZone 0 "None" 1 "Black Spot" 2 "School Zone" 3 "Falling Rocks" 4 "Railway Crossing" 5 "Foggy Area" 6 "Downhill" 7 "Roadkill" 8 "Speed Bump" 9 "Bottleneck" 10 "Under Construction" 15 "Invalid" ;
VAL_ 1255 Navi_CurveWarning 0 "None" 1 "Right" 2 "Left" 3 "Right Curve Continuously" 4 "Left Curve Continuously" 5 "Curve Continuously" 6 "Reserved" 7 "Reserved" 8 "Reserved" 9 "Reserved" 10 "Reserved" 11 "Reserved" 12 "Reserved" 13 "Reserved" 14 "Reserved" 15 "Invalid" ;
VAL_ 1255 Navi_SpdInfo_Type 0 "Off" 1 "FixedSpeedTrap" 2 "FixedSpeedTrapNoInfo" 3 "MobileSpeedTrap" 4 "MobileSpeedTrapNoInfo" 5 "SpeedRedlightTrap" 6 "SpeedRedlightTrapNoInfo" 7 "BusSpeedTrap" 8 "BusSpeedTrapNoInfo" 9 "SpeedLimitType1" 10 "SpeedLimitSchoolzoneType1" 11 "SpeedLimitType2" 12 "SpeedLimitSchoolzoneType2" 13 "EU Camera zone warning" 15 "Invalid" ;
VAL_ 1255 Navi_SpdLimit_Unit 0 "None" 1 "Kilometer" 2 "Mile" 3 "Invalid" ;
VAL_ 1255 Navi_SpdLimit_Type 0 "None" 1 "US" 2 "Canada" 3 "Invalid" ;
VAL_ 1255 Navi_SpdLimit 0 "None" 1 "0x01~0xFE:1~254" 254 "0x01~0xFE:1~254" 255 "Invalid" ;
VAL_ 1256 NV_EstDist_Unit 0 "meter" 1 "kilometer" 2 "mile" 3 "feet" 5 "Reserved" 6 "Reserved" 7 "Reserved" 8 "Reserved" 9 "Reserved" 10 "Reserved" 11 "Reserved" 12 "Reserved" 13 "Reserved" 14 "Reserved" 15 "invalid" 4 "yard" ;
VAL_ 1256 NV_EstMin 0 "minutes" 59 "minutes" 255 "invalid" ;
VAL_ 1256 NV_Azimuth 0 "Increase value (0~352.5 deg.)" 1 "Increase value (0~352.5 deg.)" 2 "Increase value (0~352.5 deg.)" 3 "Increase value (0~352.5 deg.)" 4 "Increase value (0~352.5 deg.)" 5 "Increase value (0~352.5 deg.)" 6 "Increase value (0~352.5 deg.)" 7 "Increase value (0~352.5 deg.)" 8 "Increase value (0~352.5 deg.)" 9 "Increase value (0~352.5 deg.)" 10 "Increase value (0~352.5 deg.)" 11 "Increase value (0~352.5 deg.)" 12 "Increase value (0~352.5 deg.)" 13 "Increase value (0~352.5 deg.)" 14 "Increase value (0~352.5 deg.)" 15 "Increase value (0~352.5 deg.)" 16 "Increase value (0~352.5 deg.)" 17 "Increase value (0~352.5 deg.)" 18 "Increase value (0~352.5 deg.)" 19 "Increase value (0~352.5 deg.)" 20 "Increase value (0~352.5 deg.)" 21 "Increase value (0~352.5 deg.)" 22 "Increase value (0~352.5 deg.)" 23 "Increase value (0~352.5 deg.)" 24 "Increase value (0~352.5 deg.)" 25 "Increase value (0~352.5 deg.)" 26 "Increase value (0~352.5 deg.)" 27 "Increase value (0~352.5 deg.)" 28 "Increase value (0~352.5 deg.)" 29 "Increase value (0~352.5 deg.)" 30 "Increase value (0~352.5 deg.)" 31 "Increase value (0~352.5 deg.)" 32 "Increase value (0~352.5 deg.)" 33 "Increase value (0~352.5 deg.)" 34 "Increase value (0~352.5 deg.)" 35 "Increase value (0~352.5 deg.)" 36 "Increase value (0~352.5 deg.)" 37 "Increase value (0~352.5 deg.)" 38 "Increase value (0~352.5 deg.)" 39 "Increase value (0~352.5 deg.)" 40 "Increase value (0~352.5 deg.)" 41 "Increase value (0~352.5 deg.)" 42 "Increase value (0~352.5 deg.)" 43 "Increase value (0~352.5 deg.)" 44 "Increase value (0~352.5 deg.)" 45 "Increase value (0~352.5 deg.)" 46 "Increase value (0~352.5 deg.)" 47 "Increase value (0~352.5 deg.)" 255 "Invalid" ;
VAL_ 1256 NV_EstDist_I 0 "0" 65534 "65534" 65535 "invalid" ;
VAL_ 1256 NV_EstDist_F 0 "physical distance" 1 "physical distance" 2 "physical distance" 3 "physical distance" 4 "physical distance" 5 "physical distance" 6 "physical distance" 7 "physical distance" 8 "physical distance" 9 "physical distance" 10 "Reserved" 11 "Reserved" 12 "Reserved" 13 "Reserved" 14 "Reserved" 15 "invalid" ;
VAL_ 1256 NV_EstPointType 0 "destination" 1 "waypoint1" 2 "waypoint2" 3 "waypoint3" 4 "waypoint4" 5 "reserved" 6 "reserved" 7 "reserved" 8 "reserved" 9 "reserved" 10 "reserved" 11 "reserved" 12 "reserved" 13 "reserved" 14 "reserved" 15 "invalid" ;
VAL_ 1256 NV_EstimTimeFormat 0 "None" 1 "12 hour" 2 "24 hour" 3 "Invalid" ;
VAL_ 1256 NV_EstimTimeType 0 "None" 1 "Estimate Time of Arrival" 2 "Remaining Time to Arrive" 3 "Invalid" ;
VAL_ 1256 NV_EstHour 0 "hour" 23 "hour" 255 "invalid" ;
VAL_ 1185 C_AstWindowCmdAVN 0 "No action" 1 "Manual Down" 2 "Manual Up" 3 "25% Open" 4 "50%Open" 5 "Auto Down" 6 "Auto Up" 7 "Invalid" ;
VAL_ 1185 C_StrgWhlHeatedCmdAVN 0 "Off" 1 "Heat 1st ON" 2 "Reserved" 3 "Invalid" ;
VAL_ 1185 C_RrDefoggerCmdAVN 0 "Off" 1 "On" 2 "Reserved" 3 "Invalid" ;
VAL_ 1185 C_AVNIMSButtonCmd 0 "Default" 1 "Memory P1 CMD" 2 "Memory P2 CMD" 3 "Memory P3 CMD" 4 "PBack P1 CMD" 5 "PBack P2 CMD" 6 "PBack P3 CMD" 7 "Invalid" ;
VAL_ 1185 C_RRWindowCmdAVN 0 "No action" 1 "Manual Down" 2 "Manual Up" 3 "25% Open" 4 "50% Open" 5 "Auto Down" 6 "Auto Up" 7 "Invalid" ;
VAL_ 1185 C_RLWindowCmdAVN 0 "No action" 1 "Manual Down" 2 "Manual Up" 3 "25% Open" 4 "50% Open" 5 "Auto Down" 6 "Auto UP" 7 "Invalid" ;
VAL_ 1185 C_BlindCmdAVN 0 "No Action" 1 "R_Blind Auto Open" 2 "R_Blind Auto Close" 3 "Stop" 4 "reserved" 5 "reserved" 6 "reserved" 7 "Invalid" ;
VAL_ 1185 C_GlassCmdAVN 0 "No Action" 1 "Glass Auto Open" 2 "Glass Auto Close" 3 "Glass Auto Tilt Up" 4 "Stop" 5 "reserved" 6 "reserved" 7 "Invalid" ;
VAL_ 1185 C_CluDispCmdAVN 0 "No Action" 1 "Oil consumption" 2 "Speed" 3 "TBT" 4 "Reserved" 5 "Reserved" 6 "Reserved" 7 "Invalid" ;
VAL_ 1185 C_DrvWindowCmdAVN 0 "No action" 1 "Manual Down" 2 "Manual Up" 3 "25% Open" 4 "50% Open" 5 "Auto Down" 6 "Auto Up" 7 "Invalid" ;
VAL_ 1185 C_PTGCNTLCmdAVN 0 "Close" 1 "Open" 2 "Reserved" 3 "Invalid" ;
VAL_ 1239 HU_VehiclePwr 0 "Key out or Audio OFF" 1 "Not used" 2 "ACC or Audio ON" 3 "KBD Wake-up" 4 "Not used" 5 "Not used" 6 "Not used" 7 "Not used" 8 "Not used" 9 "Not used" 10 "Not used" 11 "Not used" 12 "Not used" 13 "Not used" 14 "Not used" 15 "Invalid" ;
VAL_ 1183 HU_DATC_MainBlower 0 "DATC Off" 1 "0 level (Do not use)" 2 "1 level" 3 "2 level" 4 "3 level" 5 "4 level" 6 "5 level" 7 "6 level" 8 "7 level" 9 "8 level" 15 "Invalid" ;
VAL_ 1183 HU_DATC_FrontModeSet 0 "Reserved" 1 "VENT" 2 "BL" 3 "FLOOR" 4 "MIX" 5 "reserved" 6 "reserved" 7 "7 Mode DEF VENT" 8 "reserved" 9 "MODE DEF VENT FLOOR" 10 "7 Mode DEF" 11 "Reserved" 12 "Reserved" 13 "Reserved" 14 "Reserved" 15 "Invalid" ;
VAL_ 1183 HU_DATC_IntakeSet 0 "REC Off (Fresh On)" 1 "REC ON (Fresh Off" 2 "reserved" 3 "Invalid" ;
VAL_ 1183 HU_DATC_AutoSet 0 "reserved" 1 "AUTO ON" 2 "reserved" 3 "Invalid" ;
VAL_ 1183 HU_DATC_FrontDefog 0 "Defog Off" 1 "Defog On" 2 "reserved" 3 "Invalid" ;
VAL_ 1183 HU_DATC_AcSet 0 "AC Off" 1 "AC ON" 2 "reserved" 3 "Invalid" ;
VAL_ 1183 HU_DATC_AirCleaningSet 0 "Air Cleaning System Off" 1 "Air Cleaning System On" 2 "Air Cleaning System Not Support" 3 "Invalid" ;
VAL_ 1183 HU_DATC_MainBlowerUpDn 0 "Reserved" 1 "Up" 2 "Down" 3 "Invalid" ;
VAL_ 1183 HU_DATC_DrTempUpDn 0 "Reserved" 1 "Temp Up" 2 "Temp Down" 3 "Invalid" ;
VAL_ 1184 HU_DATC_DrTempSetC 0 "Blank" 1 "LO" 2 "PHY=HEX*0.5 + 14" 3 "PHY=HEX*0.5 + 14" 4 "PHY=HEX*0.5 + 14" 5 "PHY=HEX*0.5 + 14" 6 "PHY=HEX*0.5 + 14" 7 "PHY=HEX*0.5 + 14" 8 "PHY=HEX*0.5 + 14" 9 "PHY=HEX*0.5 + 14" 10 "PHY=HEX*0.5 + 14" 11 "PHY=HEX*0.5 + 14" 12 "PHY=HEX*0.5 + 14" 13 "PHY=HEX*0.5 + 14" 14 "PHY=HEX*0.5 + 14" 15 "PHY=HEX*0.5 + 14" 16 "PHY=HEX*0.5 + 14" 17 "PHY=HEX*0.5 + 14" 18 "PHY=HEX*0.5 + 14" 19 "PHY=HEX*0.5 + 14" 20 "PHY=HEX*0.5 + 14" 21 "PHY=HEX*0.5 + 14" 22 "PHY=HEX*0.5 + 14" 23 "PHY=HEX*0.5 + 14" 24 "PHY=HEX*0.5 + 14" 25 "PHY=HEX*0.5 + 14" 26 "PHY=HEX*0.5 + 14" 27 "PHY=HEX*0.5 + 14" 28 "PHY=HEX*0.5 + 14" 29 "PHY=HEX*0.5 + 14" 30 "PHY=HEX*0.5 + 14" 31 "PHY=HEX*0.5 + 14" 32 "PHY=HEX*0.5 + 14" 33 "PHY=HEX*0.5 + 14" 34 "PHY=HEX*0.5 + 14" 35 "PHY=HEX*0.5 + 14" 36 "PHY=HEX*0.5 + 14" 37 "0x25~0xFD:Reserved" 253 "0x25~0xFD:Reserved" 254 "HI" 255 "Invalid" ;
VAL_ 1184 HU_DATC_DrTempSetF 0 "Blank" 1 "LO" 2 "PHY=HEX*1 + 56" 3 "PHY=HEX*1 + 56" 4 "PHY=HEX*1 + 56" 5 "PHY=HEX*1 + 56" 6 "PHY=HEX*1 + 56" 7 "PHY=HEX*1 + 56" 8 "PHY=HEX*1 + 56" 9 "PHY=HEX*1 + 56" 10 "PHY=HEX*1 + 56" 11 "PHY=HEX*1 + 56" 12 "PHY=HEX*1 + 56" 13 "PHY=HEX*1 + 56" 14 "PHY=HEX*1 + 56" 15 "PHY=HEX*1 + 56" 16 "PHY=HEX*1 + 56" 17 "PHY=HEX*1 + 56" 18 "PHY=HEX*1 + 56" 19 "PHY=HEX*1 + 56" 20 "PHY=HEX*1 + 56" 21 "PHY=HEX*1 + 56" 22 "PHY=HEX*1 + 56" 23 "PHY=HEX*1 + 56" 24 "PHY=HEX*1 + 56" 25 "PHY=HEX*1 + 56" 26 "PHY=HEX*1 + 56" 27 "PHY=HEX*1 + 56" 28 "PHY=HEX*1 + 56" 29 "PHY=HEX*1 + 56" 30 "PHY=HEX*1 + 56" 31 "PHY=HEX*1 + 56" 32 "PHY=HEX*1 + 56" 33 "PHY=HEX*1 + 56" 34 "PHY=HEX*1 + 56" 35 "PHY=HEX*1 + 56" 36 "PHY=HEX*1 + 56" 37 "0x25~0xFD:Reserved" 253 "0x25~0xFD:Reserved" 254 "HI" 255 "Invalid" ;
VAL_ 1267 HU_PhoneActivity 0 "Deactivated" 1 "Activated" 2 "reserved" 3 "Invalid" ;
VAL_ 1267 HU_VRActivity 0 "Deactivated" 1 "Activated" 2 "reserved" 3 "Invalid" ;
VAL_ 1240 CF_AVN_ProfileIDRValue 0 "Default" 1 "Guest" 2 "Profile 1" 3 "Profile 2" 4 "reserved" 5 "reserved" 6 "reserved" 7 "reserved" 8 "reserved" 9 "reserved" 10 "reserved" 11 "reserved" 12 "reserved" 13 "reserved" 14 "reserved" 15 "Invalid" ;
VAL_ 1240 HU_AliveStatus 0 "Not Ready" 1 "On Mode" 2 "Head Unit Update Mode" 3 "Invalid" ;
VAL_ 1278 HU_Type 16 "AVN(Tuner DVD KOR)" 17 "AVN(Tuner DVD EUR)" 18 "AVN(Tuner DVD China)" 19 "AVN(Tuner DVD Japan)" 20 "AVN(Tuner DVD EUR)" 21 "AVN(Tuner CDP KOR)" 22 "AVN(Tuner CDP EUR)" 23 "AVN(Tuner CDP China)" 24 "AVN(Tuner CDP Japan)" 25 "AVN(Tuner CDP EUR)" 32 "AVNT (Open)" 33 "AVNT (Not open)" 48 "Economic Audio" 64 "Standard Audio (3.0 below)" 65 "Standard Audio 4.0" 66 "STD Audio-3.0Below,No interwork" 67 "Audio 4.0 Value" 80 "AV(Tuner DVD KOR)" 81 "AV(Tuner DVD EUR)" 82 "AV(Tuner DVD China)" 83 "AV(Tuner DVD Japan)" 84 "AV(Tuner DVD EUR)" 85 "AV(Tuner CDP KOR)" 86 "AV(Tuner CDP EUR)" 87 "AV(Tuner CDP China)" 88 "AV(Tuner CDP Japan)" 89 "AV(Tuner CDP EUR)" 96 "AVN 4.0" 97 "Premium AVN2.0" 98 "EU AVN 2.0" 99 "Super Premium w Navi" 100 "Super Premium w_o Navi" 101 "Premium w Navi" 102 "Premium w_o Navi" 103 "Display Audio w_o Navi" 104 "Integrated AVN 1.0 Mobis" 105 "Gen5 Standard Nav Wide" 112 "Compact AVN & Integrated AVN 1.0 LG" 128 "Premium Navi 5th Gen(w_Navi)" 129 "Premium Navi 5th Gen(w_o Navi)" 130 "Premium Navi 6th Gen(w_Navi)" 131 "Premium Navi 6th Gen(w_o Navi)" 250 "PIO AVN" 251 "China only OEM AV" 252 "China OPIO w_o CLU interface" 253 "China OPIO w_CLU interface" 254 "China OEM AVNT" 255 "Invalid" ;
VAL_ 1278 HU_DistributeInfo 0 "Default (Korea)" 1 "Korea" 2 "North America" 3 "Canada" 4 "East Europe" 5 "West Europe" 6 "China" 7 "India" 8 "Australia" 9 "Middle East" 10 "Africa" 11 "South America" 12 "Russia" 13 "Reserved" 14 "General" 15 "0x0F~0xFE:Reserved" 254 "0x0F~0xFE:Reserved" 255 "Invalid" ;
VAL_ 1278 HU_OptionInfo 32768 "Invalid" ;
VAL_ 1278 HU_AdasSupport 0 "Not Support" 1 "ADAS Support(General Map)" 2 "ADAS Support(Precise Map v1)" 3 "ADAS Support(Precise Map v2)" 4 "Reserved" 5 "Reserved" 6 "Reserved" 7 "Invalid" ;
VAL_ 1246 POS_V2_Offset 0 "0x0x0~0x1FFE:Distance" 8190 "0x0x0~0x1FFE:Distance" 8191 "Invalid" ;
VAL_ 1246 POS_V2_CyclicCounter 0 "Cyclic Counter" 1 "Cyclic Counter" 2 "Cyclic Counter" 3 "Cyclic Counter" ;
VAL_ 1246 POS_V2_RangeAvgSpeed 0 "0x0x0~0xFD:Range Camera Average Speed" 253 "0x0x0~0xFD:Range Camera Average Speed" 254 "0xFE~0x1FE:Reserved" 510 "0xFE~0x1FE:Reserved" 511 "Invalid" ;
VAL_ 1208 PROLONG_V2_Value 0 "0x0x0~0xFFFFFFFE:Profile value at Offset" 2147483647 "0x0x0~0xFFFFFFFE:Profile value at Offset" 2147483647 "Invalid" ;
VAL_ 1208 PROLONG_V2_Offset 0 "0x0x0~0x1FFE:Distance" 8190 "0x0x0~0x1FFE:Distance" 8191 "Invalid" ;
VAL_ 1208 PROLONG_V2_CyclicCounter 0 "Cyclic Counter" 1 "Cyclic Counter" 2 "Cyclic Counter" 3 "Cyclic Counter" ;
VAL_ 1208 PROLONG_V2_Update 0 "False" 1 "True" ;
VAL_ 1208 PROLONG_V2_ProfileType 0 "Invalid" 1 "Longitude" 2 "Latitude" 3 "Altitude" 4 "Control Point Longitude(Bezier)" 5 "Control Point Latitude(Bezier)" 6 "Control Point Altitude(Bezier)" 7 "Link Identifier" 8 "Traffic Sign" 9 "Reserved for standard type" 10 "Reserved for standard type" 11 "Reserved for standard type" 12 "Reserved for standard type" 13 "Reserved for standard type" 14 "Reserved for standard type" 15 "Reserved for standard type" 16 "Alert Information Spot" 17 "Reserved for system specific types" 18 "Reserved for system specific types" 19 "Reserved for system specific types" 20 "Reserved for system specific types" 21 "Reserved for system specific types" 22 "Reserved for system specific types" 23 "Reserved for system specific types" 24 "Reserved for system specific types" 25 "Reserved for system specific types" 26 "Reserved for system specific types" 27 "Reserved for system specific types" 28 "Reserved for system specific types" 29 "Reserved for system specific types" 30 "Reserved for system specific types" 31 "Reserved for system specific types" ;
VAL_ 1207 PROSHORT_V2_Offset 0 "0x0x0~0x1FFE:Distance" 8190 "0x0x0~0x1FFE:Distance" 8191 "Invalid" ;
VAL_ 1207 PROSHORT_V2_CyclicCounter 0 "Cyclic Counter" 1 "Cyclic Counter" 2 "Cyclic Counter" 3 "Cyclic Counter" ;
VAL_ 1207 PROSHORT_V2_Distance 0 "0x0x0~0x3FE:Distance" 1022 "0x0x0~0x3FE:Distance" 1023 "Invalid" ;
VAL_ 1207 PROSHORT_V2_Value0 0 "0x0x0~0x3FE:Profile Vaue at Offset" 1022 "0x0x0~0x3FE:Profile Vaue at Offset" 1023 "Invalid" ;
VAL_ 1207 PROSHORT_V2_Value1 0 "0x0x0~0x3FE:Profile value at Offset+Distance1" 1022 "0x0x0~0x3FE:Profile value at Offset+Distance1" 1023 "Invalid" ;
VAL_ 1207 PROSHORT_V2_ProfileType 0 "Invalid" 1 "Curvature" 16 "Alert Information Section" 17 "Alert Information Section 2" 18 "Reserved for system specific types" 19 "Reserved for system specific types" 20 "Reserved for system specific types" 21 "Reserved for system specific types" 22 "Reserved for system specific types" 23 "Reserved for system specific types" 24 "Reserved for system specific types" 25 "Reserved for system specific types" 26 "Reserved for system specific types" 27 "Reserved for system specific types" 28 "Reserved for system specific types" 29 "Reserved for system specific types" 30 "Reserved for system specific types" 31 "Reserved for system specific types" 2 "Route Number types" 3 "Slope(step)" 4 "Slope(Linear)" 5 "Road Accessibility" 6 "Road condition" 7 "Variable Speed Sign Position" 8 "Heading Change" 9 "Reserved for standard type" 10 "Reserved for standard type" 11 "Reserved for standard type" 12 "Reserved for standard type" 13 "Reserved for standard type" 14 "Reserved for standard type" 15 "Reserved for standard type" ;
VAL_ 1204 SEG_V2_Offset 0 "0x0x0~0x1FFE:Distance" 8190 "0x0x0~0x1FFE:Distance" 8191 "Invalid" ;
VAL_ 1204 SEG_V2_CyclicCounter 0 "Cyclic Counter" 1 "Cyclic Counter" 2 "Cyclic Counter" 3 "Cyclic Counter" ;
VAL_ 1204 SEG_V2_Retransmission 0 "False" 1 "True" ;
VAL_ 1204 SEG_V2_CalculatedRoute 0 "Not Calculated Route(MPP)" 1 "Part of Calculated Route" 2 "Off Route or Recalculating" 3 "Invalid" ;
VAL_ 1204 SEG_V2_FuncRoadClass 0 "Unknown" 1 "Freeway" 2 "Arterial(City freeway)" 3 "County" 4 "Collector" 5 "Local" 6 "Etc(ferry, unpaved)" 7 "Invalid" ;
VAL_ 1204 SEG_V2_SpeedLimit 0 "Unknown" 1 "Under 5kph(mph)" 2 "7kph(mph)" 3 "10kph(mph)" 4 "15kph(mph)" 5 "20kph(mph)" 6 "25kph(mph)" 7 "30kph(mph)" 8 "35kph(mph)" 9 "40kph(mph)" 10 "45kph(mph)" 11 "50kph(mph)" 12 "55kph(mph)" 13 "60kph(mph)" 14 "65kph(mph)" 15 "70kph(mph)" 16 "75kph(mph)" 17 "80kph(mph)" 18 "85kph(mph)" 19 "90kph(mph)" 20 "95kph(mph)" 21 "100kph(mph)" 22 "105kph(mph)" 23 "110kph(mph)" 24 "115kph(mph)" 25 "120kph(mph)" 26 "130kph(mph)" 27 "140kph(mph)" 28 "150kph(mph)" 29 "160kph(mph)" 30 "Unlimited" 31 "Invalid" ;
VAL_ 1204 SEG_V2_FormOfWay 0 "Unkonwn" 1 "Main road(nondisjunction)" 2 "Main road(disjunction)" 3 "JC" 4 "Plural Junction M" 5 "IC" 6 "Reserved" 7 "Service Area" 8 "Reserved" 9 "Roundabout" 10 "P turn" 11 "U trun" 12 "Pedestrian" 13 "Frontage Road" 14 "Intersection internal(Plural Junction)" 15 "Invalid" ;
VAL_ 1204 SEG_V2_DirectionLanes 0 "Unknown" 1 "Lane count" 2 "Lane count" 3 "Lane count" 4 "Lane count" 5 "Lane count" 6 "Lane count" 7 "Lane count" 8 "Lane count" 9 "Lane count" 10 "Lane count" 11 "Lane count" 12 "Lane count" 13 "Lane count" 14 "Lane count" 15 "Invalid" ;
VAL_ 1204 SEG_V2_SpeedLimitUnder5 0 "0kph(mph)" 1 "1kph(mph)" 2 "2kph(mph)" 3 "3kph(mph)" 4 "4kph(mph)" 5 "reserved" 6 "reserved" 7 "Invalid" ;
VAL_ 1187 Navi_ISLW_LinkClass 0 "Unknown" 1 "Freeway" 2 "IC" 3 "JC" 4 "Restarea" 5 "Arterial_Country" 6 "Roundabout" 7 "Invalid" ;
VAL_ 1187 Navi_ISLW_CountryCode 0 "Unknown" 1 "0x1~0x3FE:ISO 3166-1 numeric values" 1022 "0x1~0x3FE:ISO 3166-1 numeric values" 1023 "Invalid" ;
VAL_ 1187 Navi_ISLW_MapSource 0 "None" 1 "Navteq" 2 "TomTom" 3 "Reserved" 4 "Reserved" 5 "Reserved" 6 "Reserved" 7 "Invalid" ;
VAL_ 1187 Navi_ISLW_Frwinfo 0 "None" 1 "Entrance" 2 "Exit" 3 "Branch" 4 "Restarea" 7 "Invalid" ;
VAL_ 1187 Navi_ISLW_TollExist 0 "None" 1 "Normal Toll" 2 "Elect Toll" 3 "Invalid" ;
VAL_ 1187 Navi_ISLW_TunnelExist 0 "None" 1 "Exist" 2 "Reserved" 3 "Invalid" ;
VAL_ 1187 Navi_ISLW_TimeSpd 0 "None" 1 "0x01~0xFD:1~253" 253 "0x01~0xFD:1~253" 254 "Unlimited" 255 "Invalid" ;
VAL_ 1187 Navi_ISLW_SpdUnit 0 "None" 1 "KPH" 2 "MPH" 3 "Invalid" ;
VAL_ 1187 Navi_ISLW_SpdLimit 0 "None" 1 "0x01~0xFD:1~253" 253 "0x01~0xFD:1~253" 254 "Unlimited" 255 "Invalid" ;
VAL_ 1192 CF_AVN_FCANValueSet 0 "Default(None FCA)" 1 "Off" 2 "Warning" 3 "Assist" 4 "Reserved" 5 "Reserved" 6 "Reserved" 7 "Invalid" ;
VAL_ 1192 CF_AVN_HDANValueSet 0 "Default" 1 "Off" 2 "On" 3 "Invalid" ;
VAL_ 1192 CF_AVN_SEANValueSet 0 "Default" 1 "Disable" 2 "Enable" 3 "Invalid" ;
VAL_ 1192 CF_AVN_NSCCCamNValueSet 0 "Default" 1 "Disable" 2 "Enable" 3 "Invalid" ;
VAL_ 1192 CF_AVN_BCANValueSet 0 "Default" 1 "Off" 2 "Warning" 3 "Assist" 4 "Reserved" 5 "Reserved" 6 "Reserved" 7 "Invalid" ;
VAL_ 1192 CF_AVN_ISLWNValueSet 0 "Default" 1 "Off" 2 "Warning" 3 "Invalid" ;
VAL_ 1192 CF_AVN_WarningTimingNValueSet 0 "Default" 1 "Late" 2 "Normal" 3 "Reserved" 4 "Reserved" 5 "Reserved" 6 "Reserved" 7 "Invalid" ;
VAL_ 1192 CF_AVN_NSCCCrvNValueSet 0 "Default" 1 "Disable" 2 "Enable" 3 "Invalid" ;
VAL_ 1192 CF_AVN_BCWSndWanNValueSet 0 "Off" 1 "Disable" 2 "Enable" 3 "Invalid" ;
VAL_ 1192 CF_AVN_RCCWNValueSet 0 "Default" 1 "Off" 2 "Warning" 3 "Invalid" ;
VAL_ 1192 CF_AVN_LkaModeNValueSet 0 "Default" 1 "LDW mode" 2 "LKA" 3 "Reserved" 4 "LDW Only ON(None LKA)" 5 "LDW only OFF" 6 "LDW_LKA OFF" 7 "Invalid" ;
VAL_ 1192 CF_AVN_AdasVolumeNValueSet 0 "Default" 1 "Level 1" 2 "Level 2" 3 "Level 3" 4 "Reserved" 5 "Reserved" 6 "Off" 7 "Invalid" ;
VAL_ 1192 CF_AVN_SCCDrvModeNValueSet 0 "Default" 1 "Comfort" 2 "Normal" 3 "Dynamic" 4 "Reserved" 5 "Reserved" 6 "Reserved" 7 "Invalid" ;
VAL_ 1195 CF_AVN_CluWelcomeSnd 0 "Default" 1 "Off" 2 "On" 3 "Invalid" ;
VAL_ 1195 CF_AVN_CluTransmissionDisp 0 "Default" 1 "Off" 2 "On" 3 "Invalid" ;
VAL_ 1195 CF_AVN_CluWiperLight 0 "Default" 1 "Off" 2 "On" 3 "Invalid" ;
VAL_ 1195 CF_AVN_CluRoadInfoGuide 0 "Default" 1 "Off" 2 "On" 3 "Invalid" ;
VAL_ 1195 CF_AVN_CluUserSettingPeriod 0 "0~99month" 1 "0~99month" 2 "0~99month" 3 "0~99month" 4 "0~99month" 5 "0~99month" 6 "0~99month" 7 "0~99month" 8 "0~99month" 9 "0~99month" 10 "0~99month" 11 "0~99month" 12 "0~99month" 13 "0~99month" 14 "0~99month" 15 "0~99month" 16 "0~99month" 17 "0~99month" 18 "0~99month" 19 "0~99month" 20 "0~99month" 21 "0~99month" 22 "0~99month" 23 "0~99month" 24 "0~99month" 25 "0~99month" 26 "0~99month" 27 "0~99month" 28 "0~99month" 29 "0~99month" 30 "0~99month" 31 "0~99month" 32 "0~99month" 33 "0~99month" 34 "0~99month" 35 "0~99month" 36 "0~99month" 37 "0~99month" 38 "0~99month" 39 "0~99month" 40 "0~99month" 41 "0~99month" 42 "0~99month" 43 "0~99month" 44 "0~99month" 45 "0~99month" 46 "0~99month" 47 "0~99month" 48 "0~99month" 49 "0~99month" 50 "0~99month" 51 "0~99month" 52 "0~99month" 53 "0~99month" 54 "0~99month" 55 "0~99month" 56 "0~99month" 57 "0~99month" 58 "0~99month" 59 "0~99month" 60 "0~99month" 61 "0~99month" 62 "0~99month" 63 "0~99month" 64 "0~99month" 65 "0~99month" 66 "0~99month" 67 "0~99month" 68 "0~99month" 69 "0~99month" 70 "0~99month" 71 "0~99month" 72 "0~99month" 73 "0~99month" 74 "0~99month" 75 "0~99month" 76 "0~99month" 77 "0~99month" 78 "0~99month" 79 "0~99month" 80 "0~99month" 81 "0~99month" 82 "0~99month" 83 "0~99month" 84 "0~99month" 85 "0~99month" 86 "0~99month" 87 "0~99month" 88 "0~99month" 89 "0~99month" 90 "0~99month" 91 "0~99month" 92 "0~99month" 93 "0~99month" 94 "0~99month" 95 "0~99month" 96 "0~99month" 97 "0~99month" 98 "0~99month" 99 "0~99month" 100 "Reserved" 101 "Reserved" 102 "Reserved" 103 "Reserved" 104 "Reserved" 105 "Reserved" 106 "Reserved" 107 "Reserved" 108 "Reserved" 109 "Reserved" 110 "Reserved" 111 "Reserved" 112 "Reserved" 113 "Reserved" 114 "Reserved" 115 "Reserved" 116 "Reserved" 117 "Reserved" 118 "Reserved" 119 "Reserved" 120 "Reserved" 121 "Reserved" 122 "Reserved" 123 "Reserved" 124 "Reserved" 125 "Reserved" 126 "Reserved" 127 "Invalid" ;
VAL_ 1195 CF_AVN_CluAutoInitFuelEconomy 0 "Default" 1 "Off" 2 "Driving" 3 "Refuel" 4 "Reserved" 5 "Reserved" 6 "Reserved" 7 "Invalid" ;
VAL_ 1195 CF_AVN_CluSubspeedOdometerDisp 0 "Default" 1 "Off" 2 "On" 3 "Invalid" ;
VAL_ 1195 CF_AVN_CluFuelEconUnit_mi 0 "Default" 1 "US gallon" 2 "UK gallon" 3 "Reserved" ;
VAL_ 1195 CF_AVN_CluFuelEconUnit_km 0 "Default" 1 "km_L" 2 "L_100km" 3 "Reserved" ;
VAL_ 1195 CF_AVN_CluUserSettingDistance 0 "0x0x0~0x1869F:0~9999km_mi" 99999 "0x0x0~0x1869F:0~9999km_mi" 131071 "Invalid" ;
VAL_ 1195 CF_AVN_CluRheostatLvl 0 "Reserved" 1 "Step 1" 2 "Step 2" 3 "Step 3" 4 "Step 4" 5 "Step 5" 6 "Step 6" 7 "Step 7" 8 "Step 8" 9 "Step 9" 10 "Step 10" 11 "Step 11" 12 "Step 12" 13 "Step 13" 14 "Step 14" 15 "Step 15" 16 "Step 16" 17 "Step 17" 18 "Step 18" 19 "Step 19" 20 "Step 20(Reset Value)" 21 "Step 21(Detent)" 22 "Reserved" 23 "Reserved" 24 "Reserved" 25 "Reserved" 26 "Reserved" 27 "Reserved" 28 "Reserved" 29 "Reserved" 30 "Reserved" 31 "Invalid" ;
VAL_ 1195 CF_AVN_CluVoiceVolume 0 "Default" 1 "Level0" 2 "Level1" 3 "Level2" 4 "Level3" 5 "Reserved" 6 "Reserved" 7 "Invalid" ;
VAL_ 1195 CF_AVN_UnitReset 0 "Default" 1 "Unit Reset" 2 "Reserved" 3 "Invalid" ;
VAL_ 1195 CF_AVN_CluServiceReminderReset 0 "Default" 1 "Service Reminder Reset" 2 "Reserved" 3 "Invalid" ;
VAL_ 1195 CF_AVN_CluUSMReset 0 "Default" 1 "USM Reset" 2 "Reserved" 3 "Invalid" ;
VAL_ 1195 CF_AVN_CluServiceReminderSet 0 "Default" 1 "Off" 2 "On" 3 "Invalid" ;
VAL_ 1197 CF_AVN_HBANValueSet 0 "Default" 1 "Off" 2 "On" 3 "Invalid" ;
VAL_ 1197 CF_AVN_DAWModeNValueSet_NEW 0 "Default" 1 "Off" 2 "On" 3 "Invalid" ;
VAL_ 1377 NMSleepFlag_CLU_MM 0 "Alive" 1 "SleepInd" 3 "SleepAck" ;
VAL_ 1377 NMCommandCode_CLU_MM 1 "Alive" 2 "Ring" 4 "Limphome" ;
VAL_ 1379 NMSleepFlag_H_U_MM 0 "Alive" 1 "SleepInd" 3 "SleepAck" ;
VAL_ 1379 NMCommandCode_H_U_MM 1 "Alive" 2 "Ring" 4 "Limphome" ;
VAL_ 1302 NMSleepFlag_CGW 0 "Alive" 1 "SleepInd" 3 "SleepAck" ;
VAL_ 1302 NMCommandCode_CGW 1 "Alive" 2 "Ring" 4 "Limphome" ;
